VERSION ""

NS_ :

BS_:

BU_:

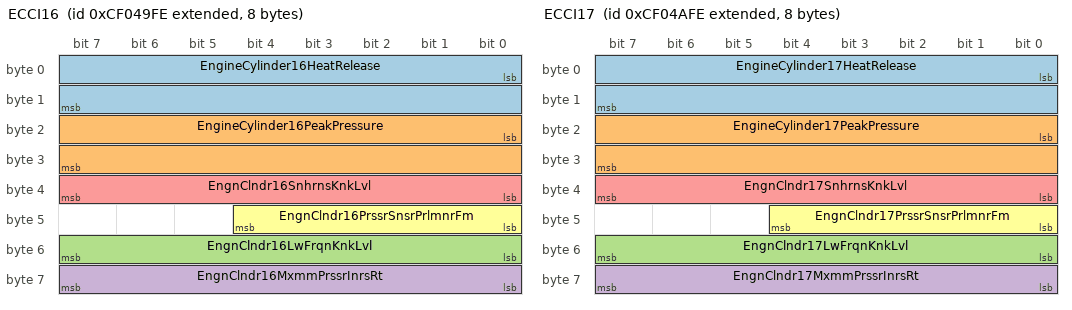
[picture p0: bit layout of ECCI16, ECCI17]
BO_ 2364557822 ECCI16: 8 Vector__XXX
 SG_ EngineCylinder16HeatRelease : 0|16@1+ (0.0001220703125,-1) [-1|6.8436279296875] "kJ/l" Vector__XXX
 SG_ EngineCylinder16PeakPressure : 16|16@1+ (0.0009765625,0) [0|62.7490234375] "MPa" Vector__XXX
 SG_ EngnClndr16LwFrqnKnkLvl : 48|8@1+ (1,0) [0|250] "%" Vector__XXX
 SG_ EngnClndr16MxmmPrssrInrsRt : 56|8@1+ (16,0) [0|4000] "kPa/deg crank angle" Vector__XXX
 SG_ EngnClndr16SnhrnsKnkLvl : 32|8@1+ (1,0) [0|250] "%" Vector__XXX
 SG_ EngnClndr16PrssrSnsrPrlmnrFm : 40|5@1+ (1,0) [0|31] "" Vector__XXX

BO_ 2364558078 ECCI17: 8 Vector__XXX
 SG_ EngineCylinder17HeatRelease : 0|16@1+ (0.0001220703125,-1) [-1|6.8436279296875] "kJ/l" Vector__XXX
 SG_ EngineCylinder17PeakPressure : 16|16@1+ (0.0009765625,0) [0|62.7490234375] "MPa" Vector__XXX
 SG_ EngnClndr17LwFrqnKnkLvl : 48|8@1+ (1,0) [0|250] "%" Vector__XXX
 SG_ EngnClndr17MxmmPrssrInrsRt : 56|8@1+ (16,0) [0|4000] "kPa/deg crank angle" Vector__XXX
 SG_ EngnClndr17SnhrnsKnkLvl : 32|8@1+ (1,0) [0|250] "%" Vector__XXX
 SG_ EngnClndr17PrssrSnsrPrlmnrFm : 40|5@1+ (1,0) [0|31] "" Vector__XXX

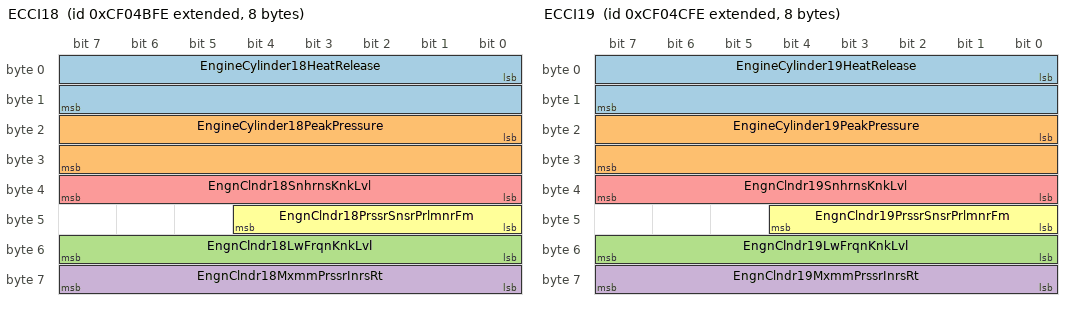
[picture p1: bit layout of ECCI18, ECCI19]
BO_ 2364558334 ECCI18: 8 Vector__XXX
 SG_ EngineCylinder18HeatRelease : 0|16@1+ (0.0001220703125,-1) [-1|6.8436279296875] "kJ/l" Vector__XXX
 SG_ EngineCylinder18PeakPressure : 16|16@1+ (0.0009765625,0) [0|62.7490234375] "MPa" Vector__XXX
 SG_ EngnClndr18LwFrqnKnkLvl : 48|8@1+ (1,0) [0|250] "%" Vector__XXX
 SG_ EngnClndr18MxmmPrssrInrsRt : 56|8@1+ (16,0) [0|4000] "kPa/deg crank angle" Vector__XXX
 SG_ EngnClndr18SnhrnsKnkLvl : 32|8@1+ (1,0) [0|250] "%" Vector__XXX
 SG_ EngnClndr18PrssrSnsrPrlmnrFm : 40|5@1+ (1,0) [0|31] "" Vector__XXX

BO_ 2364558590 ECCI19: 8 Vector__XXX
 SG_ EngineCylinder19HeatRelease : 0|16@1+ (0.0001220703125,-1) [-1|6.8436279296875] "kJ/l" Vector__XXX
 SG_ EngineCylinder19PeakPressure : 16|16@1+ (0.0009765625,0) [0|62.7490234375] "MPa" Vector__XXX
 SG_ EngnClndr19LwFrqnKnkLvl : 48|8@1+ (1,0) [0|250] "%" Vector__XXX
 SG_ EngnClndr19MxmmPrssrInrsRt : 56|8@1+ (16,0) [0|4000] "kPa/deg crank angle" Vector__XXX
 SG_ EngnClndr19SnhrnsKnkLvl : 32|8@1+ (1,0) [0|250] "%" Vector__XXX
 SG_ EngnClndr19PrssrSnsrPrlmnrFm : 40|5@1+ (1,0) [0|31] "" Vector__XXX

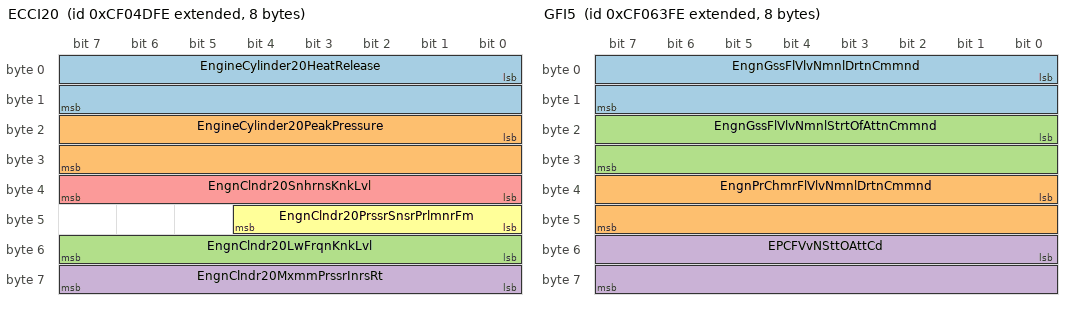
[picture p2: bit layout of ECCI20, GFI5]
BO_ 2364558846 ECCI20: 8 Vector__XXX
 SG_ EngineCylinder20HeatRelease : 0|16@1+ (0.0001220703125,-1) [-1|6.8436279296875] "kJ/l" Vector__XXX
 SG_ EngineCylinder20PeakPressure : 16|16@1+ (0.0009765625,0) [0|62.7490234375] "MPa" Vector__XXX
 SG_ EngnClndr20LwFrqnKnkLvl : 48|8@1+ (1,0) [0|250] "%" Vector__XXX
 SG_ EngnClndr20MxmmPrssrInrsRt : 56|8@1+ (16,0) [0|4000] "kPa/deg crank angle" Vector__XXX
 SG_ EngnClndr20SnhrnsKnkLvl : 32|8@1+ (1,0) [0|250] "%" Vector__XXX
 SG_ EngnClndr20PrssrSnsrPrlmnrFm : 40|5@1+ (1,0) [0|31] "" Vector__XXX

BO_ 2364564478 GFI5: 8 Vector__XXX
 SG_ EngnGssFlVlvNmnlDrtnCmmnd : 0|16@1+ (2,0) [0|128510] "micro s" Vector__XXX
 SG_ EngnPrChmrFlVlvNmnlDrtnCmmnd : 32|16@1+ (2,0) [0|128510] "micro s" Vector__XXX
 SG_ EngnGssFlVlvNmnlStrtOfAttnCmmnd : 16|16@1+ (0.0078125,-400) [-400|101.9921875] "deg" Vector__XXX
 SG_ EPCFVvNSttOAttCd : 48|16@1+ (0.0078125,-400) [-400|101.9921875] "deg" Vector__XXX

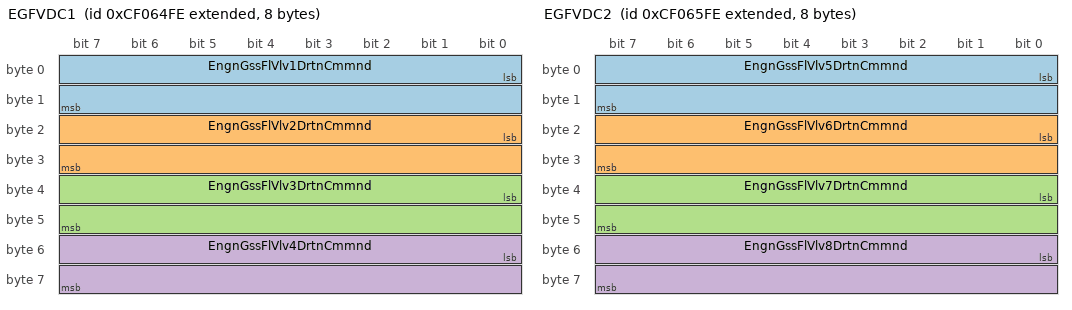
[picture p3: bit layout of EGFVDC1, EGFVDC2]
BO_ 2364564734 EGFVDC1: 8 Vector__XXX
 SG_ EngnGssFlVlv1DrtnCmmnd : 0|16@1+ (2,0) [0|128510] "micro s" Vector__XXX
 SG_ EngnGssFlVlv2DrtnCmmnd : 16|16@1+ (2,0) [0|128510] "micro s" Vector__XXX
 SG_ EngnGssFlVlv3DrtnCmmnd : 32|16@1+ (2,0) [0|128510] "micro s" Vector__XXX
 SG_ EngnGssFlVlv4DrtnCmmnd : 48|16@1+ (2,0) [0|128510] "micro s" Vector__XXX

BO_ 2364564990 EGFVDC2: 8 Vector__XXX
 SG_ EngnGssFlVlv5DrtnCmmnd : 0|16@1+ (2,0) [0|128510] "micro s" Vector__XXX
 SG_ EngnGssFlVlv6DrtnCmmnd : 16|16@1+ (2,0) [0|128510] "micro s" Vector__XXX
 SG_ EngnGssFlVlv7DrtnCmmnd : 32|16@1+ (2,0) [0|128510] "micro s" Vector__XXX
 SG_ EngnGssFlVlv8DrtnCmmnd : 48|16@1+ (2,0) [0|128510] "micro s" Vector__XXX

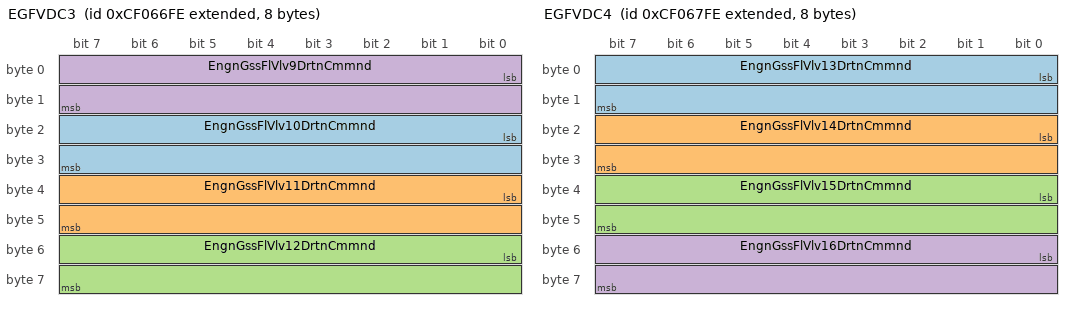
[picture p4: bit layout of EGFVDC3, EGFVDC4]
BO_ 2364565246 EGFVDC3: 8 Vector__XXX
 SG_ EngnGssFlVlv10DrtnCmmnd : 16|16@1+ (2,0) [0|128510] "micro s" Vector__XXX
 SG_ EngnGssFlVlv11DrtnCmmnd : 32|16@1+ (2,0) [0|128510] "micro s" Vector__XXX
 SG_ EngnGssFlVlv12DrtnCmmnd : 48|16@1+ (2,0) [0|128510] "micro s" Vector__XXX
 SG_ EngnGssFlVlv9DrtnCmmnd : 0|16@1+ (2,0) [0|128510] "micro s" Vector__XXX

BO_ 2364565502 EGFVDC4: 8 Vector__XXX
 SG_ EngnGssFlVlv13DrtnCmmnd : 0|16@1+ (2,0) [0|128510] "micro s" Vector__XXX
 SG_ EngnGssFlVlv14DrtnCmmnd : 16|16@1+ (2,0) [0|128510] "micro s" Vector__XXX
 SG_ EngnGssFlVlv15DrtnCmmnd : 32|16@1+ (2,0) [0|128510] "micro s" Vector__XXX
 SG_ EngnGssFlVlv16DrtnCmmnd : 48|16@1+ (2,0) [0|128510] "micro s" Vector__XXX

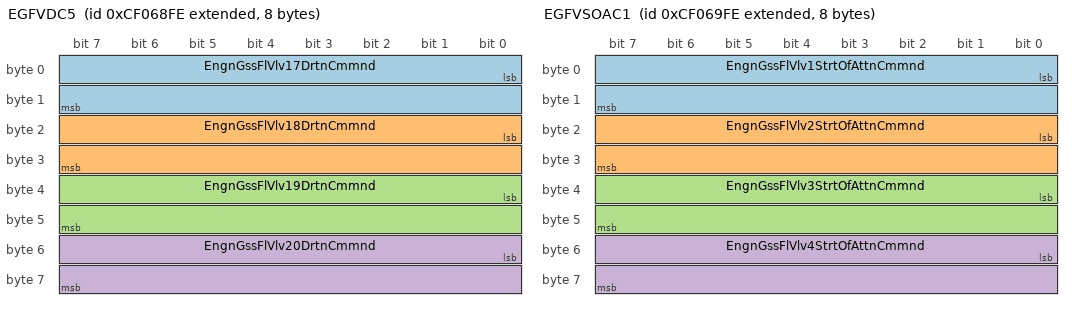
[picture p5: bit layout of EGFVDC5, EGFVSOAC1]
BO_ 2364565758 EGFVDC5: 8 Vector__XXX
 SG_ EngnGssFlVlv17DrtnCmmnd : 0|16@1+ (2,0) [0|128510] "micro s" Vector__XXX
 SG_ EngnGssFlVlv18DrtnCmmnd : 16|16@1+ (2,0) [0|128510] "micro s" Vector__XXX
 SG_ EngnGssFlVlv19DrtnCmmnd : 32|16@1+ (2,0) [0|128510] "micro s" Vector__XXX
 SG_ EngnGssFlVlv20DrtnCmmnd : 48|16@1+ (2,0) [0|128510] "micro s" Vector__XXX

BO_ 2364566014 EGFVSOAC1: 8 Vector__XXX
 SG_ EngnGssFlVlv1StrtOfAttnCmmnd : 0|16@1+ (0.0078125,-400) [-400|101.9921875] "deg" Vector__XXX
 SG_ EngnGssFlVlv2StrtOfAttnCmmnd : 16|16@1+ (0.0078125,-400) [-400|101.9921875] "deg" Vector__XXX
 SG_ EngnGssFlVlv3StrtOfAttnCmmnd : 32|16@1+ (0.0078125,-400) [-400|101.9921875] "deg" Vector__XXX
 SG_ EngnGssFlVlv4StrtOfAttnCmmnd : 48|16@1+ (0.0078125,-400) [-400|101.9921875] "deg" Vector__XXX

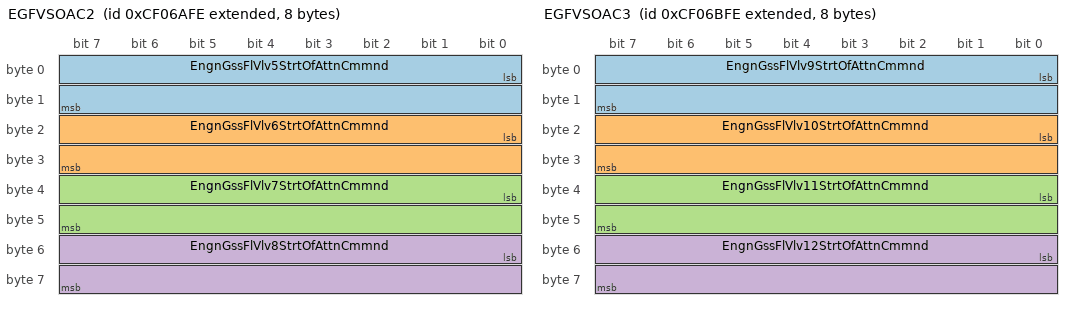
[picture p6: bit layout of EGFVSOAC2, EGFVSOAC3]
BO_ 2364566270 EGFVSOAC2: 8 Vector__XXX
 SG_ EngnGssFlVlv5StrtOfAttnCmmnd : 0|16@1+ (0.0078125,-400) [-400|101.9921875] "deg" Vector__XXX
 SG_ EngnGssFlVlv6StrtOfAttnCmmnd : 16|16@1+ (0.0078125,-400) [-400|101.9921875] "deg" Vector__XXX
 SG_ EngnGssFlVlv7StrtOfAttnCmmnd : 32|16@1+ (0.0078125,-400) [-400|101.9921875] "deg" Vector__XXX
 SG_ EngnGssFlVlv8StrtOfAttnCmmnd : 48|16@1+ (0.0078125,-400) [-400|101.9921875] "deg" Vector__XXX

BO_ 2364566526 EGFVSOAC3: 8 Vector__XXX
 SG_ EngnGssFlVlv9StrtOfAttnCmmnd : 0|16@1+ (0.0078125,-400) [-400|101.9921875] "deg" Vector__XXX
 SG_ EngnGssFlVlv10StrtOfAttnCmmnd : 16|16@1+ (0.0078125,-400) [-400|101.9921875] "deg" Vector__XXX
 SG_ EngnGssFlVlv11StrtOfAttnCmmnd : 32|16@1+ (0.0078125,-400) [-400|101.9921875] "deg" Vector__XXX
 SG_ EngnGssFlVlv12StrtOfAttnCmmnd : 48|16@1+ (0.0078125,-400) [-400|101.9921875] "deg" Vector__XXX

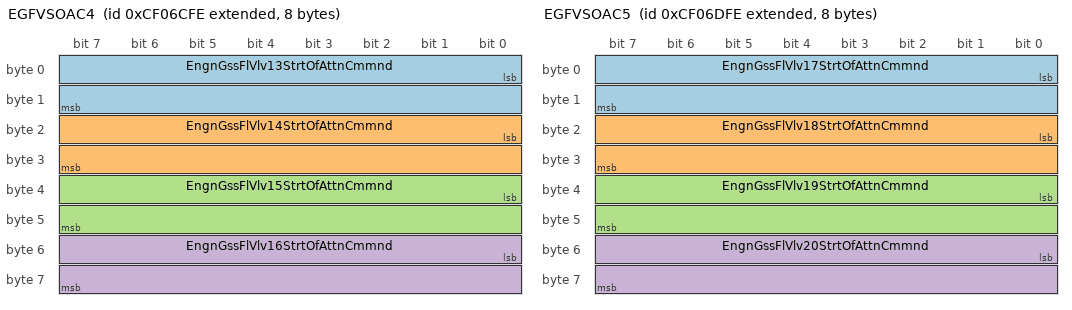
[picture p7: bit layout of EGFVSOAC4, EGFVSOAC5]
BO_ 2364566782 EGFVSOAC4: 8 Vector__XXX
 SG_ EngnGssFlVlv13StrtOfAttnCmmnd : 0|16@1+ (0.0078125,-400) [-400|101.9921875] "deg" Vector__XXX
 SG_ EngnGssFlVlv14StrtOfAttnCmmnd : 16|16@1+ (0.0078125,-400) [-400|101.9921875] "deg" Vector__XXX
 SG_ EngnGssFlVlv15StrtOfAttnCmmnd : 32|16@1+ (0.0078125,-400) [-400|101.9921875] "deg" Vector__XXX
 SG_ EngnGssFlVlv16StrtOfAttnCmmnd : 48|16@1+ (0.0078125,-400) [-400|101.9921875] "deg" Vector__XXX

BO_ 2364567038 EGFVSOAC5: 8 Vector__XXX
 SG_ EngnGssFlVlv17StrtOfAttnCmmnd : 0|16@1+ (0.0078125,-400) [-400|101.9921875] "deg" Vector__XXX
 SG_ EngnGssFlVlv18StrtOfAttnCmmnd : 16|16@1+ (0.0078125,-400) [-400|101.9921875] "deg" Vector__XXX
 SG_ EngnGssFlVlv19StrtOfAttnCmmnd : 32|16@1+ (0.0078125,-400) [-400|101.9921875] "deg" Vector__XXX
 SG_ EngnGssFlVlv20StrtOfAttnCmmnd : 48|16@1+ (0.0078125,-400) [-400|101.9921875] "deg" Vector__XXX

BO_ 2364567294 FPAC: 8 Vector__XXX
 SG_ EngnFlInjtnPmp1FlCntrlVlvCmmnd : 0|16@1+ (0.0025,0) [0|100] "%" Vector__XXX
 SG_ EngnFlInjtnPmp2FlCntrlVlvCmmnd : 16|16@1+ (0.0025,0) [0|100] "%" Vector__XXX

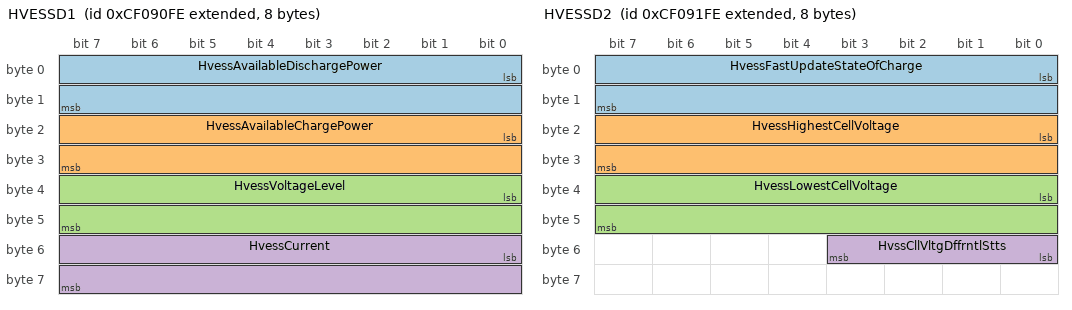
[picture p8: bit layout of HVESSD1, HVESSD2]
BO_ 2364575998 HVESSD1: 8 Vector__XXX
 SG_ HvessAvailableDischargePower : 0|16@1+ (0.05,0) [0|3212.75] "kW" Vector__XXX
 SG_ HvessAvailableChargePower : 16|16@1+ (0.05,0) [0|3212.75] "kW" Vector__XXX
 SG_ HvessVoltageLevel : 32|16@1+ (0.05,0) [0|3212.75] "V" Vector__XXX
 SG_ HvessCurrent : 48|16@1+ (0.05,-1600) [-1600|1612.75] "A" Vector__XXX

BO_ 2364576254 HVESSD2: 8 Vector__XXX
 SG_ HvessFastUpdateStateOfCharge : 0|16@1+ (0.0015625,0) [0|100.3984375] "%" Vector__XXX
 SG_ HvessHighestCellVoltage : 16|16@1+ (0.001,0) [0|64.255] "V" Vector__XXX
 SG_ HvessLowestCellVoltage : 32|16@1+ (0.001,0) [0|64.255] "V" Vector__XXX
 SG_ HvssCllVltgDffrntlStts : 48|4@1+ (1,0) [0|15] "" Vector__XXX

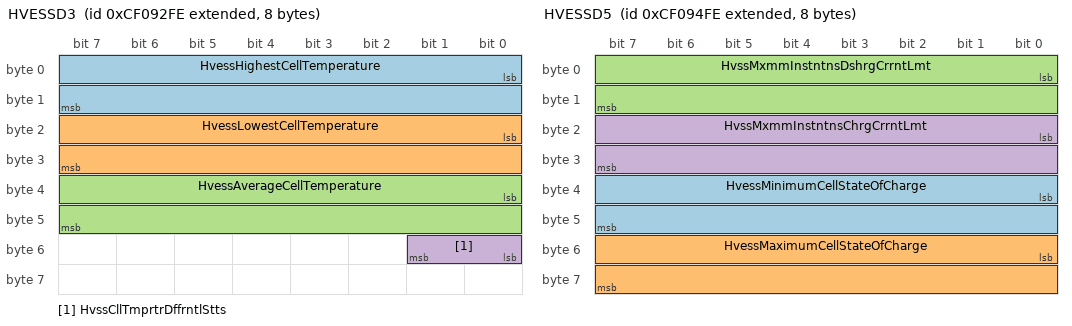
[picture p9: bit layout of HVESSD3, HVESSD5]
BO_ 2364576510 HVESSD3: 8 Vector__XXX
 SG_ HvessHighestCellTemperature : 0|16@1+ (0.03125,-273) [-273|1734.96875] "degC" Vector__XXX
 SG_ HvessLowestCellTemperature : 16|16@1+ (0.03125,-273) [-273|1734.96875] "degC" Vector__XXX
 SG_ HvessAverageCellTemperature : 32|16@1+ (0.03125,-273) [-273|1734.96875] "degC" Vector__XXX
 SG_ HvssCllTmprtrDffrntlStts : 48|2@1+ (1,0) [0|3] "" Vector__XXX

BO_ 2364576766 HVESSD4: 8 Vector__XXX
 SG_ HvessDischargeCapacity : 0|16@1+ (0.01,0) [0|642.55] "Ah" Vector__XXX
 SG_ HvessChargeCapacity : 16|16@1+ (0.01,0) [0|642.55] "Ah" Vector__XXX
 SG_ HvessCellBalancingCount : 32|16@1+ (1,0) [0|64255] "count" Vector__XXX

BO_ 2364577022 HVESSD5: 8 Vector__XXX
 SG_ HvessMinimumCellStateOfCharge : 32|16@1+ (0.0015625,0) [0|100.3984375] "%" Vector__XXX
 SG_ HvessMaximumCellStateOfCharge : 48|16@1+ (0.0015625,0) [0|100.3984375] "%" Vector__XXX
 SG_ HvssMxmmInstntnsDshrgCrrntLmt : 0|16@1+ (0.05,-1600) [-1600|0] "A" Vector__XXX
 SG_ HvssMxmmInstntnsChrgCrrntLmt : 16|16@1+ (0.05,-1600) [0|1612.75] "A" Vector__XXX

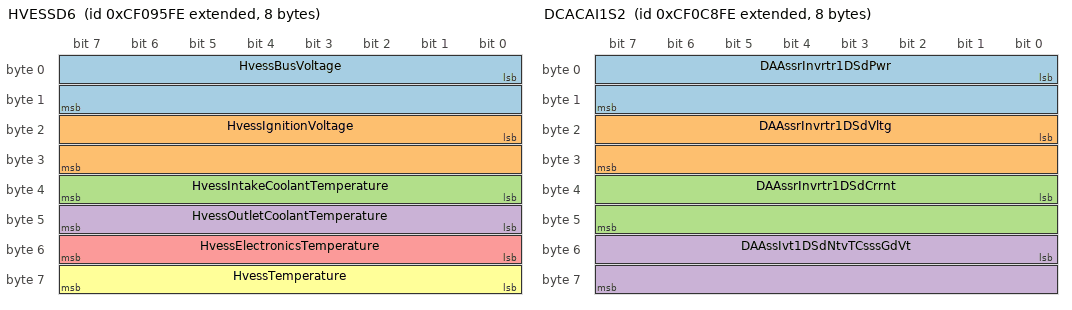
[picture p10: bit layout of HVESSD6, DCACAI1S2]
BO_ 2364577278 HVESSD6: 8 Vector__XXX
 SG_ HvessBusVoltage : 0|16@1+ (0.05,0) [0|3212.75] "V" Vector__XXX
 SG_ HvessIgnitionVoltage : 16|16@1+ (0.01,0) [0|642.55] "V" Vector__XXX
 SG_ HvessIntakeCoolantTemperature : 32|8@1+ (1,-40) [-40|210] "degC" Vector__XXX
 SG_ HvessOutletCoolantTemperature : 40|8@1+ (1,-40) [-40|210] "degC" Vector__XXX
 SG_ HvessElectronicsTemperature : 48|8@1+ (1,-40) [-40|210] "degC" Vector__XXX
 SG_ HvessTemperature : 56|8@1+ (1,-40) [-40|210] "degC" Vector__XXX

BO_ 2364577534 HVESSS1: 8 Vector__XXX
 SG_ HvessCenterOfPackContactorState : 10|2@1+ (1,0) [0|3] "" Vector__XXX
 SG_ HvessHvilStatus : 20|2@1+ (1,0) [0|3] "" Vector__XXX
 SG_ HvessInertiaSwitchStatus : 22|2@1+ (1,0) [0|3] "" Vector__XXX
 SG_ HvessStateOfChargeStatus : 24|4@1+ (1,0) [0|15] "" Vector__XXX
 SG_ HvessCellBalanceStatus : 28|2@1+ (1,0) [0|3] "" Vector__XXX
 SG_ HvessCellBalancingActive : 30|2@1+ (1,0) [0|3] "" Vector__XXX
 SG_ HvessInternalChargerStatus : 32|2@1+ (1,0) [0|3] "" Vector__XXX
 SG_ HvessOperationalStatus : 44|4@1+ (1,0) [0|15] "" Vector__XXX
 SG_ HvessNumberOfHvespsReady : 48|8@1+ (1,0) [0|250] "count" Vector__XXX
 SG_ HvessStatus1Counter : 36|4@1+ (1,0) [0|15] "" Vector__XXX
 SG_ HvessStatus1Crc : 56|8@1+ (1,0) [0|250] "count" Vector__XXX
 SG_ HvssHghVltgBsPstvCnttrStt : 0|2@1+ (1,0) [0|3] "" Vector__XXX
 SG_ HvssHghVltgBsNgtvCnttrStt : 2|2@1+ (1,0) [0|3] "" Vector__XXX
 SG_ HvssHghVltgBsDsnntFrwrnng : 4|4@1+ (1,0) [0|15] "" Vector__XXX
 SG_ HvssHghVltgBsPrChrgRlStt : 8|2@1+ (1,0) [0|3] "" Vector__XXX
 SG_ HvssHghVltgBsAtvIsltnTstStts : 12|4@1+ (1,0) [0|15] "" Vector__XXX
 SG_ HvssHghVltgBsPssvIsltnTstStts : 16|4@1+ (1,0) [0|15] "" Vector__XXX
 SG_ HvssHghVltgBsCnntnStts : 40|4@1+ (1,0) [0|15] "" Vector__XXX

BO_ 2364580094 HVESSD7: 8 Vector__XXX
 SG_ HvessDischargeEnergyCapacity : 0|24@1+ (0.001,0) [0|16449.535] "kWh" Vector__XXX
 SG_ HvessChargeEnergyCapacity : 24|24@1+ (0.001,0) [0|16449.535] "kWh" Vector__XXX
 SG_ HvessMaximumChargeVoltageLimit : 48|16@1+ (0.05,0) [0|3212.75] "V" Vector__XXX

BO_ 2364590334 DCACAI1S2: 8 Vector__XXX
 SG_ DAAssrInvrtr1DSdPwr : 0|16@1+ (0.0625,0) [0|4015.9375] "kW" Vector__XXX
 SG_ DAAssrInvrtr1DSdVltg : 16|16@1+ (0.05,0) [0|3212.75] "V" Vector__XXX
 SG_ DAAssrInvrtr1DSdCrrnt : 32|16@1+ (0.0625,0) [0|4015.9375] "A" Vector__XXX
 SG_ DAAssIvt1DSdNtvTCsssGdVt : 48|16@1+ (0.05,0) [0|3212.75] "V" Vector__XXX

BO_ 2364590590 DCACAI1V: 8 Vector__XXX
 SG_ DAAssrInvrtr1IgntnVltg : 0|16@1+ (0.05,0) [0|3212.75] "V" Vector__XXX
 SG_ DAAssrInvrtr1UnswthdSlVltg : 16|16@1+ (0.05,0) [0|3212.75] "V" Vector__XXX

BO_ 2364591102 DCACAI2S2: 8 Vector__XXX
 SG_ DAAssrInvrtr2DSdPwr : 0|16@1+ (0.0625,0) [0|4015.9375] "kW" Vector__XXX
 SG_ DAAssrInvrtr2DSdVltg : 16|16@1+ (0.05,0) [0|3212.75] "V" Vector__XXX
 SG_ DAAssrInvrtr2DSdCrrnt : 32|16@1+ (0.0625,0) [0|4015.9375] "A" Vector__XXX
 SG_ DAAssIvt2DSdNtvTCsssGdVt : 48|16@1+ (0.05,0) [0|3212.75] "V" Vector__XXX

BO_ 2364591358 DCACAI2V: 8 Vector__XXX
 SG_ DAAssrInvrtr2IgntnVltg : 0|16@1+ (0.05,0) [0|3212.75] "V" Vector__XXX
 SG_ DAAssrInvrtr2UnswthdSlVltg : 16|16@1+ (0.05,0) [0|3212.75] "V" Vector__XXX

BO_ 2364592382 ECCR: 8 Vector__XXX
 SG_ EngnClndr10ExldFrmCmstnRqst : 26|2@1+ (1,0) [0|3] "" Vector__XXX
 SG_ EngnClndr11ExldFrmCmstnRqst : 28|2@1+ (1,0) [0|3] "" Vector__XXX
 SG_ EngnClndr12ExldFrmCmstnRqst : 30|2@1+ (1,0) [0|3] "" Vector__XXX
 SG_ EngnClndr13ExldFrmCmstnRqst : 32|2@1+ (1,0) [0|3] "" Vector__XXX
 SG_ EngnClndr14ExldFrmCmstnRqst : 34|2@1+ (1,0) [0|3] "" Vector__XXX
 SG_ EngnClndr15ExldFrmCmstnRqst : 36|2@1+ (1,0) [0|3] "" Vector__XXX
 SG_ EngnClndr16ExldFrmCmstnRqst : 38|2@1+ (1,0) [0|3] "" Vector__XXX
 SG_ EngnClndr17ExldFrmCmstnRqst : 40|2@1+ (1,0) [0|3] "" Vector__XXX
 SG_ EngnClndr18ExldFrmCmstnRqst : 42|2@1+ (1,0) [0|3] "" Vector__XXX
 SG_ EngnClndr19ExldFrmCmstnRqst : 44|2@1+ (1,0) [0|3] "" Vector__XXX
 SG_ EngnClndr1ExldFrmCmstnRqst : 8|2@1+ (1,0) [0|3] "" Vector__XXX
 SG_ EngnClndr20ExldFrmCmstnRqst : 46|2@1+ (1,0) [0|3] "" Vector__XXX
 SG_ EngnClndr21ExldFrmCmstnRqst : 48|2@1+ (1,0) [0|3] "" Vector__XXX
 SG_ EngnClndr22ExldFrmCmstnRqst : 50|2@1+ (1,0) [0|3] "" Vector__XXX
 SG_ EngnClndr23ExldFrmCmstnRqst : 52|2@1+ (1,0) [0|3] "" Vector__XXX
 SG_ EngnClndr24ExldFrmCmstnRqst : 54|2@1+ (1,0) [0|3] "" Vector__XXX
 SG_ EngnClndr2ExldFrmCmstnRqst : 10|2@1+ (1,0) [0|3] "" Vector__XXX
 SG_ EngnClndr3ExldFrmCmstnRqst : 12|2@1+ (1,0) [0|3] "" Vector__XXX
 SG_ EngnClndr4ExldFrmCmstnRqst : 14|2@1+ (1,0) [0|3] "" Vector__XXX
 SG_ EngnClndr5ExldFrmCmstnRqst : 16|2@1+ (1,0) [0|3] "" Vector__XXX
 SG_ EngnClndr6ExldFrmCmstnRqst : 18|2@1+ (1,0) [0|3] "" Vector__XXX
 SG_ EngnClndr7ExldFrmCmstnRqst : 20|2@1+ (1,0) [0|3] "" Vector__XXX
 SG_ EngnClndr8ExldFrmCmstnRqst : 22|2@1+ (1,0) [0|3] "" Vector__XXX
 SG_ EngnClndr9ExldFrmCmstnRqst : 24|2@1+ (1,0) [0|3] "" Vector__XXX
 SG_ NmrOfEngnClndrsTExldFrmCmstn : 0|8@1+ (1,0) [0|24] "count" Vector__XXX

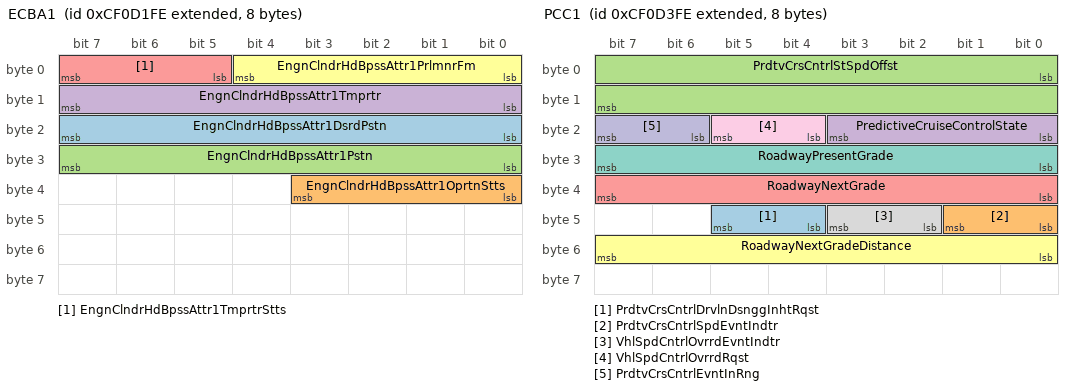
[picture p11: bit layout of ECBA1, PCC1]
BO_ 2364592638 ECBA1: 8 Vector__XXX
 SG_ EngnClndrHdBpssAttr1DsrdPstn : 16|8@1+ (0.4,0) [0|100] "%" Vector__XXX
 SG_ EngnClndrHdBpssAttr1OprtnStts : 32|4@1+ (1,0) [0|15] "" Vector__XXX
 SG_ EngnClndrHdBpssAttr1Pstn : 24|8@1+ (0.4,0) [0|100] "%" Vector__XXX
 SG_ EngnClndrHdBpssAttr1Tmprtr : 8|8@1+ (1,-40) [-40|210] "degC" Vector__XXX
 SG_ EngnClndrHdBpssAttr1TmprtrStts : 5|3@1+ (1,0) [0|7] "" Vector__XXX
 SG_ EngnClndrHdBpssAttr1PrlmnrFm : 0|5@1+ (1,0) [0|31] "" Vector__XXX

BO_ 2364592894 EEC18: 8 Vector__XXX
 SG_ EngineIntakeAirSourceValve : 16|2@1+ (1,0) [0|3] "" Vector__XXX
 SG_ EngnClndrHdBpssAttr1Cmmnd : 0|16@1+ (0.0025,0) [0|160.6375] "%" Vector__XXX
 SG_ EngnExhstGsRstrtnVlvPstn : 32|16@1+ (0.0025,0) [0|160.6375] "%" Vector__XXX

BO_ 2364593150 PCC1: 8 Vector__XXX
 SG_ PrdtvCrsCntrlDrvlnDsnggInhtRqst : 44|2@1+ (1,0) [0|3] "" Vector__XXX
 SG_ PrdtvCrsCntrlSpdEvntIndtr : 40|2@1+ (1,0) [0|3] "" Vector__XXX
 SG_ PrdtvCrsCntrlStSpdOffst : 0|16@1+ (0.00390625,-125) [-125|125.99609375] "km/h" Vector__XXX
 SG_ PredictiveCruiseControlState : 16|4@1+ (1,0) [0|15] "" Vector__XXX
 SG_ RoadwayNextGrade : 32|8@1+ (0.125,-16) [-16|15.25] "%" Vector__XXX
 SG_ RoadwayNextGradeDistance : 48|8@1+ (25,0) [0|6250] "m" Vector__XXX
 SG_ RoadwayPresentGrade : 24|8@1+ (0.125,-16) [-16|15.25] "%" Vector__XXX
 SG_ VhlSpdCntrlOvrrdEvntIndtr : 42|2@1+ (1,0) [0|3] "" Vector__XXX
 SG_ VhlSpdCntrlOvrrdRqst : 20|2@1+ (1,0) [0|3] "" Vector__XXX
 SG_ PrdtvCrsCntrlEvntInRng : 22|2@1+ (1,0) [0|3] "" Vector__XXX

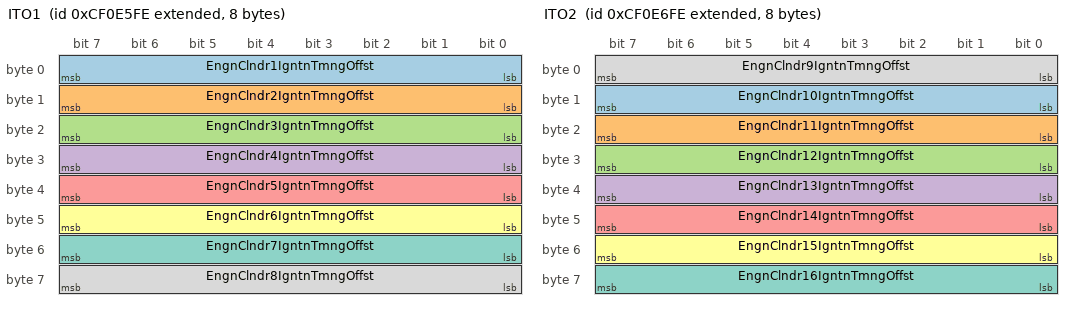
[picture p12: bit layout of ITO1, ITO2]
BO_ 2364597758 ITO1: 8 Vector__XXX
 SG_ EngnClndr1IgntnTmngOffst : 0|8@1+ (0.1,-12.5) [-12.5|12.5] "deg" Vector__XXX
 SG_ EngnClndr2IgntnTmngOffst : 8|8@1+ (0.1,-12.5) [-12.5|12.5] "deg" Vector__XXX
 SG_ EngnClndr3IgntnTmngOffst : 16|8@1+ (0.1,-12.5) [-12.5|12.5] "deg" Vector__XXX
 SG_ EngnClndr4IgntnTmngOffst : 24|8@1+ (0.1,-12.5) [-12.5|12.5] "deg" Vector__XXX
 SG_ EngnClndr5IgntnTmngOffst : 32|8@1+ (0.1,-12.5) [-12.5|12.5] "deg" Vector__XXX
 SG_ EngnClndr6IgntnTmngOffst : 40|8@1+ (0.1,-12.5) [-12.5|12.5] "deg" Vector__XXX
 SG_ EngnClndr7IgntnTmngOffst : 48|8@1+ (0.1,-12.5) [-12.5|12.5] "deg" Vector__XXX
 SG_ EngnClndr8IgntnTmngOffst : 56|8@1+ (0.1,-12.5) [-12.5|12.5] "deg" Vector__XXX

BO_ 2364598014 ITO2: 8 Vector__XXX
 SG_ EngnClndr10IgntnTmngOffst : 8|8@1+ (0.1,-12.5) [-12.5|12.5] "deg" Vector__XXX
 SG_ EngnClndr11IgntnTmngOffst : 16|8@1+ (0.1,-12.5) [-12.5|12.5] "deg" Vector__XXX
 SG_ EngnClndr12IgntnTmngOffst : 24|8@1+ (0.1,-12.5) [-12.5|12.5] "deg" Vector__XXX
 SG_ EngnClndr13IgntnTmngOffst : 32|8@1+ (0.1,-12.5) [-12.5|12.5] "deg" Vector__XXX
 SG_ EngnClndr14IgntnTmngOffst : 40|8@1+ (0.1,-12.5) [-12.5|12.5] "deg" Vector__XXX
 SG_ EngnClndr15IgntnTmngOffst : 48|8@1+ (0.1,-12.5) [-12.5|12.5] "deg" Vector__XXX
 SG_ EngnClndr16IgntnTmngOffst : 56|8@1+ (0.1,-12.5) [-12.5|12.5] "deg" Vector__XXX
 SG_ EngnClndr9IgntnTmngOffst : 0|8@1+ (0.1,-12.5) [-12.5|12.5] "deg" Vector__XXX

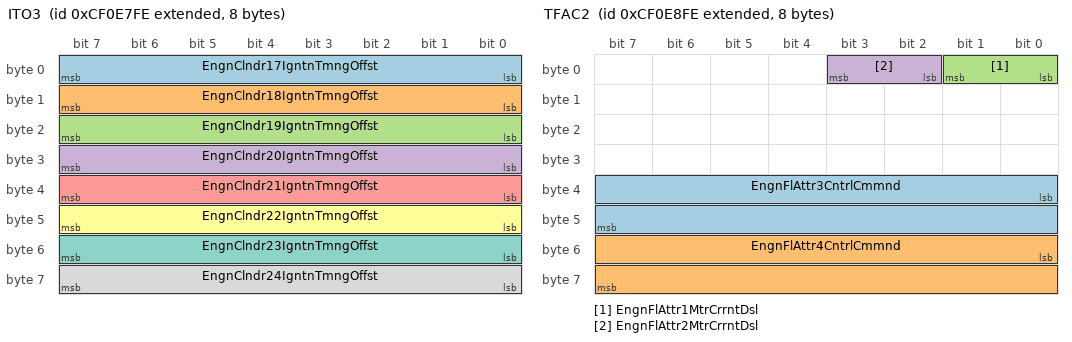
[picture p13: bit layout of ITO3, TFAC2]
BO_ 2364598270 ITO3: 8 Vector__XXX
 SG_ EngnClndr17IgntnTmngOffst : 0|8@1+ (0.1,-12.5) [-12.5|12.5] "deg" Vector__XXX
 SG_ EngnClndr18IgntnTmngOffst : 8|8@1+ (0.1,-12.5) [-12.5|12.5] "deg" Vector__XXX
 SG_ EngnClndr19IgntnTmngOffst : 16|8@1+ (0.1,-12.5) [-12.5|12.5] "deg" Vector__XXX
 SG_ EngnClndr20IgntnTmngOffst : 24|8@1+ (0.1,-12.5) [-12.5|12.5] "deg" Vector__XXX
 SG_ EngnClndr21IgntnTmngOffst : 32|8@1+ (0.1,-12.5) [-12.5|12.5] "deg" Vector__XXX
 SG_ EngnClndr22IgntnTmngOffst : 40|8@1+ (0.1,-12.5) [-12.5|12.5] "deg" Vector__XXX
 SG_ EngnClndr23IgntnTmngOffst : 48|8@1+ (0.1,-12.5) [-12.5|12.5] "deg" Vector__XXX
 SG_ EngnClndr24IgntnTmngOffst : 56|8@1+ (0.1,-12.5) [-12.5|12.5] "deg" Vector__XXX

BO_ 2364598526 TFAC2: 8 Vector__XXX
 SG_ EngnFlAttr3CntrlCmmnd : 32|16@1+ (0.0025,0) [0|100] "%" Vector__XXX
 SG_ EngnFlAttr4CntrlCmmnd : 48|16@1+ (0.0025,0) [0|160.6375] "%" Vector__XXX
 SG_ EngnFlAttr1MtrCrrntDsl : 0|2@1+ (1,0) [0|3] "" Vector__XXX
 SG_ EngnFlAttr2MtrCrrntDsl : 2|2@1+ (1,0) [0|3] "" Vector__XXX

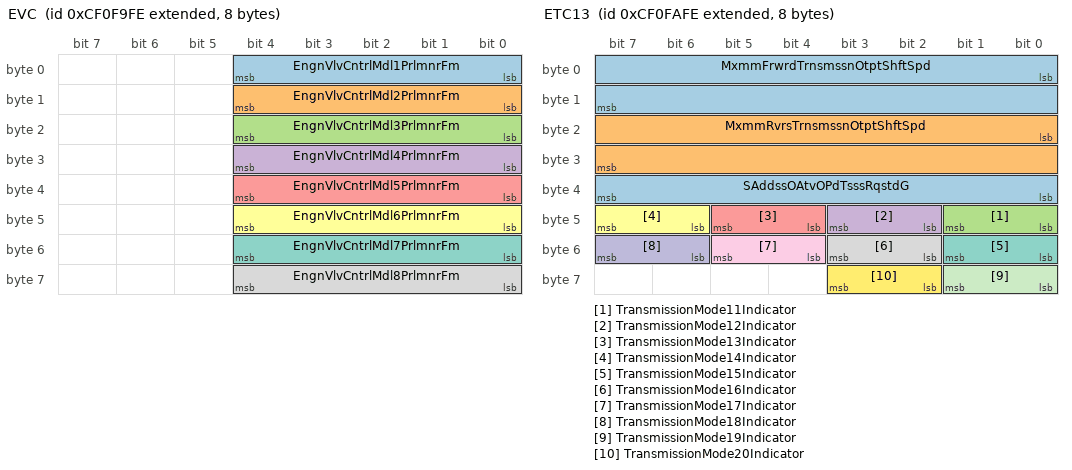
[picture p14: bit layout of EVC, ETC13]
BO_ 2364602878 EVC: 8 Vector__XXX
 SG_ EngnVlvCntrlMdl1PrlmnrFm : 0|5@1+ (1,0) [0|31] "" Vector__XXX
 SG_ EngnVlvCntrlMdl2PrlmnrFm : 8|5@1+ (1,0) [0|31] "" Vector__XXX
 SG_ EngnVlvCntrlMdl3PrlmnrFm : 16|5@1+ (1,0) [0|31] "" Vector__XXX
 SG_ EngnVlvCntrlMdl4PrlmnrFm : 24|5@1+ (1,0) [0|31] "" Vector__XXX
 SG_ EngnVlvCntrlMdl5PrlmnrFm : 32|5@1+ (1,0) [0|31] "" Vector__XXX
 SG_ EngnVlvCntrlMdl6PrlmnrFm : 40|5@1+ (1,0) [0|31] "" Vector__XXX
 SG_ EngnVlvCntrlMdl7PrlmnrFm : 48|5@1+ (1,0) [0|31] "" Vector__XXX
 SG_ EngnVlvCntrlMdl8PrlmnrFm : 56|5@1+ (1,0) [0|31] "" Vector__XXX

BO_ 2364603134 ETC13: 8 Vector__XXX
 SG_ MxmmFrwrdTrnsmssnOtptShftSpd : 0|16@1+ (0.125,0) [0|8031.875] "rpm" Vector__XXX
 SG_ MxmmRvrsTrnsmssnOtptShftSpd : 16|16@1+ (0.125,0) [0|8031.875] "rpm" Vector__XXX
 SG_ TransmissionMode11Indicator : 40|2@1+ (1,0) [0|3] "" Vector__XXX
 SG_ TransmissionMode12Indicator : 42|2@1+ (1,0) [0|3] "" Vector__XXX
 SG_ TransmissionMode13Indicator : 44|2@1+ (1,0) [0|3] "" Vector__XXX
 SG_ TransmissionMode14Indicator : 46|2@1+ (1,0) [0|3] "" Vector__XXX
 SG_ TransmissionMode15Indicator : 48|2@1+ (1,0) [0|3] "" Vector__XXX
 SG_ TransmissionMode16Indicator : 50|2@1+ (1,0) [0|3] "" Vector__XXX
 SG_ TransmissionMode17Indicator : 52|2@1+ (1,0) [0|3] "" Vector__XXX
 SG_ TransmissionMode18Indicator : 54|2@1+ (1,0) [0|3] "" Vector__XXX
 SG_ TransmissionMode19Indicator : 56|2@1+ (1,0) [0|3] "" Vector__XXX
 SG_ TransmissionMode20Indicator : 58|2@1+ (1,0) [0|3] "" Vector__XXX
 SG_ SAddssOAtvOPdTsssRqstdG : 32|8@1+ (1,0) [0|253] "sourceadr" Vector__XXX

BO_ 2364603390 A1SCRDSR3: 8 Vector__XXX
 SG_ Atttt1DsExstFdDsVv1Cd : 16|16@1+ (0.0025,0) [0|100] "%" Vector__XXX
 SG_ Atttt1DsExstFdRqstdQttOIttHRst : 0|16@1+ (0.001,0) [0|64.255] "g" Vector__XXX
 SG_ Atttt1DsExstFdDsVv2Cd : 32|16@1+ (0.0025,0) [0|100] "%" Vector__XXX

BO_ 2364603646 A2SCRDSR3: 8 Vector__XXX
 SG_ Atttt2DsExstFdRqstdQttOIttHRst : 0|16@1+ (0.001,0) [0|64.255] "g" Vector__XXX
 SG_ Atttt2DsExstFdDsVv1Cd : 16|16@1+ (0.0025,0) [0|160.6375] "%" Vector__XXX
 SG_ Atttt2DsExstFdDsVv2Cd : 32|16@1+ (0.0025,0) [0|160.6375] "%" Vector__XXX

BO_ 2364603902 A1SCRDSI4: 8 Vector__XXX
 SG_ Atttt1DsExstFdAtQttOIttHRst : 0|16@1+ (0.001,0) [0|64.255] "g" Vector__XXX

BO_ 2364604158 A2SCRDSI4: 8 Vector__XXX
 SG_ Atttt2DsExstFdAtQttOIttHRst : 0|16@1+ (0.001,0) [0|64.255] "g" Vector__XXX

BO_ 2364605438 GTRACE: 8 Vector__XXX
 SG_ GeneratorTripKvarHoursExport : 32|32@1+ (1,0) [0|4211081215] "kVArh" Vector__XXX
 SG_ GeneratorTripKwHoursExport : 0|32@1+ (1,0) [0|4211081215] "kWh" Vector__XXX

BO_ 2364605950 HPD: 8 Vector__XXX
 SG_ HydraulicLinePressure : 0|16@1+ (1,0) [0|64255] "kPa" Vector__XXX
 SG_ MechanicalMovementAngle : 16|16@1+ (0.0078125,0) [0|359.99] "deg" Vector__XXX

BO_ 2364606718 HVESSMS1: 8 Vector__XXX
 SG_ HvessModule1OperationalStatus : 0|2@1+ (1,0) [0|3] "" Vector__XXX
 SG_ HvessModule2OperationalStatus : 2|2@1+ (1,0) [0|3] "" Vector__XXX
 SG_ HvessModule3OperationalStatus : 4|2@1+ (1,0) [0|3] "" Vector__XXX
 SG_ HvessModule4OperationalStatus : 6|2@1+ (1,0) [0|3] "" Vector__XXX
 SG_ HvessModule5OperationalStatus : 8|2@1+ (1,0) [0|3] "" Vector__XXX
 SG_ HvessModule6OperationalStatus : 10|2@1+ (1,0) [0|3] "" Vector__XXX
 SG_ HvessModule7OperationalStatus : 12|2@1+ (1,0) [0|3] "" Vector__XXX
 SG_ HvessModule8OperationalStatus : 14|2@1+ (1,0) [0|3] "" Vector__XXX
 SG_ HvessModule9OperationalStatus : 16|2@1+ (1,0) [0|3] "" Vector__XXX
 SG_ HvessModule10OperationalStatus : 18|2@1+ (1,0) [0|3] "" Vector__XXX
 SG_ HvessModule11OperationalStatus : 20|2@1+ (1,0) [0|3] "" Vector__XXX
 SG_ HvessModule12OperationalStatus : 22|2@1+ (1,0) [0|3] "" Vector__XXX
 SG_ HvessModule13OperationalStatus : 24|2@1+ (1,0) [0|3] "" Vector__XXX
 SG_ HvessModule14OperationalStatus : 26|2@1+ (1,0) [0|3] "" Vector__XXX
 SG_ HvessModule15OperationalStatus : 28|2@1+ (1,0) [0|3] "" Vector__XXX
 SG_ HvessModule16OperationalStatus : 30|2@1+ (1,0) [0|3] "" Vector__XXX
 SG_ HvessModule17OperationalStatus : 32|2@1+ (1,0) [0|3] "" Vector__XXX
 SG_ HvessModule18OperationalStatus : 34|2@1+ (1,0) [0|3] "" Vector__XXX
 SG_ HvessModule19OperationalStatus : 36|2@1+ (1,0) [0|3] "" Vector__XXX
 SG_ HvessModule20OperationalStatus : 38|2@1+ (1,0) [0|3] "" Vector__XXX
 SG_ HvessModule21OperationalStatus : 40|2@1+ (1,0) [0|3] "" Vector__XXX
 SG_ HvessModule22OperationalStatus : 42|2@1+ (1,0) [0|3] "" Vector__XXX
 SG_ HvessModule23OperationalStatus : 44|2@1+ (1,0) [0|3] "" Vector__XXX
 SG_ HvessModule24OperationalStatus : 46|2@1+ (1,0) [0|3] "" Vector__XXX
 SG_ HvessModule25OperationalStatus : 48|2@1+ (1,0) [0|3] "" Vector__XXX
 SG_ HvessModule26OperationalStatus : 50|2@1+ (1,0) [0|3] "" Vector__XXX
 SG_ HvessModule27OperationalStatus : 52|2@1+ (1,0) [0|3] "" Vector__XXX
 SG_ HvessModule28OperationalStatus : 54|2@1+ (1,0) [0|3] "" Vector__XXX
 SG_ HvessModule29OperationalStatus : 56|2@1+ (1,0) [0|3] "" Vector__XXX
 SG_ HvessModule30OperationalStatus : 58|2@1+ (1,0) [0|3] "" Vector__XXX
 SG_ HvessModule31OperationalStatus : 60|2@1+ (1,0) [0|3] "" Vector__XXX
 SG_ HvessModule32OperationalStatus : 62|2@1+ (1,0) [0|3] "" Vector__XXX

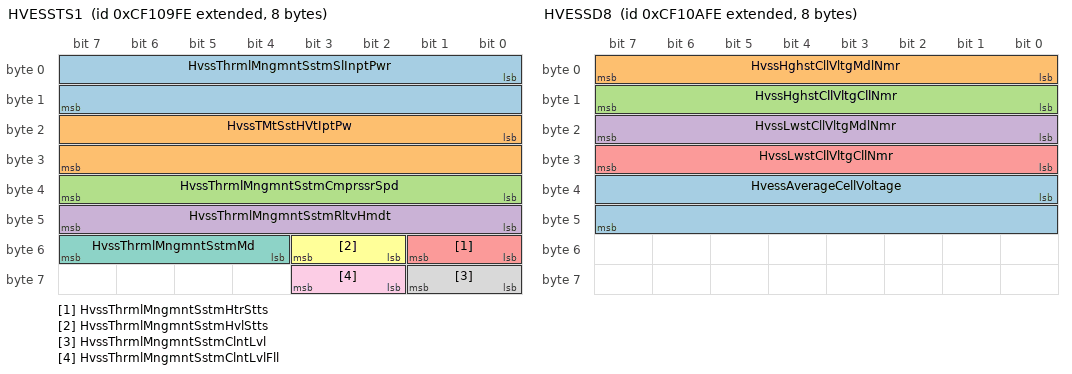
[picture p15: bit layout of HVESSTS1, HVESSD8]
BO_ 2364606974 HVESSTS1: 8 Vector__XXX
 SG_ HvssThrmlMngmntSstmSlInptPwr : 0|16@1+ (0.5,0) [0|32127.5] "W" Vector__XXX
 SG_ HvssTMtSstHVtIptPw : 16|16@1+ (0.5,0) [0|32127.5] "W" Vector__XXX
 SG_ HvssThrmlMngmntSstmCmprssrSpd : 32|8@1+ (32,0) [0|8000] "rpm" Vector__XXX
 SG_ HvssThrmlMngmntSstmRltvHmdt : 40|8@1+ (0.4,0) [0|100] "%" Vector__XXX
 SG_ HvssThrmlMngmntSstmHtrStts : 48|2@1+ (1,0) [0|3] "" Vector__XXX
 SG_ HvssThrmlMngmntSstmHvlStts : 50|2@1+ (1,0) [0|3] "" Vector__XXX
 SG_ HvssThrmlMngmntSstmMd : 52|4@1+ (1,0) [0|15] "" Vector__XXX
 SG_ HvssThrmlMngmntSstmClntLvl : 56|2@1+ (1,0) [0|3] "" Vector__XXX
 SG_ HvssThrmlMngmntSstmClntLvlFll : 58|2@1+ (1,0) [0|3] "" Vector__XXX

BO_ 2364607230 HVESSD8: 8 Vector__XXX
 SG_ HvessAverageCellVoltage : 32|16@1+ (0.001,0) [0|64.255] "V" Vector__XXX
 SG_ HvssHghstCllVltgMdlNmr : 0|8@1+ (1,0) [0|250] "count" Vector__XXX
 SG_ HvssHghstCllVltgCllNmr : 8|8@1+ (1,0) [0|250] "count" Vector__XXX
 SG_ HvssLwstCllVltgMdlNmr : 16|8@1+ (1,0) [0|250] "count" Vector__XXX
 SG_ HvssLwstCllVltgCllNmr : 24|8@1+ (1,0) [0|250] "count" Vector__XXX

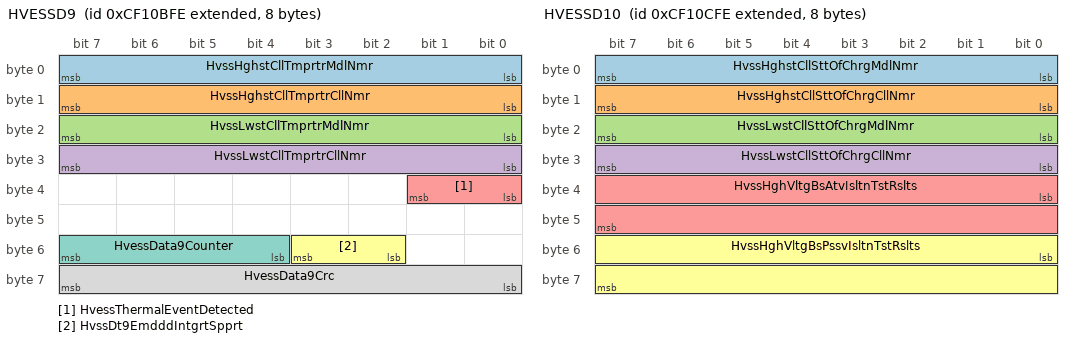
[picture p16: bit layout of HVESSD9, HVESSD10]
BO_ 2364607486 HVESSD9: 8 Vector__XXX
 SG_ HvssHghstCllTmprtrMdlNmr : 0|8@1+ (1,0) [0|250] "count" Vector__XXX
 SG_ HvssHghstCllTmprtrCllNmr : 8|8@1+ (1,0) [0|250] "count" Vector__XXX
 SG_ HvssLwstCllTmprtrMdlNmr : 16|8@1+ (1,0) [0|250] "count" Vector__XXX
 SG_ HvssLwstCllTmprtrCllNmr : 24|8@1+ (1,0) [0|250] "count" Vector__XXX
 SG_ HvessThermalEventDetected : 32|2@1+ (1,0) [0|3] "" Vector__XXX
 SG_ HvssDt9EmdddIntgrtSpprt : 50|2@1+ (1,0) [0|3] "" Vector__XXX
 SG_ HvessData9Counter : 52|4@1+ (1,0) [0|15] "" Vector__XXX
 SG_ HvessData9Crc : 56|8@1+ (1,0) [0|250] "count" Vector__XXX

BO_ 2364607742 HVESSD10: 8 Vector__XXX
 SG_ HvssHghstCllSttOfChrgMdlNmr : 0|8@1+ (1,0) [0|250] "count" Vector__XXX
 SG_ HvssHghstCllSttOfChrgCllNmr : 8|8@1+ (1,0) [0|250] "count" Vector__XXX
 SG_ HvssLwstCllSttOfChrgMdlNmr : 16|8@1+ (1,0) [0|250] "count" Vector__XXX
 SG_ HvssLwstCllSttOfChrgCllNmr : 24|8@1+ (1,0) [0|250] "count" Vector__XXX
 SG_ HvssHghVltgBsAtvIsltnTstRslts : 32|16@1+ (0.1,0) [0|6425.5] "OhmPerV" Vector__XXX
 SG_ HvssHghVltgBsPssvIsltnTstRslts : 48|16@1+ (0.1,0) [0|6425.5] "OhmPerV" Vector__XXX

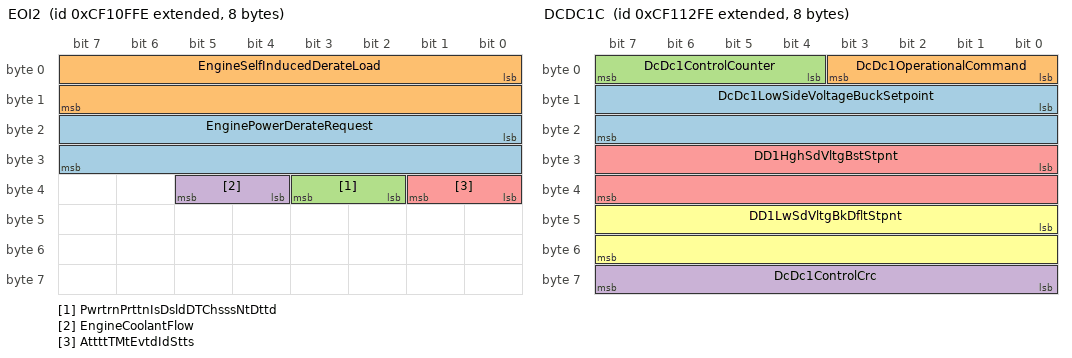
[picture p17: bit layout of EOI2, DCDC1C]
BO_ 2364608510 EOI2: 8 Vector__XXX
 SG_ EnginePowerDerateRequest : 16|16@1+ (0.5,0) [0|32127.5] "kW" Vector__XXX
 SG_ EngineSelfInducedDerateLoad : 0|16@1+ (0.5,0) [0|32127.5] "kW" Vector__XXX
 SG_ PwrtrnPrttnIsDsldDTChsssNtDttd : 34|2@1+ (1,0) [0|3] "" Vector__XXX
 SG_ EngineCoolantFlow : 36|2@1+ (1,0) [0|3] "" Vector__XXX
 SG_ AttttTMtEvtdIdStts : 32|2@1+ (1,0) [0|3] "" Vector__XXX

BO_ 2364609278 DCDC1C: 8 Vector__XXX
 SG_ DcDc1LowSideVoltageBuckSetpoint : 8|16@1+ (0.01,0) [0|642.55] "V" Vector__XXX
 SG_ DcDc1OperationalCommand : 0|4@1+ (1,0) [0|15] "" Vector__XXX
 SG_ DcDc1ControlCounter : 4|4@1+ (1,0) [0|15] "" Vector__XXX
 SG_ DcDc1ControlCrc : 56|8@1+ (1,0) [0|250] "count" Vector__XXX
 SG_ DD1HghSdVltgBstStpnt : 24|16@1+ (0.05,0) [0|3212.75] "V" Vector__XXX
 SG_ DD1LwSdVltgBkDfltStpnt : 40|16@1+ (0.01,0) [0|642.55] "V" Vector__XXX

BO_ 2364609534 DCDC1OS: 8 Vector__XXX
 SG_ DcDc1HvilStatus : 4|2@1+ (1,0) [0|3] "" Vector__XXX
 SG_ DcDc1LoadshedRequest : 6|2@1+ (1,0) [0|3] "" Vector__XXX
 SG_ DcDc1OperationalStatus : 0|4@1+ (1,0) [0|15] "" Vector__XXX
 SG_ DcDc1OperatingStatusCounter : 52|4@1+ (1,0) [0|15] "" Vector__XXX
 SG_ DcDc1OperatingStatusCrc : 56|8@1+ (1,0) [0|250] "count" Vector__XXX
 SG_ DD1PwrLmtDTHghSdCrrnt : 8|2@1+ (1,0) [0|3] "" Vector__XXX
 SG_ DD1PwrLmtDTLwSdCrrnt : 10|2@1+ (1,0) [0|3] "" Vector__XXX
 SG_ DD1PwrLmtDTHghSdVltgMnmm : 12|2@1+ (1,0) [0|3] "" Vector__XXX
 SG_ DD1PwrLmtDTHghSdVltgMxmm : 14|2@1+ (1,0) [0|3] "" Vector__XXX
 SG_ DD1PwrLmtDTLwSdVltgMnmm : 16|2@1+ (1,0) [0|3] "" Vector__XXX
 SG_ DD1PwrLmtDTLwSdVltgMxmm : 18|2@1+ (1,0) [0|3] "" Vector__XXX
 SG_ DD1PwrLmtDTCnvrtrTmprtr : 20|2@1+ (1,0) [0|3] "" Vector__XXX
 SG_ DD1PwrLmtDTEltrnFltrTmprtr : 22|2@1+ (1,0) [0|3] "" Vector__XXX
 SG_ DD1PwrLmtDTPwrEltrnsTmprtr : 24|2@1+ (1,0) [0|3] "" Vector__XXX
 SG_ DD1PwrLmtDTSlBttrTrmnlVltg : 26|2@1+ (1,0) [0|3] "" Vector__XXX
 SG_ DD1PwrLmtDTSlBttrTrmnlCrrnt : 28|2@1+ (1,0) [0|3] "" Vector__XXX
 SG_ DD1PwrLmtDTSlBttrTrmnlTmprtr : 30|2@1+ (1,0) [0|3] "" Vector__XXX
 SG_ DD1PwrLmtDTUndfndRsn : 32|2@1+ (1,0) [0|3] "" Vector__XXX

BO_ 2364609790 DCDC1VC: 8 Vector__XXX
 SG_ DcDc1HighSideCurrent : 48|16@1+ (0.1,-3212.7) [-3212.7|3212.8] "A" Vector__XXX
 SG_ DcDc1HighSideVoltage : 32|16@1+ (0.05,0) [0|3212.75] "V" Vector__XXX
 SG_ DcDc1LowSideCurrent : 16|16@1+ (0.1,-3212.7) [-3212.7|3212.8] "A" Vector__XXX
 SG_ DcDc1LowSideVoltage : 0|16@1+ (0.01,0) [0|642.55] "V" Vector__XXX

BO_ 2364610046 DCDC1SBS: 8 Vector__XXX
 SG_ DcDc1SliBatteryTerminalCurrent : 16|16@1+ (0.1,-3212.7) [-3212.7|3212.8] "A" Vector__XXX
 SG_ DcDc1SliBatteryTerminalVoltage : 0|16@1+ (0.01,0) [0|642.55] "V" Vector__XXX
 SG_ DD1SlBttrTrmnlTmprtr : 32|8@1+ (1,-40) [-40|210] "degC" Vector__XXX

BO_ 2364610558 DCDC1S2: 8 Vector__XXX
 SG_ DcDc1HighSidePower : 16|16@1+ (0.05,-1600) [-1600|1612.75] "kW" Vector__XXX
 SG_ DcDc1LowSidePower : 0|16@1+ (0.05,-1600) [-1600|1612.75] "kW" Vector__XXX
 SG_ DD1HghSdNgtvTChsssGrndVltg : 32|16@1+ (0.05,0) [0|3212.75] "V" Vector__XXX

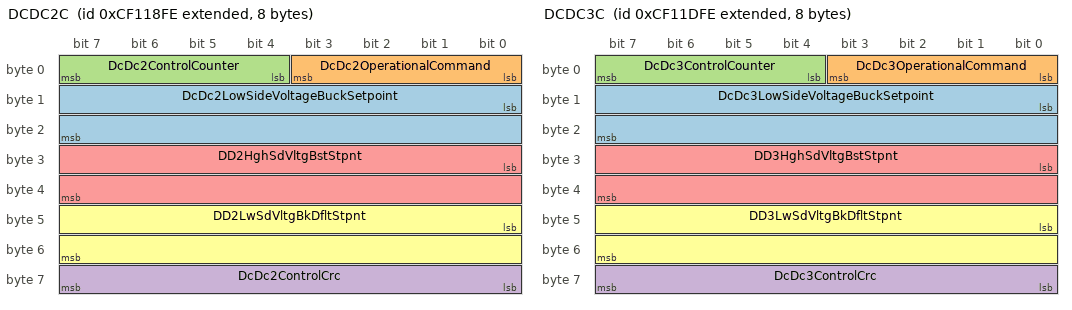
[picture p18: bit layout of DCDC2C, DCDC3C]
BO_ 2364610814 DCDC2C: 8 Vector__XXX
 SG_ DcDc2LowSideVoltageBuckSetpoint : 8|16@1+ (0.01,0) [0|642.55] "V" Vector__XXX
 SG_ DcDc2OperationalCommand : 0|4@1+ (1,0) [0|15] "" Vector__XXX
 SG_ DcDc2ControlCounter : 4|4@1+ (1,0) [0|15] "" Vector__XXX
 SG_ DcDc2ControlCrc : 56|8@1+ (1,0) [0|250] "count" Vector__XXX
 SG_ DD2HghSdVltgBstStpnt : 24|16@1+ (0.05,0) [0|3212.75] "V" Vector__XXX
 SG_ DD2LwSdVltgBkDfltStpnt : 40|16@1+ (0.01,0) [0|642.55] "V" Vector__XXX

BO_ 2364611070 DCDC2OS: 8 Vector__XXX
 SG_ DcDc2HvilStatus : 4|2@1+ (1,0) [0|3] "" Vector__XXX
 SG_ DcDc2LoadshedRequest : 6|2@1+ (1,0) [0|3] "" Vector__XXX
 SG_ DcDc2OperationalStatus : 0|4@1+ (1,0) [0|15] "" Vector__XXX
 SG_ DcDc2OperatingStatusCounter : 52|4@1+ (1,0) [0|15] "" Vector__XXX
 SG_ DcDc2OperatingStatusCrc : 56|8@1+ (1,0) [0|250] "count" Vector__XXX
 SG_ DD2PwrLmtDTHghSdCrrnt : 8|2@1+ (1,0) [0|3] "" Vector__XXX
 SG_ DD2PwrLmtDTLwSdCrrnt : 10|2@1+ (1,0) [0|3] "" Vector__XXX
 SG_ DD2PwrLmtDTHghSdVltgMnmm : 12|2@1+ (1,0) [0|3] "" Vector__XXX
 SG_ DD2PwrLmtDTHghSdVltgMxmm : 14|2@1+ (1,0) [0|3] "" Vector__XXX
 SG_ DD2PwrLmtDTLwSdVltgMnmm : 16|2@1+ (1,0) [0|3] "" Vector__XXX
 SG_ DD2PwrLmtDTLwSdVltgMxmm : 18|2@1+ (1,0) [0|3] "" Vector__XXX
 SG_ DD2PwrLmtDTCnvrtrTmprtr : 20|2@1+ (1,0) [0|3] "" Vector__XXX
 SG_ DD2PwrLmtDTEltrnFltrTmprtr : 22|2@1+ (1,0) [0|3] "" Vector__XXX
 SG_ DD2PwrLmtDTPwrEltrnsTmprtr : 24|2@1+ (1,0) [0|3] "" Vector__XXX
 SG_ DD2PwrLmtDTSlBttrTrmnlVltg : 26|2@1+ (1,0) [0|3] "" Vector__XXX
 SG_ DD2PwrLmtDTSlBttrTrmnlCrrnt : 28|2@1+ (1,0) [0|3] "" Vector__XXX
 SG_ DD2PwrLmtDTSlBttrTrmnlTmprtr : 30|2@1+ (1,0) [0|3] "" Vector__XXX
 SG_ DD2PwrLmtDTUndfndRsn : 32|2@1+ (1,0) [0|3] "" Vector__XXX

BO_ 2364611326 DCDC2VC: 8 Vector__XXX
 SG_ DcDc2HighSideCurrent : 48|16@1+ (0.1,-3212.7) [-3212.7|3212.8] "A" Vector__XXX
 SG_ DcDc2HighSideVoltage : 32|16@1+ (0.05,0) [0|3212.75] "V" Vector__XXX
 SG_ DcDc2LowSideCurrent : 16|16@1+ (0.1,-3212.7) [-3212.7|3212.8] "A" Vector__XXX
 SG_ DcDc2LowSideVoltage : 0|16@1+ (0.01,0) [0|642.55] "V" Vector__XXX

BO_ 2364611582 DCDC2SBS: 8 Vector__XXX
 SG_ DcDc2SliBatteryTerminalCurrent : 16|16@1+ (0.1,-3212.7) [-3212.7|3212.8] "A" Vector__XXX
 SG_ DcDc2SliBatteryTerminalVoltage : 0|16@1+ (0.01,0) [0|642.55] "V" Vector__XXX
 SG_ DD2SlBttrTrmnlTmprtr : 32|8@1+ (1,-40) [-40|210] "degC" Vector__XXX

BO_ 2364611838 DCDC2S2: 8 Vector__XXX
 SG_ DcDc2HighSidePower : 16|16@1+ (0.05,-1600) [-1600|1612.75] "kW" Vector__XXX
 SG_ DcDc2LowSidePower : 0|16@1+ (0.05,-1600) [-1600|1612.75] "kW" Vector__XXX
 SG_ DD2HghSdNgtvTChsssGrndVltg : 32|16@1+ (0.05,0) [0|3212.75] "V" Vector__XXX

BO_ 2364612094 DCDC3C: 8 Vector__XXX
 SG_ DcDc3LowSideVoltageBuckSetpoint : 8|16@1+ (0.01,0) [0|642.55] "V" Vector__XXX
 SG_ DcDc3OperationalCommand : 0|4@1+ (1,0) [0|15] "" Vector__XXX
 SG_ DcDc3ControlCounter : 4|4@1+ (1,0) [0|15] "" Vector__XXX
 SG_ DcDc3ControlCrc : 56|8@1+ (1,0) [0|250] "count" Vector__XXX
 SG_ DD3HghSdVltgBstStpnt : 24|16@1+ (0.05,0) [0|3212.75] "V" Vector__XXX
 SG_ DD3LwSdVltgBkDfltStpnt : 40|16@1+ (0.01,0) [0|642.55] "V" Vector__XXX

BO_ 2364612350 DCDC3OS: 8 Vector__XXX
 SG_ DcDc3HvilStatus : 4|2@1+ (1,0) [0|3] "" Vector__XXX
 SG_ DcDc3LoadshedRequest : 6|2@1+ (1,0) [0|3] "" Vector__XXX
 SG_ DcDc3OperationalStatus : 0|4@1+ (1,0) [0|15] "" Vector__XXX
 SG_ DcDc3OperatingStatusCounter : 52|4@1+ (1,0) [0|15] "" Vector__XXX
 SG_ DcDc3OperatingStatusCrc : 56|8@1+ (1,0) [0|250] "count" Vector__XXX
 SG_ DD3PwrLmtDTHghSdCrrnt : 8|2@1+ (1,0) [0|3] "" Vector__XXX
 SG_ DD3PwrLmtDTLwSdCrrnt : 10|2@1+ (1,0) [0|3] "" Vector__XXX
 SG_ DD3PwrLmtDTHghSdVltgMnmm : 12|2@1+ (1,0) [0|3] "" Vector__XXX
 SG_ DD3PwrLmtDTHghSdVltgMxmm : 14|2@1+ (1,0) [0|3] "" Vector__XXX
 SG_ DD3PwrLmtDTLwSdVltgMnmm : 16|2@1+ (1,0) [0|3] "" Vector__XXX
 SG_ DD3PwrLmtDTLwSdVltgMxmm : 18|2@1+ (1,0) [0|3] "" Vector__XXX
 SG_ DD3PwrLmtDTCnvrtrTmprtr : 20|2@1+ (1,0) [0|3] "" Vector__XXX
 SG_ DD3PwrLmtDTEltrnFltrTmprtr : 22|2@1+ (1,0) [0|3] "" Vector__XXX
 SG_ DD3PwrLmtDTPwrEltrnsTmprtr : 24|2@1+ (1,0) [0|3] "" Vector__XXX
 SG_ DD3PwrLmtDTSlBttrTrmnlVltg : 26|2@1+ (1,0) [0|3] "" Vector__XXX
 SG_ DD3PwrLmtDTSlBttrTrmnlCrrnt : 28|2@1+ (1,0) [0|3] "" Vector__XXX
 SG_ DD3PwrLmtDTSlBttrTrmnlTmprtr : 30|2@1+ (1,0) [0|3] "" Vector__XXX
 SG_ DD3PwrLmtDTUndfndRsn : 32|2@1+ (1,0) [0|3] "" Vector__XXX

BO_ 2364612606 DCDC3VC: 8 Vector__XXX
 SG_ DcDc3HighSideCurrent : 48|16@1+ (0.1,-3212.7) [-3212.7|3212.8] "A" Vector__XXX
 SG_ DcDc3HighSideVoltage : 32|16@1+ (0.05,0) [0|3212.75] "V" Vector__XXX
 SG_ DcDc3LowSideCurrent : 16|16@1+ (0.1,-3212.7) [-3212.7|3212.8] "A" Vector__XXX
 SG_ DcDc3LowSideVoltage : 0|16@1+ (0.01,0) [0|642.55] "V" Vector__XXX

BO_ 2364612862 DCDC3SBS: 8 Vector__XXX
 SG_ DcDc3SliBatteryTerminalCurrent : 16|16@1+ (0.1,-3212.7) [-3212.7|3212.8] "A" Vector__XXX
 SG_ DcDc3SliBatteryTerminalVoltage : 0|16@1+ (0.01,0) [0|642.55] "V" Vector__XXX
 SG_ DD3SlBttrTrmnlTmprtr : 32|8@1+ (1,-40) [-40|210] "degC" Vector__XXX

BO_ 2364613118 DCDC3S2: 8 Vector__XXX
 SG_ DcDc3HighSidePower : 16|16@1+ (0.05,-1600) [-1600|1612.75] "kW" Vector__XXX
 SG_ DcDc3LowSidePower : 0|16@1+ (0.05,-1600) [-1600|1612.75] "kW" Vector__XXX
 SG_ DD3HghSdNgtvTChsssGrndVltg : 32|16@1+ (0.05,0) [0|3212.75] "V" Vector__XXX

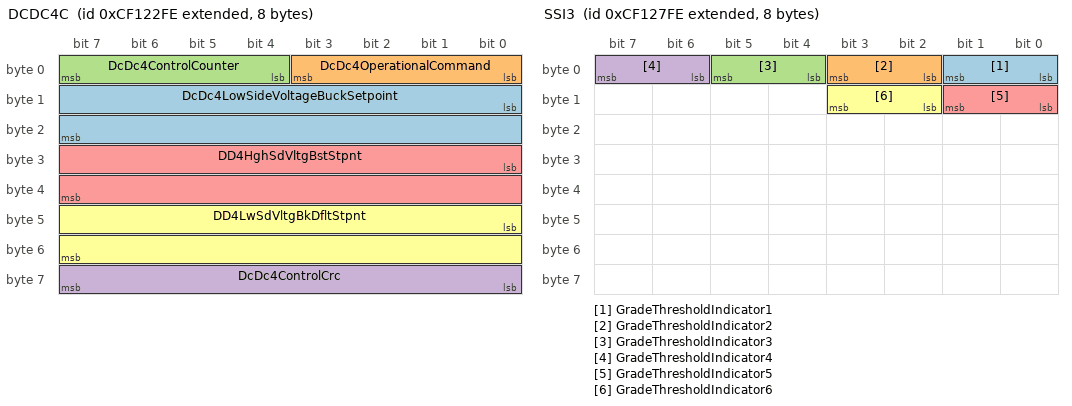
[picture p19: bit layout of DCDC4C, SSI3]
BO_ 2364613374 DCDC4C: 8 Vector__XXX
 SG_ DcDc4LowSideVoltageBuckSetpoint : 8|16@1+ (0.01,0) [0|642.55] "V" Vector__XXX
 SG_ DcDc4OperationalCommand : 0|4@1+ (1,0) [0|15] "" Vector__XXX
 SG_ DcDc4ControlCounter : 4|4@1+ (1,0) [0|15] "" Vector__XXX
 SG_ DcDc4ControlCrc : 56|8@1+ (1,0) [0|250] "count" Vector__XXX
 SG_ DD4HghSdVltgBstStpnt : 24|16@1+ (0.05,0) [0|3212.75] "V" Vector__XXX
 SG_ DD4LwSdVltgBkDfltStpnt : 40|16@1+ (0.01,0) [0|642.55] "V" Vector__XXX

BO_ 2364613630 DCDC4OS: 8 Vector__XXX
 SG_ DcDc4HvilStatus : 4|2@1+ (1,0) [0|3] "" Vector__XXX
 SG_ DcDc4LoadshedRequest : 6|2@1+ (1,0) [0|3] "" Vector__XXX
 SG_ DcDc4OperationalStatus : 0|4@1+ (1,0) [0|15] "" Vector__XXX
 SG_ DcDc4OperatingStatusCounter : 52|4@1+ (1,0) [0|15] "" Vector__XXX
 SG_ DcDc4OperatingStatusCrc : 56|8@1+ (1,0) [0|250] "count" Vector__XXX
 SG_ DD4PwrLmtDTHghSdCrrnt : 8|2@1+ (1,0) [0|3] "" Vector__XXX
 SG_ DD4PwrLmtDTLwSdCrrnt : 10|2@1+ (1,0) [0|3] "" Vector__XXX
 SG_ DD4PwrLmtDTHghSdVltgMnmm : 12|2@1+ (1,0) [0|3] "" Vector__XXX
 SG_ DD4PwrLmtDTHghSdVltgMxmm : 14|2@1+ (1,0) [0|3] "" Vector__XXX
 SG_ DD4PwrLmtDTLwSdVltgMnmm : 16|2@1+ (1,0) [0|3] "" Vector__XXX
 SG_ DD4PwrLmtDTLwSdVltgMxmm : 18|2@1+ (1,0) [0|3] "" Vector__XXX
 SG_ DD4PwrLmtDTCnvrtrTmprtr : 20|2@1+ (1,0) [0|3] "" Vector__XXX
 SG_ DD4PwrLmtDTEltrnFltrTmprtr : 22|2@1+ (1,0) [0|3] "" Vector__XXX
 SG_ DD4PwrLmtDTPwrEltrnsTmprtr : 24|2@1+ (1,0) [0|3] "" Vector__XXX
 SG_ DD4PwrLmtDTSlBttrTrmnlVltg : 26|2@1+ (1,0) [0|3] "" Vector__XXX
 SG_ DD4PwrLmtDTSlBttrTrmnlCrrnt : 28|2@1+ (1,0) [0|3] "" Vector__XXX
 SG_ DD4PwrLmtDTSlBttrTrmnlTmprtr : 30|2@1+ (1,0) [0|3] "" Vector__XXX
 SG_ DD4PwrLmtDTUndfndRsn : 32|2@1+ (1,0) [0|3] "" Vector__XXX

BO_ 2364613886 DCDC4VC: 8 Vector__XXX
 SG_ DcDc4HighSideCurrent : 48|16@1+ (0.1,-3212.7) [-3212.7|3212.8] "A" Vector__XXX
 SG_ DcDc4HighSideVoltage : 32|16@1+ (0.05,0) [0|3212.75] "V" Vector__XXX
 SG_ DcDc4LowSideCurrent : 16|16@1+ (0.1,-3212.7) [-3212.7|3212.8] "A" Vector__XXX
 SG_ DcDc4LowSideVoltage : 0|16@1+ (0.01,0) [0|642.55] "V" Vector__XXX

BO_ 2364614142 DCDC4SBS: 8 Vector__XXX
 SG_ DcDc4SliBatteryTerminalCurrent : 16|16@1+ (0.1,-3212.7) [-3212.7|3212.8] "A" Vector__XXX
 SG_ DcDc4SliBatteryTerminalVoltage : 0|16@1+ (0.01,0) [0|642.55] "V" Vector__XXX
 SG_ DD4SlBttrTrmnlTmprtr : 32|8@1+ (1,-40) [-40|210] "degC" Vector__XXX

BO_ 2364614398 DCDC4S2: 8 Vector__XXX
 SG_ DcDc4HighSidePower : 16|16@1+ (0.05,-1600) [-1600|1612.75] "kW" Vector__XXX
 SG_ DcDc4LowSidePower : 0|16@1+ (0.05,-1600) [-1600|1612.75] "kW" Vector__XXX
 SG_ DD4HghSdNgtvTChsssGrndVltg : 32|16@1+ (0.05,0) [0|3212.75] "V" Vector__XXX

BO_ 2364614654 SSI3: 8 Vector__XXX
 SG_ GradeThresholdIndicator1 : 0|2@1+ (1,0) [0|3] "" Vector__XXX
 SG_ GradeThresholdIndicator2 : 2|2@1+ (1,0) [0|3] "" Vector__XXX
 SG_ GradeThresholdIndicator3 : 4|2@1+ (1,0) [0|3] "" Vector__XXX
 SG_ GradeThresholdIndicator4 : 6|2@1+ (1,0) [0|3] "" Vector__XXX
 SG_ GradeThresholdIndicator5 : 8|2@1+ (1,0) [0|3] "" Vector__XXX
 SG_ GradeThresholdIndicator6 : 10|2@1+ (1,0) [0|3] "" Vector__XXX

BO_ 2364614910 DCACAI3S2: 8 Vector__XXX
 SG_ DAAssrInvrtr3DSdPwr : 0|16@1+ (0.0625,0) [0|4015.9375] "kW" Vector__XXX
 SG_ DAAssrInvrtr3DSdVltg : 16|16@1+ (0.05,0) [0|3212.75] "V" Vector__XXX
 SG_ DAAssrInvrtr3DSdCrrnt : 32|16@1+ (0.0625,0) [0|4015.9375] "A" Vector__XXX
 SG_ DAAssIvt3DSdNtvTCsssGdVt : 48|16@1+ (0.05,0) [0|3212.75] "V" Vector__XXX

BO_ 2364615166 DCACAI3V: 8 Vector__XXX
 SG_ DAAssrInvrtr3IgntnVltg : 0|16@1+ (0.05,0) [0|3212.75] "V" Vector__XXX
 SG_ DAAssrInvrtr3UnswthdSlVltg : 16|16@1+ (0.05,0) [0|3212.75] "V" Vector__XXX

BO_ 2364615678 DCACAI4S2: 8 Vector__XXX
 SG_ DAAssrInvrtr4DSdPwr : 0|16@1+ (0.0625,0) [0|4015.9375] "kW" Vector__XXX
 SG_ DAAssrInvrtr4DSdVltg : 16|16@1+ (0.05,0) [0|3212.75] "V" Vector__XXX
 SG_ DAAssrInvrtr4DSdCrrnt : 32|16@1+ (0.0625,0) [0|4015.9375] "A" Vector__XXX
 SG_ DAAssIvt4DSdNtvTCsssGdVt : 48|16@1+ (0.05,0) [0|3212.75] "V" Vector__XXX

BO_ 2364615934 DCACAI4V: 8 Vector__XXX
 SG_ DAAssrInvrtr4IgntnVltg : 0|16@1+ (0.05,0) [0|3212.75] "V" Vector__XXX
 SG_ DAAssrInvrtr4UnswthdSlVltg : 16|16@1+ (0.05,0) [0|3212.75] "V" Vector__XXX

BO_ 2364616958 DCACAI5S2: 8 Vector__XXX
 SG_ DAAssrInvrtr5DSdPwr : 0|16@1+ (0.0625,0) [0|4015.9375] "kW" Vector__XXX
 SG_ DAAssrInvrtr5DSdVltg : 16|16@1+ (0.05,0) [0|3212.75] "V" Vector__XXX
 SG_ DAAssrInvrtr5DSdCrrnt : 32|16@1+ (0.0625,0) [0|4015.9375] "A" Vector__XXX
 SG_ DAAssIvt5DSdNtvTCsssGdVt : 48|16@1+ (0.05,0) [0|3212.75] "V" Vector__XXX

BO_ 2364617214 DCACAI5V: 8 Vector__XXX
 SG_ DAAssrInvrtr5IgntnVltg : 0|16@1+ (0.05,0) [0|3212.75] "V" Vector__XXX
 SG_ DAAssrInvrtr5UnswthdSlVltg : 16|16@1+ (0.05,0) [0|3212.75] "V" Vector__XXX

BO_ 2365296894 DCDC4V: 8 Vector__XXX
 SG_ DD4CntrllrInptIgntnVltg : 0|16@1+ (0.05,0) [0|3212.75] "V" Vector__XXX
 SG_ DD4CntrllrInptUnswthdSlVltg : 16|16@1+ (0.05,0) [0|3212.75] "V" Vector__XXX

BO_ 2365297150 DCDC3V: 8 Vector__XXX
 SG_ DD3CntrllrInptIgntnVltg : 0|16@1+ (0.05,0) [0|3212.75] "V" Vector__XXX
 SG_ DD3CntrllrInptUnswthdSlVltg : 16|16@1+ (0.05,0) [0|3212.75] "V" Vector__XXX

BO_ 2365297406 DCDC2V: 8 Vector__XXX
 SG_ DD2CntrllrInptIgntnVltg : 0|16@1+ (0.05,0) [0|3212.75] "V" Vector__XXX
 SG_ DD2CntrllrInptUnswthdSlVltg : 16|16@1+ (0.05,0) [0|3212.75] "V" Vector__XXX

CM_ BO_ 2364557822 "Engine Cylinder 16 Combustion Information";
CM_ SG_ 2364557822 EngineCylinder16HeatRelease "Engine Cylinder 16 Heat Release: The amount of heat produced during combustion in engine cylinder 16.  The negative range is to cover thermodynamic behavior during misfire.";
CM_ SG_ 2364557822 EngineCylinder16PeakPressure "Engine Cylinder 16 Peak Pressure: Peak pressure in engine cylinder 16 in combustion cycle.";
CM_ SG_ 2364557822 EngnClndr16LwFrqnKnkLvl "Engine Cylinder 16 Low Frequency Knock Level: Indicates the level of low frequency knock for engine cylinder 16. This knock occurs at frequencies below the typical knock level reported on SPNs 1367 & 6458.  The level of low frequency knock is reporte...";
CM_ SG_ 2364557822 EngnClndr16MxmmPrssrInrsRt "Engine Cylinder 16 Maximum Pressure Increase Rate: The maximum slope, in degrees of crank angle, of the pressure increase in engine cylinder 16 during the combustion cycle.";
CM_ SG_ 2364557822 EngnClndr16SnhrnsKnkLvl "Engine Cylinder 16 Synchronous Knock Level: Used to indicate the level of knock for engine cylinder 16. The level of knock is reported using a relative scale where 0% is least level of knock, and increasing levels indicate more knock until 100% indic...";
CM_ SG_ 2364557822 EngnClndr16PrssrSnsrPrlmnrFm "Engine Cylinder 16 Pressure Sensor Preliminary FMI: Used to identify the applicable J1939-73 FMI detected in the engine cylinder 16 pressure sensor.  In the case of multiple failures the most severe is communicated.A value of 31 is sent to indicate t...";
CM_ BO_ 2364558078 "Engine Cylinder 17 Combustion Information";
CM_ SG_ 2364558078 EngineCylinder17HeatRelease "Engine Cylinder 17 Heat Release: The amount of heat produced during combustion in engine cylinder 17.  The negative range is to cover thermodynamic behavior during misfire.";
CM_ SG_ 2364558078 EngineCylinder17PeakPressure "Engine Cylinder 17 Peak Pressure: Peak pressure in engine cylinder 17 in combustion cycle.";
CM_ SG_ 2364558078 EngnClndr17LwFrqnKnkLvl "Engine Cylinder 17 Low Frequency Knock Level: Indicates the level of low frequency knock for engine cylinder 17. This knock occurs at frequencies below the typical knock level reported on SPNs 1368 & 6462.  The level of low frequency knock is reporte...";
CM_ SG_ 2364558078 EngnClndr17MxmmPrssrInrsRt "Engine Cylinder 17 Maximum Pressure Increase Rate: The maximum slope, in degrees of crank angle, of the pressure increase in engine cylinder 17 during the combustion cycle.";
CM_ SG_ 2364558078 EngnClndr17SnhrnsKnkLvl "Engine Cylinder 17 Synchronous Knock Level: Used to indicate the level of knock for engine cylinder 17. The level of knock is reported using a relative scale where 0% is least level of knock, and increasing levels indicate more knock until 100% indic...";
CM_ SG_ 2364558078 EngnClndr17PrssrSnsrPrlmnrFm "Engine Cylinder 17 Pressure Sensor Preliminary FMI: Used to identify the applicable J1939-73 FMI detected in the engine cylinder 17 pressure sensor.  In the case of multiple failures the most severe is communicated.A value of 31 is sent to indicate t...";
CM_ BO_ 2364558334 "Engine Cylinder 18 Combustion Information";
CM_ SG_ 2364558334 EngineCylinder18HeatRelease "Engine Cylinder 18 Heat Release: The amount of heat produced during combustion in engine cylinder 18.  The negative range is to cover thermodynamic behavior during misfire.";
CM_ SG_ 2364558334 EngineCylinder18PeakPressure "Engine Cylinder 18 Peak Pressure: Peak pressure in engine cylinder 18 in combustion cycle.";
CM_ SG_ 2364558334 EngnClndr18LwFrqnKnkLvl "Engine Cylinder 18 Low Frequency Knock Level: Indicates the level of low frequency knock for engine cylinder 18. This knock occurs at frequencies below the typical knock level reported on SPNs 1369 & 6466.  The level of low frequency knock is reporte...";
CM_ SG_ 2364558334 EngnClndr18MxmmPrssrInrsRt "Engine Cylinder 18 Maximum Pressure Increase Rate: The maximum slope, in degrees of crank angle, of the pressure increase in engine cylinder 18 during the combustion cycle.";
CM_ SG_ 2364558334 EngnClndr18SnhrnsKnkLvl "Engine Cylinder 18 Synchronous Knock Level: Used to indicate the level of knock for engine cylinder 18. The level of knock is reported using a relative scale where 0% is least level of knock, and increasing levels indicate more knock until 100% indic...";
CM_ SG_ 2364558334 EngnClndr18PrssrSnsrPrlmnrFm "Engine Cylinder 18 Pressure Sensor Preliminary FMI: Used to identify the applicable J1939-73 FMI detected in the engine cylinder 18 pressure sensor. In the case of multiple failures the most severe is communicated.A value of 31 is sent to indicate th...";
CM_ BO_ 2364558590 "Engine Cylinder 19 Combustion Information";
CM_ SG_ 2364558590 EngineCylinder19HeatRelease "Engine Cylinder 19 Heat Release: The amount of heat produced during combustion in engine cylinder 19.  The negative range is to cover thermodynamic behavior during misfire.";
CM_ SG_ 2364558590 EngineCylinder19PeakPressure "Engine Cylinder 19 Peak Pressure: Peak pressure in engine cylinder 19 in combustion cycle.";
CM_ SG_ 2364558590 EngnClndr19LwFrqnKnkLvl "Engine Cylinder 19 Low Frequency Knock Level: Indicates the level of low frequency knock for engine cylinder 19. This knock occurs at frequencies below the typical knock level reported on SPNs 1370 & 6470.  The level of low frequency knock is reporte...";
CM_ SG_ 2364558590 EngnClndr19MxmmPrssrInrsRt "Engine Cylinder 19 Maximum Pressure Increase Rate: The maximum slope, in degrees of crank angle, of the pressure increase in engine cylinder 19 during the combustion cycle.";
CM_ SG_ 2364558590 EngnClndr19SnhrnsKnkLvl "Engine Cylinder 19 Synchronous Knock Level: Used to indicate the level of knock for engine cylinder 19. The level of knock is reported using a relative scale where 0% is least level of knock, and increasing levels indicate more knock until 100% indic...";
CM_ SG_ 2364558590 EngnClndr19PrssrSnsrPrlmnrFm "Engine Cylinder 19 Pressure Sensor Preliminary FMI: Used to identify the applicable J1939-73 FMI detected in the engine cylinder 19 pressure sensor.  In the case of multiple failures the most severe is communicated.A value of 31 is sent to indicate t...";
CM_ BO_ 2364558846 "Engine Cylinder 20 Combustion Information";
CM_ SG_ 2364558846 EngineCylinder20HeatRelease "Engine Cylinder 20 Heat Release: The amount of heat produced during combustion in engine cylinder 20.  The negative range is to cover thermodynamic behavior during misfire.";
CM_ SG_ 2364558846 EngineCylinder20PeakPressure "Engine Cylinder 20 Peak Pressure: Peak pressure in engine cylinder 20 in combustion cycle.";
CM_ SG_ 2364558846 EngnClndr20LwFrqnKnkLvl "Engine Cylinder 20 Low Frequency Knock Level: Indicates the level of low frequency knock for engine cylinder 20. This knock occurs at frequencies below the typical knock level reported on SPNs 1371 & 6474.  The level of low frequency knock is reporte...";
CM_ SG_ 2364558846 EngnClndr20MxmmPrssrInrsRt "Engine Cylinder 20 Maximum Pressure Increase Rate: The maximum slope, in degrees of crank angle, of the pressure increase in engine cylinder 20 during the combustion cycle.";
CM_ SG_ 2364558846 EngnClndr20SnhrnsKnkLvl "Engine Cylinder 20 Synchronous Knock Level: Used to indicate the level of knock for engine cylinder 20. The level of knock is reported using a relative scale where 0% is least level of knock, and increasing levels indicate more knock until 100% indic...";
CM_ SG_ 2364558846 EngnClndr20PrssrSnsrPrlmnrFm "Engine Cylinder 20 Pressure Sensor Preliminary FMI: Used to identify the applicable J1939-73 FMI detected in the engine cylinder 20 pressure sensor.  In the case of multiple failures the most severe is communicated.A value of 31 is sent to indicate t...";
CM_ BO_ 2364564478 "Fuel Information 5 (Gaseous)";
CM_ SG_ 2364564478 EngnGssFlVlvNmnlDrtnCmmnd "Engine Gaseous Fuel Valve Nominal Duration Command: Amount of time the gaseous fuel valves are activated.  It's a nominal value used for all the gaseous fuel valves in the engine.Note: Please see SPNs 6658 - 6677 for duration command for each gaseous...";
CM_ SG_ 2364564478 EngnPrChmrFlVlvNmnlDrtnCmmnd "Engine Pre-Chamber Fuel Valve Nominal Duration Command: Amount of time the pre-chamber fuel valves are activated. It's a nominal value used for all the prechamber fuel valves in the engine.Note: Please see SPNs 9591-9610 for duration command for each...";
CM_ SG_ 2364564478 EngnGssFlVlvNmnlStrtOfAttnCmmnd "Engine Gaseous Fuel Valve Nominal Start of Actuation Command: The angle, relative to the TDC of each cylinder, with 0 being the TDC before the power stroke commences, at the which gaseous fuel valves are activated to open.  It's a nominal value used ...";
CM_ SG_ 2364564478 EPCFVvNSttOAttCd "Engine Pre-Chamber Fuel Valve Nominal Start of Actuation Command: The angle, relative to the TDC of each cylinder, with 0 being the TDC before the power stroke commences, at the which pre-chamber fuel valves are activated to open. It's a nominal valu...";
CM_ BO_ 2364564734 "Engine Gaseous Fuel Valve Duration Command 1";
CM_ SG_ 2364564734 EngnGssFlVlv1DrtnCmmnd "Engine Gaseous Fuel Valve 1 Duration Command: Amount of time the gaseous fuel valve 1 is activated.";
CM_ SG_ 2364564734 EngnGssFlVlv2DrtnCmmnd "Engine Gaseous Fuel Valve 2 Duration Command: Amount of time the gaseous fuel valve 2 is activated.";
CM_ SG_ 2364564734 EngnGssFlVlv3DrtnCmmnd "Engine Gaseous Fuel Valve 3 Duration Command: Amount of time the gaseous fuel valve 3 is activated.";
CM_ SG_ 2364564734 EngnGssFlVlv4DrtnCmmnd "Engine Gaseous Fuel Valve 4 Duration Command: Amount of time the gaseous fuel valve 4 is activated.";
CM_ BO_ 2364564990 "Engine Gaseous Fuel Valve Duration Command 2";
CM_ SG_ 2364564990 EngnGssFlVlv5DrtnCmmnd "Engine Gaseous Fuel Valve 5 Duration Command: Amount of time the gaseous fuel valve 5 is activated.";
CM_ SG_ 2364564990 EngnGssFlVlv6DrtnCmmnd "Engine Gaseous Fuel Valve 6 Duration Command: Amount of time the gaseous fuel valve 6 is activated.";
CM_ SG_ 2364564990 EngnGssFlVlv7DrtnCmmnd "Engine Gaseous Fuel Valve 7 Duration Command: Amount of time the gaseous fuel valve 7 is activated.";
CM_ SG_ 2364564990 EngnGssFlVlv8DrtnCmmnd "Engine Gaseous Fuel Valve 8 Duration Command: Amount of time the gaseous fuel valve 8 is activated.";
CM_ BO_ 2364565246 "Engine Gaseous Fuel Valve Duration Command 3";
CM_ SG_ 2364565246 EngnGssFlVlv10DrtnCmmnd "Engine Gaseous Fuel Valve 10 Duration Command: Amount of time the gaseous fuel valve 10 is activated.";
CM_ SG_ 2364565246 EngnGssFlVlv11DrtnCmmnd "Engine Gaseous Fuel Valve 11 Duration Command: Amount of time the gaseous fuel valve 11 is activated.";
CM_ SG_ 2364565246 EngnGssFlVlv12DrtnCmmnd "Engine Gaseous Fuel Valve 12 Duration Command: Amount of time the gaseous fuel valve 12 is activated.";
CM_ SG_ 2364565246 EngnGssFlVlv9DrtnCmmnd "Engine Gaseous Fuel Valve 9 Duration Command: Amount of time the gaseous fuel valve 9 is activated.";
CM_ BO_ 2364565502 "Engine Gaseous Fuel Valve Duration Command 4";
CM_ SG_ 2364565502 EngnGssFlVlv13DrtnCmmnd "Engine Gaseous Fuel Valve 13 Duration Command: Amount of time the gaseous fuel valve 13 is activated.";
CM_ SG_ 2364565502 EngnGssFlVlv14DrtnCmmnd "Engine Gaseous Fuel Valve 14 Duration Command: Amount of time the gaseous fuel valve 14 is activated.";
CM_ SG_ 2364565502 EngnGssFlVlv15DrtnCmmnd "Engine Gaseous Fuel Valve 15 Duration Command: Amount of time the gaseous fuel valve 15 is activated.";
CM_ SG_ 2364565502 EngnGssFlVlv16DrtnCmmnd "Engine Gaseous Fuel Valve 16 Duration Command: Amount of time the gaseous fuel valve 16 is activated.";
CM_ BO_ 2364565758 "Engine Gaseous Fuel Valve Duration Command 5";
CM_ SG_ 2364565758 EngnGssFlVlv17DrtnCmmnd "Engine Gaseous Fuel Valve 17 Duration Command: Amount of time the gaseous fuel valve 17 is activated.";
CM_ SG_ 2364565758 EngnGssFlVlv18DrtnCmmnd "Engine Gaseous Fuel Valve 18 Duration Command: Amount of time the gaseous fuel valve 18 is activated.";
CM_ SG_ 2364565758 EngnGssFlVlv19DrtnCmmnd "Engine Gaseous Fuel Valve 19 Duration Command: Amount of time the gaseous fuel valve 19 is activated.";
CM_ SG_ 2364565758 EngnGssFlVlv20DrtnCmmnd "Engine Gaseous Fuel Valve 20 Duration Command: Amount of time the gaseous fuel valve 20 is activated.";
CM_ BO_ 2364566014 "Engine Gaseous Fuel Valve Start of Actuation Command 1";
CM_ SG_ 2364566014 EngnGssFlVlv1StrtOfAttnCmmnd "Engine Gaseous Fuel Valve 1 Start of Actuation Command: The angle, relative to the TDC of cylinder 1, with 0 being the TDC before the power stroke commences, at the which gaseous fuel valve 1 is activated to open.Timings after TDC are referred with p...";
CM_ SG_ 2364566014 EngnGssFlVlv2StrtOfAttnCmmnd "Engine Gaseous Fuel Valve 2 Start of Actuation Command: The angle, relative to the TDC of cylinder 2, with 0 being the TDC before the power stroke commences, at the which gaseous fuel valve 2 is activated to open.Timings after TDC are referred with p...";
CM_ SG_ 2364566014 EngnGssFlVlv3StrtOfAttnCmmnd "Engine Gaseous Fuel Valve 3 Start of Actuation Command: The angle, relative to the TDC of cylinder 3, with 0 being the TDC before the power stroke commences, at the which gaseous fuel valve 3 is activated to open.Timings after TDC are referred with p...";
CM_ SG_ 2364566014 EngnGssFlVlv4StrtOfAttnCmmnd "Engine Gaseous Fuel Valve 4 Start of Actuation Command: The angle, relative to the TDC of cylinder 4, with 0 being the TDC before the power stroke commences, at the which gaseous fuel valve 4 is activated to open.Timings after TDC are referred with p...";
CM_ BO_ 2364566270 "Engine Gaseous Fuel Valve Start of Actuation Command 2";
CM_ SG_ 2364566270 EngnGssFlVlv5StrtOfAttnCmmnd "Engine Gaseous Fuel Valve 5 Start of Actuation Command: The angle, relative to the TDC of cylinder 5, with 0 being the TDC before the power stroke commences, at the which gaseous fuel valve 5 is activated to open.Timings after TDC are referred with p...";
CM_ SG_ 2364566270 EngnGssFlVlv6StrtOfAttnCmmnd "Engine Gaseous Fuel Valve 6 Start of Actuation Command: The angle, relative to the TDC of cylinder 6, with 0 being the TDC before the power stroke commences, at the which gaseous fuel valve 6 is activated to open.Timings after TDC are referred with p...";
CM_ SG_ 2364566270 EngnGssFlVlv7StrtOfAttnCmmnd "Engine Gaseous Fuel Valve 7 Start of Actuation Command: The angle, relative to the TDC of cylinder 7, with 0 being the TDC before the power stroke commences, at the which gaseous fuel valve 7 is activated to open.Timings after TDC are referred with p...";
CM_ SG_ 2364566270 EngnGssFlVlv8StrtOfAttnCmmnd "Engine Gaseous Fuel Valve 8 Start of Actuation Command: The angle, relative to the TDC of cylinder 8, with 0 being the TDC before the power stroke commences, at the which gaseous fuel valve 8 is activated to open.Timings after TDC are referred with p...";
CM_ BO_ 2364566526 "Engine Gaseous Fuel Valve Start of Actuation Command 3";
CM_ SG_ 2364566526 EngnGssFlVlv9StrtOfAttnCmmnd "Engine Gaseous Fuel Valve 9 Start of Actuation Command: The angle, relative to the TDC of cylinder 9, with 0 being the TDC before the power stroke commences, at the which gaseous fuel valve 9 is activated to open.Timings after TDC are referred with p...";
CM_ SG_ 2364566526 EngnGssFlVlv10StrtOfAttnCmmnd "Engine Gaseous Fuel Valve 10 Start of Actuation Command: The angle, relative to the TDC of cylinder 10, with 0 being the TDC before the power stroke commences, at the which gaseous fuel valve 10 is activated to open.Timings after TDC are referred wit...";
CM_ SG_ 2364566526 EngnGssFlVlv11StrtOfAttnCmmnd "Engine Gaseous Fuel Valve 11 Start of Actuation Command: The angle, relative to the TDC of cylinder 11, with 0 being the TDC before the power stroke commences, at the which gaseous fuel valve 11 is activated to open.Timings after TDC are referred wit...";
CM_ SG_ 2364566526 EngnGssFlVlv12StrtOfAttnCmmnd "Engine Gaseous Fuel Valve 12 Start of Actuation Command: The angle, relative to the TDC of cylinder 12, with 0 being the TDC before the power stroke commences, at the which gaseous fuel valve 12 is activated to open.Timings after TDC are referred wit...";
CM_ BO_ 2364566782 "Engine Gaseous Fuel Valve Start of Actuation Command 4";
CM_ SG_ 2364566782 EngnGssFlVlv13StrtOfAttnCmmnd "Engine Gaseous Fuel Valve 13 Start of Actuation Command: The angle, relative to the TDC of cylinder 13, with 0 being the TDC before the power stroke commences, at the which gaseous fuel valve 13 is activated to open.Timings after TDC are referred wit...";
CM_ SG_ 2364566782 EngnGssFlVlv14StrtOfAttnCmmnd "Engine Gaseous Fuel Valve 14 Start of Actuation Command: The angle, relative to the TDC of cylinder 14, with 0 being the TDC before the power stroke commences, at the which gaseous fuel valve 14 is activated to open.Timings after TDC are referred wit...";
CM_ SG_ 2364566782 EngnGssFlVlv15StrtOfAttnCmmnd "Engine Gaseous Fuel Valve 15 Start of Actuation Command: The angle, relative to the TDC of cylinder 15, with 0 being the TDC before the power stroke commences, at the which gaseous fuel valve 15 is activated to open.Timings after TDC are referred wit...";
CM_ SG_ 2364566782 EngnGssFlVlv16StrtOfAttnCmmnd "Engine Gaseous Fuel Valve 16 Start of Actuation Command: The angle, relative to the TDC of cylinder 16, with 0 being the TDC before the power stroke commences, at the which gaseous fuel valve 16 is activated to open.Timings after TDC are referred wit...";
CM_ BO_ 2364567038 "Engine Gaseous Fuel Valve Start of Actuation Command 5";
CM_ SG_ 2364567038 EngnGssFlVlv17StrtOfAttnCmmnd "Engine Gaseous Fuel Valve 17 Start of Actuation Command: The angle, relative to the TDC of cylinder 17, with 0 being the TDC before the power stroke commences, at the which gaseous fuel valve 17 is activated to open.Timings after TDC are referred wit...";
CM_ SG_ 2364567038 EngnGssFlVlv18StrtOfAttnCmmnd "Engine Gaseous Fuel Valve 18 Start of Actuation Command: The angle, relative to the TDC of cylinder 18, with 0 being the TDC before the power stroke commences, at the which gaseous fuel valve 18 is activated to open.Timings after TDC are referred wit...";
CM_ SG_ 2364567038 EngnGssFlVlv19StrtOfAttnCmmnd "Engine Gaseous Fuel Valve 19 Start of Actuation Command: The angle, relative to the TDC of cylinder 19, with 0 being the TDC before the power stroke commences, at the which gaseous fuel valve 19 is activated to open.Timings after TDC are referred wit...";
CM_ SG_ 2364567038 EngnGssFlVlv20StrtOfAttnCmmnd "Engine Gaseous Fuel Valve 20 Start of Actuation Command: The angle, relative to the TDC of cylinder 20, with 0 being the TDC before the power stroke commences, at the which gaseous fuel valve 20 is activated to open.Timings after TDC are referred wit...";
CM_ BO_ 2364567294 "Fuel Pump Actuator Control Command";
CM_ SG_ 2364567294 EngnFlInjtnPmp1FlCntrlVlvCmmnd "Engine Fuel Injection Pump 1 Fuel Control Valve Command: The control command to fuel control valve in fuel pump 1, normalized to percent, where 0% represents fully closed and 100% represents fully open.";
CM_ SG_ 2364567294 EngnFlInjtnPmp2FlCntrlVlvCmmnd "Engine Fuel Injection Pump 2 Fuel Control Valve Command: The control command to fuel control valve in fuel pump 2, normalized to percent, where 0% represents fully closed and 100% represents fully open.";
CM_ BO_ 2364575998 "High Voltage Energy Storage System Data 1";
CM_ SG_ 2364575998 HvessAvailableDischargePower "HVESS Available Discharge Power: The rate at which the High Voltage Energy Storage System (or Pack 1 in systems with only one pack) can currently provide energy for propulsion or other uses.This parameter provides HVES system level information. If th...";
CM_ SG_ 2364575998 HvessAvailableChargePower "HVESS Available Charge Power: The rate at which the High Voltage Energy Storage System (or Pack 1 in systems with only one pack) can currently receive energy from a regenerative or recharging system.This parameter provides HVES system level informati...";
CM_ SG_ 2364575998 HvessVoltageLevel "HVESS Voltage Level: The voltage level of the High Voltage Energy Storage System (or Pack 1 in systems with only one pack). This parameter should be synchronized with SPN 5920 (HVESS Current) such that a realized power value can be calculated.  If th...";
CM_ SG_ 2364575998 HvessCurrent "HVESS Current: The current in or out of the High Voltage Energy Storage System (or Pack 1 in systems with only one pack). This parameter should be synchronized with SPN 5919 (HVESS Voltage Level) such that a realized power value can be calculated.  T...";
CM_ BO_ 2364576254 "High Voltage Energy Storage System Data 2";
CM_ SG_ 2364576254 HvessFastUpdateStateOfCharge "HVESS Fast Update State of Charge: Indicates the High Voltage Energy Storage System (or Pack 1 in systems with only one pack) state of charge. 0% means no charge remaining, 100% means the system is fully charged in terms of physical limits of the ene...";
CM_ SG_ 2364576254 HvessHighestCellVoltage "HVESS Highest Cell Voltage: The highest voltage level reported by any cell in the High Voltage Energy Storage System (or Pack 1 in systems with only one pack). If a single voltage sensor covers more than one cell, the value in this parameter is for t...";
CM_ SG_ 2364576254 HvessLowestCellVoltage "HVESS Lowest Cell Voltage: The lowest voltage level reported by any cell in the High Voltage Energy Storage System (or Pack 1 in systems with only one pack). If a single voltage sensor covers more than one cell, the value in this parameter is for the...";
CM_ SG_ 2364576254 HvssCllVltgDffrntlStts "HVESS Cell Voltage Differential Status: Indicates whether or not the differential between the highest and lowest cell voltages are within acceptable limits, according to the High Voltage Energy Storage System (or Pack 1 in systems with only one pack)...";
CM_ BO_ 2364576510 "High Voltage Energy Storage System Data 3";
CM_ SG_ 2364576510 HvessHighestCellTemperature "HVESS Highest Cell Temperature: The highest temperature level reported by any cell in the High Voltage Energy Storage System (or Pack 1 in systems with only one pack).  If a single temperature sensor covers more than one cell, the value in this param...";
CM_ SG_ 2364576510 HvessLowestCellTemperature "HVESS Lowest Cell Temperature: The lowest temperature level reported by any cell in the High Voltage Energy Storage System (or Pack 1 in systems with only one pack).  If a single temperature sensor covers more than one cell, the value in this paramet...";
CM_ SG_ 2364576510 HvessAverageCellTemperature "HVESS Average Cell Temperature: The average temperature level of all cells in the High Voltage Energy Storage System (or Pack 1 in systems with only one pack).This parameter provides HVES system level information. If there are multiple packs in the s...";
CM_ SG_ 2364576510 HvssCllTmprtrDffrntlStts "HVESS Cell Temperature Differential Status: Indicates whether or not the differential between the highest and lowest cell temperatures are within acceptable limits per the High Voltage Energy Storage System (or Pack 1 in systems with only one pack). ...";
CM_ BO_ 2364576766 "High Voltage Energy Storage System Data 4";
CM_ SG_ 2364576766 HvessDischargeCapacity "HVESS Discharge Capacity: The amount of stored electrical charge in the High Voltage Energy Storage System (or Pack 1 in systems with only one pack) that is available for use by the hybrid or EV system, i.e. 'how full is the tank'. See SPN 8205 (HVES...";
CM_ SG_ 2364576766 HvessChargeCapacity "HVESS Charge Capacity: The amount of unused electrical charge storage in the High Voltage Energy Storage System (or Pack 1 in systems with only one pack) that is available to be filled by charging, i.e. 'how much empty space is remaining in the tank'...";
CM_ SG_ 2364576766 HvessCellBalancingCount "HVESS Cell Balancing Count: The number of cells that are currently being balanced in the High Voltage Energy Storage System (or Pack 1 in systems with only one pack).This parameter provides HVES system level information. If there are multiple packs i...";
CM_ BO_ 2364577022 "High Voltage Energy Storage System Data 5";
CM_ SG_ 2364577022 HvessMinimumCellStateOfCharge "HVESS Minimum Cell State of Charge: Indicates the state of charge of the lowest-charged cell in the High Voltage Energy Storage System (or Pack 1 in systems with only one pack).  0% means no charge remaining, 100% means the cell is fully charged.   I...";
CM_ SG_ 2364577022 HvessMaximumCellStateOfCharge "HVESS Maximum Cell State of Charge: Indicates the state of charge of the highest-charged cell in the High Voltage Energy Storage System (or Pack 1 in systems with only one pack).  0% means no charge remaining, 100% means the cell is fully charged.  I...";
CM_ SG_ 2364577022 HvssMxmmInstntnsDshrgCrrntLmt "HVESS Maximum Instantaneous Discharge Current Limit: The maximum instantaneous current flow limit out of the High Voltage Energy Storage System (or Pack 1 in systems with only one pack). This parameter is defined from the high voltage energy storage ...";
CM_ SG_ 2364577022 HvssMxmmInstntnsChrgCrrntLmt "HVESS Maximum Instantaneous Charge Current Limit: The maximum instantaneous current flow limit into the High Voltage Energy Storage System (or Pack 1 in systems with only one pack). This parameter is defined from the high voltage energy storage syste...";
CM_ BO_ 2364577278 "High Voltage Energy Storage System Data 6";
CM_ SG_ 2364577278 HvessBusVoltage "HVESS Bus Voltage: The voltage level of the high voltage bus, as measured by the High Voltage Energy Storage System (or Pack 1 in systems with only one pack) on the bus side (not the battery side) of its contactors.This parameter provides HVES system...";
CM_ SG_ 2364577278 HvessIgnitionVoltage "HVESS Ignition Voltage: The voltage level at the ignition input of the High Voltage Energy Storage System (or Pack 1 in systems with only one pack) controller.This parameter provides HVES system level information. If there are multiple packs in the s...";
CM_ SG_ 2364577278 HvessIntakeCoolantTemperature "HVESS Intake Coolant Temperature: The temperature of liquid coolant as it enters the High Voltage Energy Storage System (or Pack 1 in systems with only one pack).This parameter provides HVES system level information. If there are multiple packs in th...";
CM_ SG_ 2364577278 HvessOutletCoolantTemperature "HVESS Outlet Coolant Temperature: The temperature of liquid coolant as it exits the High Voltage Energy Storage System (or Pack 1 in systems with only one pack).This parameter provides HVES system level information. If there are multiple packs in the...";
CM_ SG_ 2364577278 HvessElectronicsTemperature "HVESS Electronics Temperature: The temperature of the electronics or control modules in the High Voltage Energy Storage System (or Pack 1 in systems with only one pack).  If there are multiple temperature sensors then this parameter would be set to t...";
CM_ SG_ 2364577278 HvessTemperature "HVESS Temperature: The temperature of High Voltage Energy Storage System (or Pack 1 in systems with only one pack). The value may be determined from a unique sensor specifically for this purpose, or by aggregating various temperature sensor readings ...";
CM_ BO_ 2364577534 "High Voltage Energy Storage System Status 1";
CM_ SG_ 2364577534 HvessCenterOfPackContactorState "HVESS Center of Pack Contactor State: Position of the center high-voltage contactor.  When this contactor is closed, the positive half of the High Voltage Energy Storage System (or Pack 1 in systems with only one pack) is connected to the negative ha...";
CM_ SG_ 2364577534 HvessHvilStatus "HVESS HVIL Status: Status of the High Voltage Interlock Loop from the viewpoint of the High Voltage Energy Storage System (or Pack 1 in systems with only one pack).This parameter provides HVES system level information. If there are multiple packs in ...";
CM_ SG_ 2364577534 HvessInertiaSwitchStatus "HVESS Inertia Switch Status: Switch indicating that an impact has been sensed by the High Voltage Energy Storage System (or Pack 1 in systems with only one pack). The impact indication may require action by another controller, or by this HVES instanc...";
CM_ SG_ 2364577534 HvessStateOfChargeStatus "HVESS State of Charge Status: Status of the High Voltage Energy Storage System (or Pack 1 in systems with only one pack) State of Charge (SOC).  Note:  A given HVES controller may not support all of the states.This parameter provides HVES system leve...";
CM_ SG_ 2364577534 HvessCellBalanceStatus "HVESS Cell Balance Status: Indicates whether or not the cells in the High Voltage Energy Storage System (or Pack 1 in systems with only one pack) are balanced.This parameter provides HVES system level information. If there are multiple packs in the s...";
CM_ SG_ 2364577534 HvessCellBalancingActive "HVESS Cell Balancing Active: Indicates whether or not the cells in the High Voltage Energy Storage System (or Pack 1 in systems with only one pack) are currently being balanced.This parameter provides HVES system level information. If there are multi...";
CM_ SG_ 2364577534 HvessInternalChargerStatus "HVESS Internal Charger Status: Indicates that the charger in this HVES instance is on.  External chargers may use the External Energy Source Connection Status (SPN 7898) and related SPs.This parameter provides HVES system level information. If there ...";
CM_ SG_ 2364577534 HvessOperationalStatus "HVESS Operational Status: Provides feedback on where the High Voltage Energy Storage System (or Pack 1 in systems with only one pack) is in its operating spectrum, and includes feedback in response to the Operation Consent [i.e. SPN 8412 (HVESS Opera...";
CM_ SG_ 2364577534 HvessNumberOfHvespsReady "HVESS Number of HVESPs Ready: The number of High Voltage Energy Storage Packs that are currently ready to provide high voltage energy or are actively providing high voltage energy in the HVESS system. This parameter will increment after contactors ar...";
CM_ SG_ 2364577534 HvessStatus1Counter "HVESS Status 1 Counter: The message counter is used to detect situations where the transmitting ECU malfunction repeats the same frame all the time. The receiver of the information may use the counter parameter to detect this situation. The transmitt...";
CM_ SG_ 2364577534 HvessStatus1Crc "HVESS Status 1 CRC: The CRC is defined as follows: - Length: 8 bits- Polynomial: x^8+x^5+x^3+x^2+x+1- Initial Value: FFh- Input Data Reflection: Not reflected- Result Data Reflection: Not reflected- XOR value: FFh SAE makes no claim of the functional...";
CM_ SG_ 2364577534 HvssHghVltgBsPstvCnttrStt "HVESS High-Voltage Bus (Positive) Contactor State: Position of the High Voltage Energy Storage System (or Pack 1 in systems with only one pack) positive side bus contactor.  When this contactor is closed, the positive side of this HVES instance is co...";
CM_ SG_ 2364577534 HvssHghVltgBsNgtvCnttrStt "HVESS High-Voltage Bus (Negative) Contactor State: Position of the High Voltage Energy Storage System (or Pack 1 in systems with only one pack) negative side bus contactor.  When this contactor is closed, the negative side of this HVES instance is co...";
CM_ SG_ 2364577534 HvssHghVltgBsDsnntFrwrnng "HVESS High-Voltage Bus Disconnect Forewarning: Indicates that the High Voltage Energy Storage System (or Pack 1 in systems with only one pack) is about to disconnect from the high voltage bus due to unacceptable conditions.This parameter provides HVE...";
CM_ SG_ 2364577534 HvssHghVltgBsPrChrgRlStt "HVESS High-Voltage Bus Pre-Charge Relay State: Position of the high-voltage bus contactor pre-charge relay.  When this relay is closed, the High Voltage Energy Storage System (or Pack 1 in systems with only one pack) is bringing the high-voltage bus ...";
CM_ SG_ 2364577534 HvssHghVltgBsAtvIsltnTstStts "HVESS High-Voltage Bus Active Isolation Test Status: Status of the high-voltage bus electrical active isolation test as performed by the High Voltage Energy Storage System (or Pack 1 in systems with only one pack).This parameter provides HVES system ...";
CM_ SG_ 2364577534 HvssHghVltgBsPssvIsltnTstStts "HVESS High-Voltage Bus Passive Isolation Test Status: Status of the high-voltage bus electrical passive isolation test as performed by the High Voltage Energy Storage System (or Pack 1 in systems with only one pack).This parameter provides HVES syste...";
CM_ SG_ 2364577534 HvssHghVltgBsCnntnStts "HVESS High-Voltage Bus Connection Status: This parameter provides high level feedback on the High Voltage Energy Storage System (or Pack 1 in systems with only one pack) high voltage bus connection.  For specific contactor information, see SPN 8091 (...";
CM_ BO_ 2364580094 "High Voltage Energy Storage System Data 7";
CM_ SG_ 2364580094 HvessDischargeEnergyCapacity "HVESS Discharge Energy Capacity: The amount of stored electrical energy in High Voltage Energy Storage System (or Pack 1 in systems with only one pack) that is available for use by the hybrid or EV system, i.e. 'how full is the tank'. See SPN 8079 (H...";
CM_ SG_ 2364580094 HvessChargeEnergyCapacity "HVESS Charge Energy Capacity: The amount of unused electrical energy storage available to be filled by charging High Voltage Energy Storage System (or Pack 1 in systems with only one pack), i.e. 'how much empty space is remaining in the tank'. See SP...";
CM_ SG_ 2364580094 HvessMaximumChargeVoltageLimit "HVESS Maximum Charge Voltage Limit: The maximum voltage level not to be exceeded while charging the High Voltage Energy Storage System (or Pack 1 in systems with only one pack).  If this parameter is not supported, the maximum charge voltage should b...";
CM_ BO_ 2364590334 "DC/AC Accessory Inverter 1 Status 2";
CM_ SG_ 2364590334 DAAssrInvrtr1DSdPwr "DC/AC Accessory Inverter 1 DC Side Power: Power measured at the DC Side input to the DC/AC Accessory Inverter. ";
CM_ SG_ 2364590334 DAAssrInvrtr1DSdVltg "DC/AC Accessory Inverter 1 DC Side Voltage: DC Side input voltage measured at the point of control inside the DC/AC Accessory Inverter.";
CM_ SG_ 2364590334 DAAssrInvrtr1DSdCrrnt "DC/AC Accessory Inverter 1 DC Side Current: DC Side input current measured at the point of control inside the DC/AC Accessory Inverter.";
CM_ SG_ 2364590334 DAAssIvt1DSdNtvTCsssGdVt "DC/AC Accessory Inverter 1 DC Side Negative to Chassis Ground Voltage: The voltage level of the high voltage DC side, as measured by the DC/AC between the negative side of the High Voltage DC Side input and the chassis of the DC/AC enclosure.  This v...";
CM_ BO_ 2364590590 "DC/AC Accessory Inverter 1 Voltage";
CM_ SG_ 2364590590 DAAssrInvrtr1IgntnVltg "DC/AC Accessory Inverter 1 Ignition Voltage: Ignition voltage supplied to the  DC/AC Accessory Inverter controller.";
CM_ SG_ 2364590590 DAAssrInvrtr1UnswthdSlVltg "DC/AC Accessory Inverter 1 Unswitched SLI Voltage: Continuously supplied SLI power to this instance of the DC/AC Accessory Inverter controller.";
CM_ BO_ 2364591102 "DC/AC Accessory Inverter 2 Status 2";
CM_ SG_ 2364591102 DAAssrInvrtr2DSdPwr "DC/AC Accessory Inverter 2 DC Side Power: Power measured at the DC Side input to the DC/AC Accessory Inverter. ";
CM_ SG_ 2364591102 DAAssrInvrtr2DSdVltg "DC/AC Accessory Inverter 2 DC Side Voltage: DC Side input voltage measured at the point of control inside the DC/AC Accessory Inverter.";
CM_ SG_ 2364591102 DAAssrInvrtr2DSdCrrnt "DC/AC Accessory Inverter 2 DC Side Current: DC Side input current measured at the point of control inside the DC/AC Accessory Inverter.";
CM_ SG_ 2364591102 DAAssIvt2DSdNtvTCsssGdVt "DC/AC Accessory Inverter 2 DC Side Negative to Chassis Ground Voltage: The voltage level of the high voltage DC side, as measured by the DC/AC between the negative side of the High Voltage DC Side input and the chassis of the DC/AC enclosure.  This v...";
CM_ BO_ 2364591358 "DC/AC Accessory Inverter 2 Voltage";
CM_ SG_ 2364591358 DAAssrInvrtr2IgntnVltg "DC/AC Accessory Inverter 2 Ignition Voltage: Ignition voltage supplied to the  DC/AC Accessory Inverter controller.";
CM_ SG_ 2364591358 DAAssrInvrtr2UnswthdSlVltg "DC/AC Accessory Inverter 2 Unswitched SLI Voltage: Continuously supplied SLI power to this instance of the DC/AC Accessory Inverter controller.";
CM_ BO_ 2364592382 "Engine Cylinder Combustion Request";
CM_ SG_ 2364592382 EngnClndr10ExldFrmCmstnRqst "Engine Cylinder 10 Exclude from Combustion Request: Request to the engine ECU to exclude (skip or cut-out) cylinder 10 from combustion.00b = Exclude from Combustion01b = Include for Combustion10b = Reserved11b = Not available/Do not care";
CM_ SG_ 2364592382 EngnClndr11ExldFrmCmstnRqst "Engine Cylinder 11 Exclude from Combustion Request: Request to the engine ECU to exclude (skip or cut-out) cylinder 11 from combustion.00b = Exclude from Combustion01b = Include for Combustion10b = Reserved11b = Not available/Do not care";
CM_ SG_ 2364592382 EngnClndr12ExldFrmCmstnRqst "Engine Cylinder 12 Exclude from Combustion Request: Request to the engine ECU to exclude (skip or cut-out) cylinder 12 from combustion.00b = Exclude from Combustion01b = Include for Combustion10b = Reserved11b = Not available/Do not care";
CM_ SG_ 2364592382 EngnClndr13ExldFrmCmstnRqst "Engine Cylinder 13 Exclude from Combustion Request: Request to the engine ECU to exclude (skip or cut-out) cylinder 13 from combustion.00b = Exclude from Combustion01b = Include for Combustion10b = Reserved11b = Not available/Do not care";
CM_ SG_ 2364592382 EngnClndr14ExldFrmCmstnRqst "Engine Cylinder 14 Exclude from Combustion Request: Request to the engine ECU to exclude (skip or cut-out) cylinder 14 from combustion.00b = Exclude from Combustion01b = Include for Combustion10b = Reserved11b = Not available/Do not care";
CM_ SG_ 2364592382 EngnClndr15ExldFrmCmstnRqst "Engine Cylinder 15 Exclude from Combustion Request: Request to the engine ECU to exclude (skip or cut-out) cylinder 15 from combustion.00b = Exclude from Combustion01b = Include for Combustion10b = Reserved11b = Not available/Do not care";
CM_ SG_ 2364592382 EngnClndr16ExldFrmCmstnRqst "Engine Cylinder 16 Exclude from Combustion Request: Request to the engine ECU to exclude (skip or cut-out) cylinder 16 from combustion.00b = Exclude from Combustion01b = Include for Combustion10b = Reserved11b = Not available/Do not care";
CM_ SG_ 2364592382 EngnClndr17ExldFrmCmstnRqst "Engine Cylinder 17 Exclude from Combustion Request: Request to the engine ECU to exclude (skip or cut-out) cylinder 17 from combustion.00b = Exclude from Combustion01b = Include for Combustion10b = Reserved11b = Not available/Do not care";
CM_ SG_ 2364592382 EngnClndr18ExldFrmCmstnRqst "Engine Cylinder 18 Exclude from Combustion Request: Request to the engine ECU to exclude (skip or cut-out) cylinder 18 from combustion.00b = Exclude from Combustion01b = Include for Combustion10b = Reserved11b = Not available/Do not care";
CM_ SG_ 2364592382 EngnClndr19ExldFrmCmstnRqst "Engine Cylinder 19 Exclude from Combustion Request: Request to the engine ECU to exclude (skip or cut-out) cylinder 19 from combustion.00b = Exclude from Combustion01b = Include for Combustion10b = Reserved11b = Not available/Do not care";
CM_ SG_ 2364592382 EngnClndr1ExldFrmCmstnRqst "Engine Cylinder 1 Exclude from Combustion Request: Request to the engine ECU to exclude (skip or cut-out) cylinder 1 from combustion.00b = Exclude from Combustion01b = Include for Combustion10b = Reserved11b = Not available/Do not care";
CM_ SG_ 2364592382 EngnClndr20ExldFrmCmstnRqst "Engine Cylinder 20 Exclude from Combustion Request: Request to the engine ECU to exclude (skip or cut-out) cylinder 20 from combustion.00b = Exclude from Combustion01b = Include for Combustion10b = Reserved11b = Not available/Do not care";
CM_ SG_ 2364592382 EngnClndr21ExldFrmCmstnRqst "Engine Cylinder 21 Exclude from Combustion Request: Request to the engine ECU to exclude (skip or cut-out) cylinder 21 from combustion.00b = Exclude from Combustion01b = Include for Combustion10b = Reserved11b = Not available/Do not care";
CM_ SG_ 2364592382 EngnClndr22ExldFrmCmstnRqst "Engine Cylinder 22 Exclude from Combustion Request: Request to the engine ECU to exclude (skip or cut-out) cylinder 22 from combustion.00b = Exclude from Combustion01b = Include for Combustion10b = Reserved11b = Not available/Do not care";
CM_ SG_ 2364592382 EngnClndr23ExldFrmCmstnRqst "Engine Cylinder 23 Exclude from Combustion Request: Request to the engine ECU to exclude (skip or cut-out) cylinder 23 from combustion.00b = Exclude from Combustion01b = Include for Combustion10b = Reserved11b = Not available/Do not care";
CM_ SG_ 2364592382 EngnClndr24ExldFrmCmstnRqst "Engine Cylinder 24 Exclude from Combustion Request: Request to the engine ECU to exclude (skip or cut-out) cylinder 24 from combustion.00b = Exclude from Combustion01b = Include for Combustion10b = Reserved11b = Not available/Do not care";
CM_ SG_ 2364592382 EngnClndr2ExldFrmCmstnRqst "Engine Cylinder 2 Exclude from Combustion Request: Request to the engine ECU to exclude (skip or cut-out) cylinder 2 from combustion.00b = Exclude from Combustion01b = Include for Combustion10b = Reserved11b = Not available/Do not care";
CM_ SG_ 2364592382 EngnClndr3ExldFrmCmstnRqst "Engine Cylinder 3 Exclude from Combustion Request: Request to the engine ECU to exclude (skip or cut-out) cylinder 3 from combustion.00b = Exclude from Combustion01b = Include for Combustion10b = Reserved11b = Not available/Do not care";
CM_ SG_ 2364592382 EngnClndr4ExldFrmCmstnRqst "Engine Cylinder 4 Exclude from Combustion Request: Request to the engine ECU to exclude (skip or cut-out) cylinder 4 from combustion.00b = Exclude from Combustion01b = Include for Combustion10b = Reserved11b = Not available/Do not care";
CM_ SG_ 2364592382 EngnClndr5ExldFrmCmstnRqst "Engine Cylinder 5 Exclude from Combustion Request: Request to the engine ECU to exclude (skip or cut-out) cylinder 5 from combustion.00b = Exclude from Combustion01b = Include for Combustion10b = Reserved11b = Not available/Do not care";
CM_ SG_ 2364592382 EngnClndr6ExldFrmCmstnRqst "Engine Cylinder 6 Exclude from Combustion Request: Request to the engine ECU to exclude (skip or cut-out) cylinder 6 from combustion.00b = Exclude from Combustion01b = Include for Combustion10b = Reserved11b = Not available/Do not care";
CM_ SG_ 2364592382 EngnClndr7ExldFrmCmstnRqst "Engine Cylinder 7 Exclude from Combustion Request: Request to the engine ECU to exclude (skip or cut-out) cylinder 7 from combustion.00b = Exclude from Combustion01b = Include for Combustion10b = Reserved11b = Not available/Do not care";
CM_ SG_ 2364592382 EngnClndr8ExldFrmCmstnRqst "Engine Cylinder 8 Exclude from Combustion Request: Request to the engine ECU to exclude (skip or cut-out) cylinder 8 from combustion.00b = Exclude from Combustion01b = Include for Combustion10b = Reserved11b = Not available/Do not care";
CM_ SG_ 2364592382 EngnClndr9ExldFrmCmstnRqst "Engine Cylinder 9 Exclude from Combustion Request: Request to the engine ECU to exclude (skip or cut-out) cylinder 9 from combustion.00b = Exclude from Combustion01b = Include for Combustion10b = Reserved11b = Not available/Do not care";
CM_ SG_ 2364592382 NmrOfEngnClndrsTExldFrmCmstn "Number of Engine Cylinders to Exclude from Combustion: Request to the engine ECU for the number of cylinders to exclude from combustion (cut-out or skip) for a given instance in time.  The engine ECU can decide on the cylinders to exclude from combus...";
CM_ BO_ 2364592638 "Engine Cylinder Head Bypass Actuator 1";
CM_ SG_ 2364592638 EngnClndrHdBpssAttr1DsrdPstn "Engine Cylinder Head Bypass Actuator 1 Desired Position: Requested position of Engine Cylinder Head Bypass actuator by engine ECM, where 0% represents bypass fully closed and 100% represents fully open. This is the position that the device is attempt...";
CM_ SG_ 2364592638 EngnClndrHdBpssAttr1OprtnStts "Engine Cylinder Head Bypass Actuator 1 Operation Status: Identifies the status of Engine Cylinder Head Bypass Actuator 1.Cylinder head bypass valve is used to release the air at the high pressure compressor outlet into turbocharger turbine inlet when...";
CM_ SG_ 2364592638 EngnClndrHdBpssAttr1Pstn "Engine Cylinder Head Bypass Actuator 1 Position: Actual position of Engine Cylinder Head Bypass actuator, where 0% represents fully closed and 100% represents fully open.Cylinder Head bypass valve is used to release the air at the high pressure compr...";
CM_ SG_ 2364592638 EngnClndrHdBpssAttr1Tmprtr "Engine Cylinder Head Bypass Actuator 1 Temperature: Temperature of the Engine Cylinder Head Bypass Actuator 1 drive circuitry. Temperature excursions may affect the torque output.Cylinder Head bypass valve is used to release the air at the high press...";
CM_ SG_ 2364592638 EngnClndrHdBpssAttr1TmprtrStts "Engine Cylinder Head Bypass Actuator 1 Temperature Status: Identifies the status of the Engine Cylinder Head Bypass Blowoff Actuator 1 drive circuitry temperature. Temperature excursions may affect the torque output.Cylinder Head bypass valve is used...";
CM_ SG_ 2364592638 EngnClndrHdBpssAttr1PrlmnrFm "Engine Cylinder Head Bypass Actuator 1 Preliminary FMI: Used to identify the applicable J1939-73 FMI detected in Engine Cylinder Head Bypass Actuator 1 by the manufacturer's software. When there are multiple failures, the most severe is transmitted.A...";
CM_ BO_ 2364592894 "Engine Electronic Controller 18";
CM_ SG_ 2364592894 EngineIntakeAirSourceValve "Engine Intake Air Source Valve: Status of the actuator/valve in the airbox used to source engine intake air from either the engine compartment or external to the vehicle.00b = Off01b = On10b = Error11b = Not available";
CM_ SG_ 2364592894 EngnClndrHdBpssAttr1Cmmnd "Engine Cylinder Head Bypass Actuator 1 Command: Command to cylinder head bypass actuator 1, normalized to percent, where 0% nominally represents fully closed (No Flow) and 100% represents fully open (Max Flow). The purpose of the cylinder bypass valv...";
CM_ SG_ 2364592894 EngnExhstGsRstrtnVlvPstn "Engine Exhaust Gas Restriction Valve Position: The position of the exhaust gas restriction valve expressed as a percentage of full travel. 0% means the valve is closed and no exhaust gas is flowing into the intake air stream. 100% means the valve is ...";
CM_ BO_ 2364593150 "Predictive Cruise Control 1";
CM_ SG_ 2364593150 PrdtvCrsCntrlDrvlnDsnggInhtRqst "Predictive Cruise Control Driveline Disengage Inhibit Request: Request to temporarily inhibit a fuel saving feature that would normally open the driveline. Under certain conditions and with knowledge of the terrain, inhibiting this feature may improv...";
CM_ SG_ 2364593150 PrdtvCrsCntrlSpdEvntIndtr "Predictive Cruise Control Speed Event Indicator: Indicates to the operator that a predictive cruise control (PCC) speed event is active. Typically, this will correspond to a Predictive Cruise Control Set Speed Offset (SPN 7316) request to increase or...";
CM_ SG_ 2364593150 PrdtvCrsCntrlStSpdOffst "Predictive Cruise Control Set Speed Offset: The amount by which the actual set point used by the cruise control algorithm should be changed as determined by external factors (e.g., anticipated road grade).If SPN 7317 indicates Enabled (0001b) and if ...";
CM_ SG_ 2364593150 PredictiveCruiseControlState "Predictive Cruise Control State: Indicates the state of the PCC controller.If this parameter is 0001b, the cruise control set point may be modified by the Predictive Cruise Control Set Speed Offset (SPN 7316) . For states other than 0001, the value i...";
CM_ SG_ 2364593150 RoadwayNextGrade "Roadway Next Grade: Road grade at an upcoming distance.  If SPN 9199 is supported, then this the road grade at the distance specified by SPN 9199. Positive numbers indicate uphill grade, negative are downhill for vehicle direction of travel.   For gr...";
CM_ SG_ 2364593150 RoadwayNextGradeDistance "Roadway Next Grade Distance: The distance from the current vehicle position to the grade indicated in SPN 7433.";
CM_ SG_ 2364593150 RoadwayPresentGrade "Roadway Present Grade: Road grade at present vehicle position. Positive numbers indicate uphill grade, negative are downhill for present vehicle direction of travel. For grades beyond the limits of the parameter, the limit value shall be reported.Par...";
CM_ SG_ 2364593150 VhlSpdCntrlOvrrdEvntIndtr "Vehicle Speed Control Override Event Indicator: Indicates to the operator that a Speed Control override event is active.  Speed Control refers to retarders or methods of automatically limiting vehicle speed, for instance on downhill grades.  An activ...";
CM_ SG_ 2364593150 VhlSpdCntrlOvrrdRqst "Vehicle Speed Control Override Request: Speed control override requested. Indicates that the minimum restriction of speed is desired, for instance when travelling downhill towards an impending uphill grade. This is not a request to inhibit engine bra...";
CM_ SG_ 2364593150 PrdtvCrsCntrlEvntInRng "Predictive Cruise Control Event in Range: Indicates that an event, such as a grade, is detected within the range of the predictive cruise control (PCC) look-ahead distance.00b = No PCC event in range01b = PCC event in range10b = Error11b = Not availa...";
CM_ BO_ 2364597758 "Engine Ignition Timing Offset 1";
CM_ SG_ 2364597758 EngnClndr1IgntnTmngOffst "Engine Cylinder 1 Ignition Timing Offset: The ignition timing offset for Cylinder 1 from the engine timing advance (SPN 7355) as a command to the ignition control module. Positive values command an increasingly advanced timing.";
CM_ SG_ 2364597758 EngnClndr2IgntnTmngOffst "Engine Cylinder 2 Ignition Timing Offset: The ignition timing offset for Cylinder 2 from the engine timing advance (SPN 7355) as a command to the ignition control module. Positive values command an increasingly advanced timing.";
CM_ SG_ 2364597758 EngnClndr3IgntnTmngOffst "Engine Cylinder 3 Ignition Timing Offset: The ignition timing offset for Cylinder 3 from the engine timing advance (SPN 7355) as a command to the ignition control module. Positive values command an increasingly advanced timing.";
CM_ SG_ 2364597758 EngnClndr4IgntnTmngOffst "Engine Cylinder 4 Ignition Timing Offset: The ignition timing offset for Cylinder 4 from the engine timing advance (SPN 7355) as a command to the ignition control module. Positive values command an increasingly advanced timing.";
CM_ SG_ 2364597758 EngnClndr5IgntnTmngOffst "Engine Cylinder 5 Ignition Timing Offset: The ignition timing offset for Cylinder 5 from the engine timing advance (SPN 7355) as a command to the ignition control module. Positive values command an increasingly advanced timing.";
CM_ SG_ 2364597758 EngnClndr6IgntnTmngOffst "Engine Cylinder 6 Ignition Timing Offset: The ignition timing offset for Cylinder 6 from the engine timing advance (SPN 7355) as a command to the ignition control module. Positive values command an increasingly advanced timing.";
CM_ SG_ 2364597758 EngnClndr7IgntnTmngOffst "Engine Cylinder 7 Ignition Timing Offset: The ignition timing offset for Cylinder 7 from the engine timing advance (SPN 7355) as a command to the ignition control module. Positive values command an increasingly advanced timing.";
CM_ SG_ 2364597758 EngnClndr8IgntnTmngOffst "Engine Cylinder 8 Ignition Timing Offset: The ignition timing offset for Cylinder 8 from the engine timing advance (SPN 7355) as a command to the ignition control module. Positive values command an increasingly advanced timing.";
CM_ BO_ 2364598014 "Engine Ignition Timing Offset 2";
CM_ SG_ 2364598014 EngnClndr10IgntnTmngOffst "Engine Cylinder 10 Ignition Timing Offset: The ignition timing offset for Cylinder 10 from the engine timing advance (SPN 7355) as a command to the ignition control module. Positive values command an increasingly advanced timing.";
CM_ SG_ 2364598014 EngnClndr11IgntnTmngOffst "Engine Cylinder 11 Ignition Timing Offset: The ignition timing offset for Cylinder 11 from the engine timing advance (SPN 7355) as a command to the ignition control module. Positive values command an increasingly advanced timing.";
CM_ SG_ 2364598014 EngnClndr12IgntnTmngOffst "Engine Cylinder 12 Ignition Timing Offset: The ignition timing offset for Cylinder 12 from the engine timing advance (SPN 7355) as a command to the ignition control module. Positive values command an increasingly advanced timing.";
CM_ SG_ 2364598014 EngnClndr13IgntnTmngOffst "Engine Cylinder 13 Ignition Timing Offset: The ignition timing offset for Cylinder 13 from the engine timing advance (SPN 7355) as a command to the ignition control module. Positive values command an increasingly advanced timing.";
CM_ SG_ 2364598014 EngnClndr14IgntnTmngOffst "Engine Cylinder 14 Ignition Timing Offset: The ignition timing offset for Cylinder 14 from the engine timing advance (SPN 7355) as a command to the ignition control module. Positive values command an increasingly advanced timing.";
CM_ SG_ 2364598014 EngnClndr15IgntnTmngOffst "Engine Cylinder 15 Ignition Timing Offset: The ignition timing offset for Cylinder 15 from the engine timing advance (SPN 7355) as a command to the ignition control module. Positive values command an increasingly advanced timing.";
CM_ SG_ 2364598014 EngnClndr16IgntnTmngOffst "Engine Cylinder 16 Ignition Timing Offset: The ignition timing offset for Cylinder 16 from the engine timing advance (SPN 7355) as a command to the ignition control module. Positive values command an increasingly advanced timing.";
CM_ SG_ 2364598014 EngnClndr9IgntnTmngOffst "Engine Cylinder 9 Ignition Timing Offset: The ignition timing offset for Cylinder 9 from the engine timing advance (SPN 7355) as a command to the ignition control module. Positive values command an increasingly advanced timing.";
CM_ BO_ 2364598270 "Engine Ignition Timing Offset 3";
CM_ SG_ 2364598270 EngnClndr17IgntnTmngOffst "Engine Cylinder 17 Ignition Timing Offset: The ignition timing offset for Cylinder 17 from the engine timing advance (SPN 7355) as a command to the ignition control module. Positive values command an increasingly advanced timing.";
CM_ SG_ 2364598270 EngnClndr18IgntnTmngOffst "Engine Cylinder 18 Ignition Timing Offset: The ignition timing offset for Cylinder 18 from the engine timing advance (SPN 7355) as a command to the ignition control module. Positive values command an increasingly advanced timing.";
CM_ SG_ 2364598270 EngnClndr19IgntnTmngOffst "Engine Cylinder 19 Ignition Timing Offset: The ignition timing offset for Cylinder 19 from the engine timing advance (SPN 7355) as a command to the ignition control module. Positive values command an increasingly advanced timing.";
CM_ SG_ 2364598270 EngnClndr20IgntnTmngOffst "Engine Cylinder 20 Ignition Timing Offset: The ignition timing offset for Cylinder 20 from the engine timing advance (SPN 7355) as a command to the ignition control module. Positive values command an increasingly advanced timing.";
CM_ SG_ 2364598270 EngnClndr21IgntnTmngOffst "Engine Cylinder 21 Ignition Timing Offset: The ignition timing offset for Cylinder 21 from the engine timing advance (SPN 7355) as a command to the ignition control module. Positive values command an increasingly advanced timing.";
CM_ SG_ 2364598270 EngnClndr22IgntnTmngOffst "Engine Cylinder 22 Ignition Timing Offset: The ignition timing offset for Cylinder 22 from the engine timing advance (SPN 7355) as a command to the ignition control module. Positive values command an increasingly advanced timing.";
CM_ SG_ 2364598270 EngnClndr23IgntnTmngOffst "Engine Cylinder 23 Ignition Timing Offset: The ignition timing offset for Cylinder 23 from the engine timing advance (SPN 7355) as a command to the ignition control module. Positive values command an increasingly advanced timing.";
CM_ SG_ 2364598270 EngnClndr24IgntnTmngOffst "Engine Cylinder 24 Ignition Timing Offset: The ignition timing offset for Cylinder 24 from the engine timing advance (SPN 7355) as a command to the ignition control module. Positive values command an increasingly advanced timing.";
CM_ BO_ 2364598526 "Engine Throttle / Fuel Actuator Control Command 2";
CM_ SG_ 2364598526 EngnFlAttr3CntrlCmmnd "Engine Fuel Actuator 3 Control Command: The control command to fuel actuator 3, normalized to percent, where 0% represents fully closed and 100% represents fully open.  Typically, this fuel actuator is used to regulate low pressure natural gas flow r...";
CM_ SG_ 2364598526 EngnFlAttr4CntrlCmmnd "Engine Fuel Actuator 4 Control Command: The control command to fuel actuator 4, normalized to percent, where 0% represents fully closed and 100% represents fully open.  Typically, this fuel actuator is used to regulate low pressure natural gas flow r...";
CM_ SG_ 2364598526 EngnFlAttr1MtrCrrntDsl "Engine Fuel Actuator 1 Motor Current Disable: Command to disable power to motor in the actuator to prevent unnecessary load on the component.00b = Do Not Disable01b = Disable10b = Reserved11b = Don't Care/Take No Action";
CM_ SG_ 2364598526 EngnFlAttr2MtrCrrntDsl "Engine Fuel Actuator 2 Motor Current Disable: Command to disable power to motor in the second actuator to prevent unnecessary load on the component.00b = Do Not Disable01b = Disable10b = Reserved11b = Don't Care/Take No Action";
CM_ BO_ 2364602878 "Engine Valve Controller";
CM_ SG_ 2364602878 EngnVlvCntrlMdl1PrlmnrFm "Engine Valve Control Module 1 Preliminary FMI: Used to identify the applicable J1939-73 FMI detected in Engine Valve Control Module 1 by the manufacturer's software.  When there are multiple failures, the most severe is transmitted.A value of 31 is s...";
CM_ SG_ 2364602878 EngnVlvCntrlMdl2PrlmnrFm "Engine Valve Control Module 2 Preliminary FMI: Used to identify the applicable J1939-73 FMI detected in Engine Valve Control Module 2 by the manufacturer's software.  When there are multiple failures, the most severe is transmitted.A value of 31 is s...";
CM_ SG_ 2364602878 EngnVlvCntrlMdl3PrlmnrFm "Engine Valve Control Module 3 Preliminary FMI: Used to identify the applicable J1939-73 FMI detected in Engine Valve Control Module 3 by the manufacturer's software.  When there are multiple failures, the most severe is transmitted.A value of 31 is s...";
CM_ SG_ 2364602878 EngnVlvCntrlMdl4PrlmnrFm "Engine Valve Control Module 4 Preliminary FMI: Used to identify the applicable J1939-73 FMI detected in Engine Valve Control Module 4 by the manufacturer's software.  When there are multiple failures, the most severe is transmitted.A value of 31 is s...";
CM_ SG_ 2364602878 EngnVlvCntrlMdl5PrlmnrFm "Engine Valve Control Module 5 Preliminary FMI: Used to identify the applicable J1939-73 FMI detected in Engine Valve Control Module 5 by the manufacturer's software.  When there are multiple failures, the most severe is transmitted.A value of 31 is s...";
CM_ SG_ 2364602878 EngnVlvCntrlMdl6PrlmnrFm "Engine Valve Control Module 6 Preliminary FMI: Used to identify the applicable J1939-73 FMI detected in Engine Valve Control Module 6 by the manufacturer's software.  When there are multiple failures, the most severe is transmitted.A value of 31 is s...";
CM_ SG_ 2364602878 EngnVlvCntrlMdl7PrlmnrFm "Engine Valve Control Module 7 Preliminary FMI: Used to identify the applicable J1939-73 FMI detected in Engine Valve Control Module 7 by the manufacturer's software. When there are multiple failures, the most severe is transmitted.A value of 31 is se...";
CM_ SG_ 2364602878 EngnVlvCntrlMdl8PrlmnrFm "Engine Valve Control Module 8 Preliminary FMI: Used to identify the applicable J1939-73 FMI detected in Engine Valve Control Module 8 by the manufacturer's software.  When there are multiple failures, the most severe is transmitted.A value of 31 is s...";
CM_ BO_ 2364603134 "Electronic Transmission Controller 13";
CM_ SG_ 2364603134 MxmmFrwrdTrnsmssnOtptShftSpd "Maximum Forward Transmission Output Shaft Speed: Maximum transmission output shaft speed that can be achieved in the forward direction, based on current operating conditions.";
CM_ SG_ 2364603134 MxmmRvrsTrnsmssnOtptShftSpd "Maximum Reverse Transmission Output Shaft Speed: Maximum transmission output shaft speed that can be achieved in the reverse direction, based on current operating conditions.";
CM_ SG_ 2364603134 TransmissionMode11Indicator "Transmission Mode 11 Indicator: This state signal is the transmission's indication that it is operating under transmission mode 11 (SPN 12949) as commanded via the TC2 message (PGN 3328).  The definition of the transmission mode is left to the discre...";
CM_ SG_ 2364603134 TransmissionMode12Indicator "Transmission Mode 12 Indicator: This state signal is the transmission's indication that it is operating under transmission mode 12 (SPN 12950) as commanded via the TC2 message (PGN 3328).  The definition of the transmission mode is left to the discre...";
CM_ SG_ 2364603134 TransmissionMode13Indicator "Transmission Mode 13 Indicator: This state signal is the transmission's indication that it is operating under transmission mode 13 (SPN 12951) as commanded via the TC2 message (PGN 3328).  The definition of the transmission mode is left to the discre...";
CM_ SG_ 2364603134 TransmissionMode14Indicator "Transmission Mode 14 Indicator: This state signal is the transmission's indication that it is operating under transmission mode 14 (SPN 12952) as commanded via the TC2 message (PGN 3328).  The definition of the transmission mode is left to the discre...";
CM_ SG_ 2364603134 TransmissionMode15Indicator "Transmission Mode 15 Indicator: This state signal is the transmission's indication that it is operating under transmission mode 15 (SPN 12953) as commanded via the TC2 message (PGN 3328).  The definition of the transmission mode is left to the discre...";
CM_ SG_ 2364603134 TransmissionMode16Indicator "Transmission Mode 16 Indicator: This state signal is the transmission's indication that it is operating under transmission mode 16 (SPN 12954) as commanded via the TC2 message (PGN 3328).  The definition of the transmission mode is left to the discre...";
CM_ SG_ 2364603134 TransmissionMode17Indicator "Transmission Mode 17 Indicator: This state signal is the transmission's indication that it is operating under transmission mode 17 (SPN 12955) as commanded via the TC2 message (PGN 3328).  The definition of the transmission mode is left to the discre...";
CM_ SG_ 2364603134 TransmissionMode18Indicator "Transmission Mode 18 Indicator: This state signal is the transmission's indication that it is operating under transmission mode 18 (SPN 12956) as commanded via the TC2 message (PGN 3328).  The definition of the transmission mode is left to the discre...";
CM_ SG_ 2364603134 TransmissionMode19Indicator "Transmission Mode 19 Indicator: This state signal is the transmission's indication that it is operating under transmission mode 19 (SPN 12957) as commanded via the TC2 message (PGN 3328).  The definition of the transmission mode is left to the discre...";
CM_ SG_ 2364603134 TransmissionMode20Indicator "Transmission Mode 20 Indicator: This state signal is the transmission's indication that it is operating under transmission mode 20 (SPN 12958) as commanded via the TC2 message (PGN 3328).  The definition of the transmission mode is left to the discre...";
CM_ SG_ 2364603134 SAddssOAtvOPdTsssRqstdG "Source Address of Active or Pending Transmission Requested Gear: This parameter indicates the source address of the device whose SPN 525 [Transmission Requested Gear] request is currently being acted upon by the transmission. If transmission response...";
CM_ BO_ 2364603390 "Aftertreatment 1 SCR Dosing System Requests 3";
CM_ SG_ 2364603390 Atttt1DsExstFdDsVv1Cd "Aftertreatment 1 Diesel Exhaust Fluid Doser Valve 1 Command: Command (in percent) sent to the diesel exhaust fluid (DEF) injector to control the amount of DEF being injected into the aftreatment exhaust stream.0% closes the valve; 100% fully opens th...";
CM_ SG_ 2364603390 Atttt1DsExstFdRqstdQttOIttHRst "Aftertreatment 1 Diesel Exhaust Fluid Requested Quantity of Integrator (High Resolution): Represents the command for the diesel exhaust fluid quantity integrator in the dosing control unit. See SPN 4350 for alternate resolution.";
CM_ SG_ 2364603390 Atttt1DsExstFdDsVv2Cd "Aftertreatment 1 Diesel Exhaust Fluid Doser Valve 2 Command: Command (in percent) sent to the second valve of the diesel exhaust fluid (DEF) injector to control the amount of DEF being injected into the aftreatment exhaust stream.0% closes the valve;...";
CM_ BO_ 2364603646 "Aftertreatment 2 SCR Dosing System Requests 3";
CM_ SG_ 2364603646 Atttt2DsExstFdRqstdQttOIttHRst "Aftertreatment 2 Diesel Exhaust Fluid Requested Quantity of Integrator (High Resolution): Represents the command for the diesel exhaust fluid quantity integrator in the dosing control unit. See SPN 4403 for alternate resolution.";
CM_ SG_ 2364603646 Atttt2DsExstFdDsVv1Cd "Aftertreatment 2 Diesel Exhaust Fluid Doser Valve 1 Command: Command (in percent) sent to the diesel exhaust fluid (DEF) injector to control the amount of DEF being injected into the aftreatment system 2 (bank 2) exhaust stream.0% closes the valve; 1...";
CM_ SG_ 2364603646 Atttt2DsExstFdDsVv2Cd "Aftertreatment 2 Diesel Exhaust Fluid Doser Valve 2 Command: Command (in percent) sent to the second valve of the diesel exhaust fluid (DEF) injector to control the amount of DEF being injected into the aftreatment system 2 (bank 2) exhaust stream.0%...";
CM_ BO_ 2364603902 "Aftertreatment 1 SCR Dosing System Information 4";
CM_ SG_ 2364603902 Atttt1DsExstFdAtQttOIttHRst "Aftertreatment 1 Diesel Exhaust Fluid Actual Quantity of Integrator (High Resolution): The SCR requested diesel exhaust fluid integrator total quantity for aftertreatment system 1 (exhaust bank 1).  See SPN 4333 for alternate resolution.";
CM_ BO_ 2364604158 "Aftertreatment 2 SCR Dosing System Information 4";
CM_ SG_ 2364604158 Atttt2DsExstFdAtQttOIttHRst "Aftertreatment 2 Diesel Exhaust Fluid Actual Quantity of Integrator (High Resolution): The SCR requested diesel exhaust fluid integrator total quantity for aftertreatment system 2 (exhaust bank 2).  See SPN 4386 for alternate resolution.";
CM_ BO_ 2364605438 "Generator Trip Energy";
CM_ SG_ 2364605438 GeneratorTripKvarHoursExport "Generator Trip kVAr Hours Export: The trip AC reactive energy exported by the generator since the last reset of the trip kVArh meter.This value will be reset by the user at will.";
CM_ SG_ 2364605438 GeneratorTripKwHoursExport "Generator Trip kW Hours Export: The total kilowatt-hours that have been exported by the generator since the last reset of the trip kWh meter.This value will be reset by the user at will.";
CM_ BO_ 2364605950 "Hydraulic Pressure Displacement";
CM_ SG_ 2364605950 HydraulicLinePressure "Hydraulic Line Pressure: The pressure of the hydraulic fluid, measured in the hydraulic line.";
CM_ SG_ 2364605950 MechanicalMovementAngle "Mechanical Movement Angle: The angle of rotation of the mechanical component.The increase and decrease of the value (i.e. rotation about the X-axis) is in accordance to the right-hand rule, as specified in SAE J670, with the positive X axis directed ...";
CM_ BO_ 2364606718 "High Voltage Energy Storage System Module Status 1";
CM_ SG_ 2364606718 HvessModule1OperationalStatus "HVESS Module 1 Operational Status: Operational Status of Module 1 in the High Voltage Energy Storage System (or Pack 1 in systems with only one pack).  Not Operational is used when the module is initializing or not able to function (e.g. internal mod...";
CM_ SG_ 2364606718 HvessModule2OperationalStatus "HVESS Module 2 Operational Status: Operational Status of Module 2 in the High Voltage Energy Storage System (or Pack 1 in systems with only one pack).  Not Operational is used when the module is initializing or not able to function (e.g. internal mod...";
CM_ SG_ 2364606718 HvessModule3OperationalStatus "HVESS Module 3 Operational Status: Operational Status of Module 3 in the High Voltage Energy Storage System (or Pack 1 in systems with only one pack).  Not Operational is used when the module is initializing or not able to function (e.g. internal mod...";
CM_ SG_ 2364606718 HvessModule4OperationalStatus "HVESS Module 4 Operational Status: Operational Status of Module 4 in the High Voltage Energy Storage System (or Pack 1 in systems with only one pack).  Not Operational is used when the module is initializing or not able to function (e.g. internal mod...";
CM_ SG_ 2364606718 HvessModule5OperationalStatus "HVESS Module 5 Operational Status: Operational Status of Module 5 in the High Voltage Energy Storage System (or Pack 1 in systems with only one pack).  Not Operational is used when the module is initializing or not able to function (e.g. internal mod...";
CM_ SG_ 2364606718 HvessModule6OperationalStatus "HVESS Module 6 Operational Status: Operational Status of Module 6 in the High Voltage Energy Storage System (or Pack 1 in systems with only one pack).  Not Operational is used when the module is initializing or not able to function (e.g. internal mod...";
CM_ SG_ 2364606718 HvessModule7OperationalStatus "HVESS Module 7 Operational Status: Operational Status of Module 7 in the High Voltage Energy Storage System (or Pack 1 in systems with only one pack).  Not Operational is used when the module is initializing or not able to function (e.g. internal mod...";
CM_ SG_ 2364606718 HvessModule8OperationalStatus "HVESS Module 8 Operational Status: Operational Status of Module 8 in the High Voltage Energy Storage System (or Pack 1 in systems with only one pack).  Not Operational is used when the module is initializing or not able to function (e.g. internal mod...";
CM_ SG_ 2364606718 HvessModule9OperationalStatus "HVESS Module 9 Operational Status: Operational Status of Module 9 in the High Voltage Energy Storage System (or Pack 1 in systems with only one pack).  Not Operational is used when the module is initializing or not able to function (e.g. internal mod...";
CM_ SG_ 2364606718 HvessModule10OperationalStatus "HVESS Module 10 Operational Status: Operational Status of Module 10 in the High Voltage Energy Storage System (or Pack 1 in systems with only one pack).  Not Operational is used when the module is initializing or not able to function (e.g. internal m...";
CM_ SG_ 2364606718 HvessModule11OperationalStatus "HVESS Module 11 Operational Status: Operational Status of Module 11 in the High Voltage Energy Storage System (or Pack 1 in systems with only one pack).  Not Operational is used when the module is initializing or not able to function (e.g. internal m...";
CM_ SG_ 2364606718 HvessModule12OperationalStatus "HVESS Module 12 Operational Status: Operational Status of Module 12 in the High Voltage Energy Storage System (or Pack 1 in systems with only one pack).  Not Operational is used when the module is initializing or not able to function (e.g. internal m...";
CM_ SG_ 2364606718 HvessModule13OperationalStatus "HVESS Module 13 Operational Status: Operational Status of Module 13 in the High Voltage Energy Storage System (or Pack 1 in systems with only one pack).  Not Operational is used when the module is initializing or not able to function (e.g. internal m...";
CM_ SG_ 2364606718 HvessModule14OperationalStatus "HVESS Module 14 Operational Status: Operational Status of Module 14 in the High Voltage Energy Storage System (or Pack 1 in systems with only one pack).  Not Operational is used when the module is initializing or not able to function (e.g. internal m...";
CM_ SG_ 2364606718 HvessModule15OperationalStatus "HVESS Module 15 Operational Status: Operational Status of Module 15 in the High Voltage Energy Storage System (or Pack 1 in systems with only one pack).  Not Operational is used when the module is initializing or not able to function (e.g. internal m...";
CM_ SG_ 2364606718 HvessModule16OperationalStatus "HVESS Module 16 Operational Status: Operational Status of Module 16 in the High Voltage Energy Storage System (or Pack 1 in systems with only one pack).  Not Operational is used when the module is initializing or not able to function (e.g. internal m...";
CM_ SG_ 2364606718 HvessModule17OperationalStatus "HVESS Module 17 Operational Status: Operational Status of Module 17 in the High Voltage Energy Storage System (or Pack 1 in systems with only one pack).  Not Operational is used when the module is initializing or not able to function (e.g. internal m...";
CM_ SG_ 2364606718 HvessModule18OperationalStatus "HVESS Module 18 Operational Status: Operational Status of Module 18 in this High Voltage Energy Storage System (or Pack 1 in systems with only one pack).  Not Operational is used when the module is initializing or not able to function (e.g. internal ...";
CM_ SG_ 2364606718 HvessModule19OperationalStatus "HVESS Module 19 Operational Status: Operational Status of Module 19 in this High Voltage Energy Storage System (or Pack 1 in systems with only one pack).  Not Operational is used when the module is initializing or not able to function (e.g. internal ...";
CM_ SG_ 2364606718 HvessModule20OperationalStatus "HVESS Module 20 Operational Status: Operational Status of Module 20 in this High Voltage Energy Storage System (or Pack 1 in systems with only one pack).  Not Operational is used when the module is initializing or not able to function (e.g. internal ...";
CM_ SG_ 2364606718 HvessModule21OperationalStatus "HVESS Module 21 Operational Status: Operational Status of Module 21 in this High Voltage Energy Storage System (or Pack 1 in systems with only one pack).  Not Operational is used when the module is initializing or not able to function (e.g. internal ...";
CM_ SG_ 2364606718 HvessModule22OperationalStatus "HVESS Module 22 Operational Status: Operational Status of Module 22 in this High Voltage Energy Storage System (or Pack 1 in systems with only one pack).  Not Operational is used when the module is initializing or not able to function (e.g. internal ...";
CM_ SG_ 2364606718 HvessModule23OperationalStatus "HVESS Module 23 Operational Status: Operational Status of Module 23 in this High Voltage Energy Storage System (or Pack 1 in systems with only one pack).  Not Operational is used when the module is initializing or not able to function (e.g. internal ...";
CM_ SG_ 2364606718 HvessModule24OperationalStatus "HVESS Module 24 Operational Status: Operational Status of Module 24 in this High Voltage Energy Storage System (or Pack 1 in systems with only one pack).  Not Operational is used when the module is initializing or not able to function (e.g. internal ...";
CM_ SG_ 2364606718 HvessModule25OperationalStatus "HVESS Module 25 Operational Status: Operational Status of Module 25 in this High Voltage Energy Storage System (or Pack 1 in systems with only one pack).  Not Operational is used when the module is initializing or not able to function (e.g. internal ...";
CM_ SG_ 2364606718 HvessModule26OperationalStatus "HVESS Module 26 Operational Status: Operational Status of Module 26 in this High Voltage Energy Storage System (or Pack 1 in systems with only one pack).  Not Operational is used when the module is initializing or not able to function (e.g. internal ...";
CM_ SG_ 2364606718 HvessModule27OperationalStatus "HVESS Module 27 Operational Status: Operational Status of Module 27 in this High Voltage Energy Storage System (or Pack 1 in systems with only one pack).  Not Operational is used when the module is initializing or not able to function (e.g. internal ...";
CM_ SG_ 2364606718 HvessModule28OperationalStatus "HVESS Module 28 Operational Status: Operational Status of Module 28 in this High Voltage Energy Storage System (or Pack 1 in systems with only one pack).  Not Operational is used when the module is initializing or not able to function (e.g. internal ...";
CM_ SG_ 2364606718 HvessModule29OperationalStatus "HVESS Module 29 Operational Status: Operational Status of Module 29 in this High Voltage Energy Storage System (or Pack 1 in systems with only one pack).  Not Operational is used when the module is initializing or not able to function (e.g. internal ...";
CM_ SG_ 2364606718 HvessModule30OperationalStatus "HVESS Module 30 Operational Status: Operational Status of Module 30 in this High Voltage Energy Storage System (or Pack 1 in systems with only one pack).  Not Operational is used when the module is initializing or not able to function (e.g. internal ...";
CM_ SG_ 2364606718 HvessModule31OperationalStatus "HVESS Module 31 Operational Status: Operational Status of Module 31 in this High Voltage Energy Storage System (or Pack 1 in systems with only one pack).  Not Operational is used when the module is initializing or not able to function (e.g. internal ...";
CM_ SG_ 2364606718 HvessModule32OperationalStatus "HVESS Module 32 Operational Status: Operational Status of Module 32 in this High Voltage Energy Storage System (or Pack 1 in systems with only one pack).  Not Operational is used when the module is initializing or not able to function (e.g. internal ...";
CM_ BO_ 2364606974 "High Voltage Energy Storage System Thermal Management System Status 1";
CM_ SG_ 2364606974 HvssThrmlMngmntSstmSlInptPwr "HVESS Thermal Management System SLI Input Power: This is the low-voltage power consumed by this Thermal Management System (TMS). If there is only one pack, or a single TMS for the entire HVES system, then this represents the total low-voltage power c...";
CM_ SG_ 2364606974 HvssTMtSstHVtIptPw "HVESS Thermal Management System High-Voltage Input Power: This is the high-voltage power consumed by this Thermal Management System (TMS). If there is only one pack, or a single TMS for the entire HVES system, then this represents the total high-volt...";
CM_ SG_ 2364606974 HvssThrmlMngmntSstmCmprssrSpd "HVESS Thermal Management System Compressor Speed: When the High Voltage Energy Storage System (or Pack 1 in systems with only one pack) Thermal Management System is equipped with an active cooling system (e.g. air conditioner), this is the Compressor...";
CM_ SG_ 2364606974 HvssThrmlMngmntSstmRltvHmdt "HVESS Thermal Management System Relative Humidity: When the High Voltage Energy Storage System (or Pack 1 in systems with only one pack) Thermal Management System is equipped with a relative humidity sensor, this is the  measured Relative Humidity.Th...";
CM_ SG_ 2364606974 HvssThrmlMngmntSstmHtrStts "HVESS Thermal Management System Heater Status: The state of the High Voltage Energy Storage System (or Pack 1 in systems with only one pack) heaterThis parameter provides HVES system level information. If there are multiple packs in the system, then ...";
CM_ SG_ 2364606974 HvssThrmlMngmntSstmHvlStts "HVESS Thermal Management System HVIL Status: Status of the High Voltage Interlock Loop from the viewpoint of the High Voltage Energy Storage System Thermal Management System 1.00b = HVIL Closed01b = HVIL Open10b = Error11b = Not Available";
CM_ SG_ 2364606974 HvssThrmlMngmntSstmMd "HVESS Thermal Management System Mode: Indicates the operating mode of the Thermal Management System.  The heat transfer medium may be (e.g. liquid or air).  The cooling system may be fans, liquid coolant, or a combination of mediums.  The system may ...";
CM_ SG_ 2364606974 HvssThrmlMngmntSstmClntLvl "HVESS Thermal Management System Coolant Level: Indicates the coolant level in the High Voltage Energy Storage System (or Pack 1 in systems with only one pack) Thermal Management System.This parameter provides HVES system level information. If there a...";
CM_ SG_ 2364606974 HvssThrmlMngmntSstmClntLvlFll "HVESS Thermal Management System Coolant Level Full: Indicates the coolant tank level is at fulll in the High Voltage Energy Storage System (or Pack 1 in systems with only one pack) Thermal Management System.00b = Coolant Level is not full01b = Coolan...";
CM_ BO_ 2364607230 "High Voltage Energy Storage System Data 8";
CM_ SG_ 2364607230 HvessAverageCellVoltage "HVESS Average Cell Voltage: The average cell voltage in the High Voltage Energy Storage System (or Pack 1 in systems with only one pack).This parameter provides HVES system level information. If there are multiple packs in the system, then both indiv...";
CM_ SG_ 2364607230 HvssHghstCllVltgMdlNmr "HVESS Highest Cell Voltage Module Number: Identifies the location of the module containing SPN 5922 (HVESS Highest Cell Voltage).This parameter provides HVES system level information. If there are multiple packs in the system, then both individual pa...";
CM_ SG_ 2364607230 HvssHghstCllVltgCllNmr "HVESS Highest Cell Voltage Cell Number: Identifies the location of SPN 5922 (HVESS Highest Cell Voltage) within SPN 8236 (HVESS Highest Cell Voltage Module Number).This parameter provides HVES system level information. If there are multiple packs in ...";
CM_ SG_ 2364607230 HvssLwstCllVltgMdlNmr "HVESS Lowest Cell Voltage Module Number: Identifies the location of the module containing SPN 5923 (HVESS Lowest Cell Voltage).This parameter provides HVES system level information. If there are multiple packs in the system, then both individual pack...";
CM_ SG_ 2364607230 HvssLwstCllVltgCllNmr "HVESS Lowest Cell Voltage Cell Number: Identifies the location of SPN 5923 (HVESS Lowest Cell Voltage) within SPN 8238 (HVESS Lowest Cell Voltage Module Number).This parameter provides HVES system level information. If there are multiple packs in the...";
CM_ BO_ 2364607486 "High Voltage Energy Storage System Data 9";
CM_ SG_ 2364607486 HvssHghstCllTmprtrMdlNmr "HVESS Highest Cell Temperature Module Number: Identifies the location of the module containing SPN 8075 (HVESS Highest Cell Temperature).This parameter provides HVES system level information. If there are multiple packs in the system, then both indiv...";
CM_ SG_ 2364607486 HvssHghstCllTmprtrCllNmr "HVESS Highest Cell Temperature Cell Number: Identifies the location of SPN 8075 (HVESS Highest Cell Temperature) within SPN 8241 (HVESS Highest Cell Temperature Module Number).This parameter provides HVES system level information. If there are multip...";
CM_ SG_ 2364607486 HvssLwstCllTmprtrMdlNmr "HVESS Lowest Cell Temperature Module Number: Identifies the location of the module containing SPN 8076 (HVESS Lowest Cell Temperature ).This parameter provides HVES system level information. If there are multiple packs in the system, then both indivi...";
CM_ SG_ 2364607486 HvssLwstCllTmprtrCllNmr "HVESS Lowest Cell Temperature Cell Number: Identifies the location of SPN 8076 (HVESS Lowest Cell Temperature) within SPN 8243 (HVESS Lowest Cell Temperature Module Number).This parameter provides HVES system level information. If there are multiple ...";
CM_ SG_ 2364607486 HvessThermalEventDetected "HVESS Thermal Event Detected: A sensor has detected the presence of a thermal event at or near High Voltage Energy Storage System  (or Pack 1 in systems with only one pack).00b = No Thermal Event Detected01b = Thermal Event Detected10b = Error11b = N...";
CM_ SG_ 2364607486 HvssDt9EmdddIntgrtSpprt "HVESS Data 9 Embedded Integrity Support: Indicates SPN 22973 (HVESS Data 9 CRC) and SPN 22972 (HVESS Data 9 Counter) are supported by the sender.00b = Embedded CRC and Counter are supported by the sender01b = Protection is provided using an external ...";
CM_ SG_ 2364607486 HvessData9Counter "HVESS Data 9 Counter: The message counter is used to detect situations where the transmitting ECU malfunction repeats the same frame all the time. The receiver of the information may use the counter parameter to detect this situation. The transmittin...";
CM_ SG_ 2364607486 HvessData9Crc "HVESS Data 9 CRC: The CRC is defined as follows: - Length: 8 bits- Polynomial: x^8+x^5+x^3+x^2+x+1- Initial Value: FFh- Input Data Reflection: Not reflected- Result Data Reflection: Not reflected- XOR value: FFh SAE makes no claim of the functional s...";
CM_ BO_ 2364607742 "High Voltage Energy Storage System Data 10";
CM_ SG_ 2364607742 HvssHghstCllSttOfChrgMdlNmr "HVESS Highest Cell State of Charge Module Number: Identifies the location of the module containing SPN 8085 (HVESS Highest Cell State of Charge).This parameter provides HVES system level information. If there are multiple packs in the system, then bo...";
CM_ SG_ 2364607742 HvssHghstCllSttOfChrgCllNmr "HVESS Highest Cell State of Charge Cell Number: Identifies the location of SPN 8085 (HVESS Highest Cell State of Charge) within SPN 8245 (HVESS Highest Cell State of Charge Module Number).This parameter provides HVES system level information. If ther...";
CM_ SG_ 2364607742 HvssLwstCllSttOfChrgMdlNmr "HVESS Lowest Cell State of Charge Module Number: Identifies the location of the module containing SPN 8084 (HVESS Lowest Cell State of Charge).This parameter provides HVES system level information. If there are multiple packs in the system, then both...";
CM_ SG_ 2364607742 HvssLwstCllSttOfChrgCllNmr "HVESS Lowest Cell State of Charge Cell Number: Identifies the location of SPN 8084 (HVESS Lowest Cell State of Charge) within SPN 8247 (HVESS Lowest Cell State of Charge Module Number).This parameter provides HVES system level information. If there a...";
CM_ SG_ 2364607742 HvssHghVltgBsAtvIsltnTstRslts "HVESS High-Voltage Bus Active Isolation Test Results: The isolation resistance expressed in Ohms per Volt that resulted from the High-Voltage Bus Active Isolation Test.See SPN 8096 (HVESS High-Voltage Bus Active Isolation Test Status) for test status...";
CM_ SG_ 2364607742 HvssHghVltgBsPssvIsltnTstRslts "HVESS High-Voltage Bus Passive Isolation Test Results: The isolation resistance expressed in Ohms per Volt that resulted from the High-Voltage Bus Passive Isolation Test.See SPN 8097 (HVESS High-Voltage Bus Passive Isolation Test Status) for test sta...";
CM_ BO_ 2364608510 "Engine Operating Information 2";
CM_ SG_ 2364608510 EnginePowerDerateRequest "Engine Power Derate Request: Derate request made from the engine control system to an external system, where the engine is requesting an external device to reduce the load being applied. A zero value indicates no derate, while any other value indicat...";
CM_ SG_ 2364608510 EngineSelfInducedDerateLoad "Engine Self-Induced Derate Load: The self-induced derate load that the Engine Control Module is trying to achieve.  A value of 0% means there is no active derate.";
CM_ SG_ 2364608510 PwrtrnPrttnIsDsldDTChsssNtDttd "Powertrain Protection is Disabled Due to Chassis Not Detected: Engine powertrain protection derate enablement status; based on if the engine is or is not installed in a chassis. This is intended to be used in a factory test cell mode or service dyno ...";
CM_ SG_ 2364608510 EngineCoolantFlow "Engine Coolant Flow: Used to detect the flow of engine coolant through an engine (usually from an engine coolant flow switch).00b = No Engine Coolant Flow01b = Engine Coolant is Flowing10b = Error11b = Not Available";
CM_ SG_ 2364608510 AttttTMtEvtdIdStts "Aftertreatment Thermal Management Elevated Idle Status: Indicates that the engine is elevating the idle speed due to aftertreatment thermal management strategies.00b = No Idle Elevation Active - standard idle speed01b = Idle Elevation Active10b = Res...";
CM_ BO_ 2364609278 "DC/DC Converter 1 Control";
CM_ SG_ 2364609278 DcDc1LowSideVoltageBuckSetpoint "DC/DC 1 Low Side Voltage Buck Setpoint: The set point for regulating the low side voltage during buck mode.";
CM_ SG_ 2364609278 DcDc1OperationalCommand "DC/DC 1 Operational Command: Command to enable or disable operation.0000b = Disable - in this mode all high voltage switching is disabled0001b = Standby - system is ready and waiting for command to enter buck, boost, shared buck or shared boost mode0...";
CM_ SG_ 2364609278 DcDc1ControlCounter "DC/DC 1 Control Counter: The message counter is used to detect situations where the transmitting ECU malfunction repeats the same frame all the time. The receiver of the information may use the counter parameter to detect this situation. The transmit...";
CM_ SG_ 2364609278 DcDc1ControlCrc "DC/DC 1 Control CRC: The CRC is defined as follows: - Length: 8 bits- Polynomial: x^8+x^5+x^3+x^2+x+1- Initial Value: FFh- Input Data Reflection: Not reflected- Result Data Reflection: Not reflected- XOR value: FFh SAE makes no claim of the functiona...";
CM_ SG_ 2364609278 DD1HghSdVltgBstStpnt "DC/DC 1 High Side Voltage Boost Setpoint: The set point for regulating the high side voltage during boost mode.";
CM_ SG_ 2364609278 DD1LwSdVltgBkDfltStpnt "DC/DC 1 Low Side Voltage Buck Default Setpoint: The set point for the converter default low side voltage during buck mode.   This setting may be used for when communication has been lost with the controlling device.  When set to Not Available (FFFFh)...";
CM_ BO_ 2364609534 "DC/DC Converter 1 Operating Status";
CM_ SG_ 2364609534 DcDc1HvilStatus "DC/DC 1 HVIL Status: High Voltage Interlock Loop (HVIL) state of the DC/DC Converter.00b = HVIL Closed01b = HVIL Open10b = Error11b = Not Available";
CM_ SG_ 2364609534 DcDc1LoadshedRequest "DC/DC 1 Loadshed Request: The loadshed request is a request to the controlling device to reduce the DC/DC Converter loads.  The Loadshed Requested state is an indication that this DC/DC Converter has a malfunction or is in a limit condition and if th...";
CM_ SG_ 2364609534 DcDc1OperationalStatus "DC/DC 1 Operational Status: Operating state of the DC/DC Converter0000b = Disabled - In this mode all high voltage switching is disabled0001b = Initialization - The device is powering up.  This process may include both internal checks, as well as sys...";
CM_ SG_ 2364609534 DcDc1OperatingStatusCounter "DC/DC 1 Operating Status Counter: The message counter is used to detect situations where the transmitting ECU malfunction repeats the same frame all the time. The receiver of the information may use the counter parameter to detect this situation. The...";
CM_ SG_ 2364609534 DcDc1OperatingStatusCrc "DC/DC 1 Operating Status CRC: The CRC is defined as follows: - Length: 8 bits- Polynomial: x^8+x^5+x^3+x^2+x+1- Initial Value: FFh- Input Data Reflection: Not reflected- Result Data Reflection: Not reflected- XOR value: FFh SAE makes no claim of the ...";
CM_ SG_ 2364609534 DD1PwrLmtDTHghSdCrrnt "DC/DC 1 Power Limit due to High Side Current: Indicates whether or not output power is being limited due to high side current (see SPN 8588) approaching or exceeding the maximum limit (see SPN 8565).00b = No power limit for this reason01b = Power lim...";
CM_ SG_ 2364609534 DD1PwrLmtDTLwSdCrrnt "DC/DC 1 Power Limit due to Low Side Current: Indicates whether or not output power is being limited due to low side current (see SPN 8586) approaching or exceeding the maximum limit (see SPN 8568).00b = No power limit for this reason01b = Power limit...";
CM_ SG_ 2364609534 DD1PwrLmtDTHghSdVltgMnmm "DC/DC 1 Power Limit due to High Side Voltage Minimum: Indicates whether or not output power is being limited due to high side voltage (see SPN 8587) approaching or falling below the minimum limit (see SPN 8563).00b = No power limit for this reason01b...";
CM_ SG_ 2364609534 DD1PwrLmtDTHghSdVltgMxmm "DC/DC 1 Power Limit due to High Side Voltage Maximum: Indicates whether or not output power is being limited due to high side voltage (see SPN 8587) approaching or exceeding the maximum limit (see SPN 8564).00b = No power limit for this reason01b = P...";
CM_ SG_ 2364609534 DD1PwrLmtDTLwSdVltgMnmm "DC/DC 1 Power Limit due to Low Side Voltage Minimum: Indicates whether or not output power is being limited due to low side voltage (see SPN 8585) approaching or falling below the minimum limit (see SPN 8566).00b = No power limit for this reason01b =...";
CM_ SG_ 2364609534 DD1PwrLmtDTLwSdVltgMxmm "DC/DC 1 Power Limit due to Low Side Voltage Maximum: Indicates whether or not output power is being limited due to low side voltage (see SPN 8585) approaching or exceeding the maximum limit (see SPN 8567).00b = No power limit for this reason01b = Pow...";
CM_ SG_ 2364609534 DD1PwrLmtDTCnvrtrTmprtr "DC/DC 1 Power Limit due to Converter Temperature: Indicates whether or not output power is being limited due to Converter Temperature (see SPN 8592) approaching or exceeding the maximum limit.00b = No power limit for this reason01b = Power limited fo...";
CM_ SG_ 2364609534 DD1PwrLmtDTEltrnFltrTmprtr "DC/DC 1 Power Limit due to Electronic Filter Temperature: Indicates whether or not output power is being limited due to Output Electronic Filter Temperature (see SPN 8693) approaching or exceeding the maximum limit.00b = No power limit for this reaso...";
CM_ SG_ 2364609534 DD1PwrLmtDTPwrEltrnsTmprtr "DC/DC 1 Power Limit due to Power Electronics Temperature: Indicates whether or not output power is being limited due to Power Electronics Temperature (see SPN 8594) approaching or exceeding the maximum limit.00b = No power limit for this reason01b = ...";
CM_ SG_ 2364609534 DD1PwrLmtDTSlBttrTrmnlVltg "DC/DC 1 Power Limit due to SLI Battery Terminal Voltage: Indicates whether or not output power is being limited due to the SLI battery terminal voltage (see SPN 8589) approaching or exceeding limits (see SPN 8817).00b = No power limit for this reason...";
CM_ SG_ 2364609534 DD1PwrLmtDTSlBttrTrmnlCrrnt "DC/DC 1 Power Limit due to SLI Battery Terminal Current: Indicates whether or not output power is being limited due to the SLI battery terminal current (see SPN 8590) approaching or exceeding limits (see SPN 8818).00b = No power limit for this reason...";
CM_ SG_ 2364609534 DD1PwrLmtDTSlBttrTrmnlTmprtr "DC/DC 1 Power Limit due to SLI Battery Terminal Temperature: Indicates whether or not output power is being limited due to the SLI battery terminal temperature (see SPN 8591) approaching or exceeding limits (see SPN 8819).00b = No power limit for thi...";
CM_ SG_ 2364609534 DD1PwrLmtDTUndfndRsn "DC/DC 1 Power Limit due to Undefined Reason: Indicates whether or not output power is being limited due to an undefined reason.00b = No power limit for this reason01b = Power limited for this reason10b = Error11b = Not Available";
CM_ BO_ 2364609790 "DC/DC Converter 1 Voltage and Current";
CM_ SG_ 2364609790 DcDc1HighSideCurrent "DC/DC 1 High Side Current: Indicates the measured HVES or high side current measured at the point of control inside the DC/DC Converter.  The current is negative if the converter is charging the SLI battery from the hybrid or EV battery.";
CM_ SG_ 2364609790 DcDc1HighSideVoltage "DC/DC 1 High Side Voltage: Indicates the measured HVES or high side voltage measured at the point of control inside the DC/DC Converter.";
CM_ SG_ 2364609790 DcDc1LowSideCurrent "DC/DC 1 Low Side Current: Indicates the measured SLI battery or low side current measured at the point of control inside the DC/DC Converter.  The current is positive if the converter is charging the SLI battery from the hybrid or EV battery.";
CM_ SG_ 2364609790 DcDc1LowSideVoltage "DC/DC 1 Low Side Voltage: Indicates the measured SLI battery or low side voltage measured at the point of control inside the DC/DC Converter.";
CM_ BO_ 2364610046 "DC/DC Converter 1 SLI Battery Status";
CM_ SG_ 2364610046 DcDc1SliBatteryTerminalCurrent "DC/DC 1 SLI Battery Terminal Current: Parameter indicating the SLI battery terminal current for control use by the DC/DC converter.  The current is positive if the SLI battery or low side voltage source is being charged from the HVES.";
CM_ SG_ 2364610046 DcDc1SliBatteryTerminalVoltage "DC/DC 1 SLI Battery Terminal Voltage: Parameter indicating the SLI battery terminal voltage for control use by the DC/DC converter.";
CM_ SG_ 2364610046 DD1SlBttrTrmnlTmprtr "DC/DC 1 SLI Battery Terminal Temperature: Parameter indicating the SLI battery terminal temperature for control use by the DC/DC converter.";
CM_ BO_ 2364610558 "DC/DC Converter 1 Status 2";
CM_ SG_ 2364610558 DcDc1HighSidePower "DC/DC 1 High Side Power: Indicates the measured HVES or high side power measured at the DC/DC Converter.  The high side power is positive if the converter is charging the hybrid battery from the SLI battery (i.e. Boost Mode).  The high side power is ...";
CM_ SG_ 2364610558 DcDc1LowSidePower "DC/DC 1 Low Side Power: Indicates the measured SLI battery or low side power measured at the DC/DC Converter.  The low side power is positive if the converter is charging the SLI battery from the hybrid battery (i.e. Buck Mode).  The low side power i...";
CM_ SG_ 2364610558 DD1HghSdNgtvTChsssGrndVltg "DC/DC 1 High Side Negative to Chassis Ground Voltage: The voltage level of the high voltage DC side, as measured by the DC/DC between the negative side of the High Voltage DC Side input and the chassis of the DC/DC enclosure.  This voltage can be use...";
CM_ BO_ 2364610814 "DC/DC Converter 2 Control";
CM_ SG_ 2364610814 DcDc2LowSideVoltageBuckSetpoint "DC/DC 2 Low Side Voltage Buck Setpoint: The set point for regulating the low side voltage during buck mode.";
CM_ SG_ 2364610814 DcDc2OperationalCommand "DC/DC 2 Operational Command: Command to enable or disable operation.0000b = Disable - in this mode all high voltage switching is disabled0001b = Standby - system is ready and waiting for command to enter buck, boost, shared buck or shared boost mode0...";
CM_ SG_ 2364610814 DcDc2ControlCounter "DC/DC 2 Control Counter: The message counter is used to detect situations where the transmitting ECU malfunction repeats the same frame all the time. The receiver of the information may use the counter parameter to detect this situation. The transmit...";
CM_ SG_ 2364610814 DcDc2ControlCrc "DC/DC 2 Control CRC: The CRC is defined as follows: - Length: 8 bits- Polynomial: x^8+x^5+x^3+x^2+x+1- Initial Value: FFh- Input Data Reflection: Not reflected- Result Data Reflection: Not reflected- XOR value: FFh SAE makes no claim of the functiona...";
CM_ SG_ 2364610814 DD2HghSdVltgBstStpnt "DC/DC 2 High Side Voltage Boost Setpoint: The set point for regulating the high side voltage during boost mode.";
CM_ SG_ 2364610814 DD2LwSdVltgBkDfltStpnt "DC/DC 2 Low Side Voltage Buck Default Setpoint: The set point for the converter default low side voltage during buck mode.   This setting may be used for when communication has been lost with the controlling device.  When set to Not Available (FFFFh)...";
CM_ BO_ 2364611070 "DC/DC Converter 2 Operating Status";
CM_ SG_ 2364611070 DcDc2HvilStatus "DC/DC 2 HVIL Status: High Voltage Interlock Loop (HVIL) state of the DC/DC Converter.00b = HVIL Closed01b = HVIL Open10b = Error11b = Not Available";
CM_ SG_ 2364611070 DcDc2LoadshedRequest "DC/DC 2 Loadshed Request: The loadshed request is a request to the controlling device to reduce the DC/DC Converter loads.  The Loadshed Requested state is an indication that this DC/DC Converter has a malfunction or is in a limit condition and if th...";
CM_ SG_ 2364611070 DcDc2OperationalStatus "DC/DC 2 Operational Status: Operating state of the DC/DC Converter0000b = Disabled - In this mode all high voltage switching is disabled0001b = Initialization - The device is powering up.  This process may include both internal checks, as well as sys...";
CM_ SG_ 2364611070 DcDc2OperatingStatusCounter "DC/DC 2 Operating Status Counter: The message counter is used to detect situations where the transmitting ECU malfunction repeats the same frame all the time. The receiver of the information may use the counter parameter to detect this situation. The...";
CM_ SG_ 2364611070 DcDc2OperatingStatusCrc "DC/DC 2 Operating Status CRC: The CRC is defined as follows: - Length: 8 bits- Polynomial: x^8+x^5+x^3+x^2+x+1- Initial Value: FFh- Input Data Reflection: Not reflected- Result Data Reflection: Not reflected- XOR value: FFh SAE makes no claim of the ...";
CM_ SG_ 2364611070 DD2PwrLmtDTHghSdCrrnt "DC/DC 2 Power Limit due to High Side Current: Indicates whether or not output power is being limited due to high side current (see SPN 8914) approaching or exceeding the maximum limit (see SPN 8946).00b = No power limit for this reason01b = Power lim...";
CM_ SG_ 2364611070 DD2PwrLmtDTLwSdCrrnt "DC/DC 2 Power Limit due to Low Side Current: Indicates whether or not output power is being limited due to low side current (see SPN 8912) approaching or exceeding the maximum limit (see SPN 8943).00b = No power limit for this reason01b = Power limit...";
CM_ SG_ 2364611070 DD2PwrLmtDTHghSdVltgMnmm "DC/DC 2 Power Limit due to High Side Voltage Minimum: Indicates whether or not output power is being limited due to high side voltage (see SPN 8913) approaching or falling below the minimum limit (see SPN 8944).00b = No power limit for this reason01b...";
CM_ SG_ 2364611070 DD2PwrLmtDTHghSdVltgMxmm "DC/DC 2 Power Limit due to High Side Voltage Maximum: Indicates whether or not output power is being limited due to high side voltage (see SPN 8913) approaching or exceeding the maximum limit (see SPN 8945).00b = No power limit for this reason01b = P...";
CM_ SG_ 2364611070 DD2PwrLmtDTLwSdVltgMnmm "DC/DC 2 Power Limit due to Low Side Voltage Minimum: Indicates whether or not output power is being limited due to low side voltage (see SPN 8911) approaching or falling below the minimum limit (see SPN 8941).00b = No power limit for this reason01b =...";
CM_ SG_ 2364611070 DD2PwrLmtDTLwSdVltgMxmm "DC/DC 2 Power Limit due to Low Side Voltage Maximum: Indicates whether or not output power is being limited due to low side voltage (see SPN 8911) approaching or exceeding the maximum limit (see SPN 8942).00b = No power limit for this reason01b = Pow...";
CM_ SG_ 2364611070 DD2PwrLmtDTCnvrtrTmprtr "DC/DC 2 Power Limit due to Converter Temperature: Indicates whether or not output power is being limited due to Converter Temperature (see SPN 8936) approaching or exceeding the maximum limit.00b = No power limit for this reason01b = Power limited fo...";
CM_ SG_ 2364611070 DD2PwrLmtDTEltrnFltrTmprtr "DC/DC 2 Power Limit due to Electronic Filter Temperature: Indicates whether or not output power is being limited due to Output Electronic Filter Temperature (see SPN 8937) approaching or exceeding the maximum limit.00b = No power limit for this reaso...";
CM_ SG_ 2364611070 DD2PwrLmtDTPwrEltrnsTmprtr "DC/DC 2 Power Limit due to Power Electronics Temperature: Indicates whether or not output power is being limited due to Power Electronics Temperature (see SPN 8938) approaching or exceeding the maximum limit.00b = No power limit for this reason01b = ...";
CM_ SG_ 2364611070 DD2PwrLmtDTSlBttrTrmnlVltg "DC/DC 2 Power Limit due to SLI Battery Terminal Voltage: Indicates whether or not output power is being limited due to the SLI battery terminal voltage (see SPN 8915) approaching or exceeding limits (see SPN 8933).00b = No power limit for this reason...";
CM_ SG_ 2364611070 DD2PwrLmtDTSlBttrTrmnlCrrnt "DC/DC 2 Power Limit due to SLI Battery Terminal Current: Indicates whether or not output power is being limited due to the SLI battery terminal current (see SPN 8916) approaching or exceeding limits (see SPN 8934).00b = No power limit for this reason...";
CM_ SG_ 2364611070 DD2PwrLmtDTSlBttrTrmnlTmprtr "DC/DC 2 Power Limit due to SLI Battery Terminal Temperature: Indicates whether or not output power is being limited due to the SLI battery terminal temperature (see SPN 8917) approaching or exceeding limits (see SPN 8935).00b = No power limit for thi...";
CM_ SG_ 2364611070 DD2PwrLmtDTUndfndRsn "DC/DC 2 Power Limit due to Undefined Reason: Indicates whether or not output power is being limited due to an undefined reason.00b = No power limit for this reason01b = Power limited for this reason10b = Error11b = Not Available";
CM_ BO_ 2364611326 "DC/DC Converter 2 Voltage and Current";
CM_ SG_ 2364611326 DcDc2HighSideCurrent "DC/DC 2 High Side Current: Indicates the measured HVES or high side current measured at the point of control inside the DC/DC Converter.  The current is negative if the converter is charging the SLI battery from the hybrid or EV battery.";
CM_ SG_ 2364611326 DcDc2HighSideVoltage "DC/DC 2 High Side Voltage: Indicates the measured HVES or high side voltage measured at the point of control inside the DC/DC Converter.";
CM_ SG_ 2364611326 DcDc2LowSideCurrent "DC/DC 2 Low Side Current: Indicates the measured SLI battery or low side current measured at the point of control inside the DC/DC Converter.  The current is positive if the converter is charging the SLI battery from the hybrid or EV battery.";
CM_ SG_ 2364611326 DcDc2LowSideVoltage "DC/DC 2 Low Side Voltage: Indicates the measured SLI battery or low side voltage measured at the point of control inside the DC/DC Converter.";
CM_ BO_ 2364611582 "DC/DC Converter 2 SLI Battery Status";
CM_ SG_ 2364611582 DcDc2SliBatteryTerminalCurrent "DC/DC 2 SLI Battery Terminal Current: Parameter indicating the SLI battery terminal current for control use by the DC/DC converter.  The current is positive if the SLI battery or low side voltage source is being charged from the HVES.";
CM_ SG_ 2364611582 DcDc2SliBatteryTerminalVoltage "DC/DC 2 SLI Battery Terminal Voltage: Parameter indicating the SLI battery terminal voltage for control use by the DC/DC converter.";
CM_ SG_ 2364611582 DD2SlBttrTrmnlTmprtr "DC/DC 2 SLI Battery Terminal Temperature: Parameter indicating the SLI battery terminal temperature for control use by the DC/DC converter.";
CM_ BO_ 2364611838 "DC/DC Converter 2 Status 2";
CM_ SG_ 2364611838 DcDc2HighSidePower "DC/DC 2 High Side Power: Indicates the measured HVES or high side power measured at the DC/DC Converter.  The high side power is positive if the converter is charging the hybrid or EV battery from the SLI battery (i.e. Boost Mode).  The high side pow...";
CM_ SG_ 2364611838 DcDc2LowSidePower "DC/DC 2 Low Side Power: Indicates the measured SLI battery or low side power measured at the DC/DC Converter.  The low side power is positive if the converter is charging the SLI battery from the hybrid or EV battery (i.e. Buck Mode).  The low side p...";
CM_ SG_ 2364611838 DD2HghSdNgtvTChsssGrndVltg "DC/DC 2 High Side Negative to Chassis Ground Voltage: The voltage level of the high voltage DC side, as measured by the DC/DC between the negative side of the High Voltage DC Side input and the chassis of the DC/DC enclosure.  This voltage can be use...";
CM_ BO_ 2364612094 "DC/DC Converter 3 Control";
CM_ SG_ 2364612094 DcDc3LowSideVoltageBuckSetpoint "DC/DC 3 Low Side Voltage Buck Setpoint: The set point for regulating the low side voltage during buck mode.";
CM_ SG_ 2364612094 DcDc3OperationalCommand "DC/DC 3 Operational Command: Command to enable or disable operation.0000b = Disable - in this mode all high voltage switching is disabled0001b = Standby - system is ready and waiting for command to enter buck, boost, shared buck or shared boost mode0...";
CM_ SG_ 2364612094 DcDc3ControlCounter "DC/DC 3 Control Counter: The message counter is used to detect situations where the transmitting ECU malfunction repeats the same frame all the time. The receiver of the information may use the counter parameter to detect this situation. The transmit...";
CM_ SG_ 2364612094 DcDc3ControlCrc "DC/DC 3 Control CRC: The CRC is defined as follows: - Length: 8 bits- Polynomial: x^8+x^5+x^3+x^2+x+1- Initial Value: FFh- Input Data Reflection: Not reflected- Result Data Reflection: Not reflected- XOR value: FFh SAE makes no claim of the functiona...";
CM_ SG_ 2364612094 DD3HghSdVltgBstStpnt "DC/DC 3 High Side Voltage Boost Setpoint: The set point for regulating the high side voltage during boost mode.";
CM_ SG_ 2364612094 DD3LwSdVltgBkDfltStpnt "DC/DC 3 Low Side Voltage Buck Default Setpoint: The set point for the converter default low side voltage during buck mode.   This setting may be used for when communication has been lost with the controlling device.  When set to Not Available (FFFFh)...";
CM_ BO_ 2364612350 "DC/DC Converter 3 Operating Status";
CM_ SG_ 2364612350 DcDc3HvilStatus "DC/DC 3 HVIL Status: High Voltage Interlock Loop (HVIL) state of the DC/DC Converter.00b = HVIL Closed01b = HVIL Open10b = Error11b = Not Available";
CM_ SG_ 2364612350 DcDc3LoadshedRequest "DC/DC 3 Loadshed Request: The loadshed request is a request to the controlling device to reduce the DC/DC Converter loads.  The Loadshed Requested state is an indication that this DC/DC Converter has a malfunction or is in a limit condition and if th...";
CM_ SG_ 2364612350 DcDc3OperationalStatus "DC/DC 3 Operational Status: Operating state of the DC/DC Converter0000b = Disabled - In this mode all high voltage switching is disabled0001b = Initialization - The device is powering up.  This process may include both internal checks, as well as sys...";
CM_ SG_ 2364612350 DcDc3OperatingStatusCounter "DC/DC 3 Operating Status Counter: The message counter is used to detect situations where the transmitting ECU malfunction repeats the same frame all the time. The receiver of the information may use the counter parameter to detect this situation. The...";
CM_ SG_ 2364612350 DcDc3OperatingStatusCrc "DC/DC 3 Operating Status CRC: The CRC is defined as follows: - Length: 8 bits- Polynomial: x^8+x^5+x^3+x^2+x+1- Initial Value: FFh- Input Data Reflection: Not reflected- Result Data Reflection: Not reflected- XOR value: FFh SAE makes no claim of the ...";
CM_ SG_ 2364612350 DD3PwrLmtDTHghSdCrrnt "DC/DC 3 Power Limit due to High Side Current: Indicates whether or not output power is being limited due to high side current (see SPN 8969) approaching or exceeding the maximum limit (see SPN 9001).00b = No power limit for this reason01b = Power lim...";
CM_ SG_ 2364612350 DD3PwrLmtDTLwSdCrrnt "DC/DC 3 Power Limit due to Low Side Current: Indicates whether or not output power is being limited due to low side current (see SPN 8967) approaching or exceeding the maximum limit (see SPN 8998).00b = No power limit for this reason01b = Power limit...";
CM_ SG_ 2364612350 DD3PwrLmtDTHghSdVltgMnmm "DC/DC 3 Power Limit due to High Side Voltage Minimum: Indicates whether or not output power is being limited due to high side voltage (see SPN 8968) approaching or falling below the minimum limit (see SPN 8999).00b = No power limit for this reason01b...";
CM_ SG_ 2364612350 DD3PwrLmtDTHghSdVltgMxmm "DC/DC 3 Power Limit due to High Side Voltage Maximum: Indicates whether or not output power is being limited due to high side voltage (see SPN 8968) approaching or exceeding the maximum limit (see SPN 9000).00b = No power limit for this reason01b = P...";
CM_ SG_ 2364612350 DD3PwrLmtDTLwSdVltgMnmm "DC/DC 3 Power Limit due to Low Side Voltage Minimum: Indicates whether or not output power is being limited due to low side voltage (see SPN 8966) approaching or falling below the minimum limit (see SPN 8996).00b = No power limit for this reason01b =...";
CM_ SG_ 2364612350 DD3PwrLmtDTLwSdVltgMxmm "DC/DC 3 Power Limit due to Low Side Voltage Maximum: Indicates whether or not output power is being limited due to low side voltage (see SPN 8966) approaching or exceeding the maximum limit (see SPN 8997).00b = No power limit for this reason01b = Pow...";
CM_ SG_ 2364612350 DD3PwrLmtDTCnvrtrTmprtr "DC/DC 3 Power Limit due to Converter Temperature: Indicates whether or not output power is being limited due to Converter Temperature (see SPN 8991) approaching or exceeding the maximum limit.00b = No power limit for this reason01b = Power limited fo...";
CM_ SG_ 2364612350 DD3PwrLmtDTEltrnFltrTmprtr "DC/DC 3 Power Limit due to Electronic Filter Temperature: Indicates whether or not output power is being limited due to Output Electronic Filter Temperature (see SPN 8992) approaching or exceeding the maximum limit.00b = No power limit for this reaso...";
CM_ SG_ 2364612350 DD3PwrLmtDTPwrEltrnsTmprtr "DC/DC 3 Power Limit due to Power Electronics Temperature: Indicates whether or not output power is being limited due to Power Electronics Temperature (see SPN 8993) approaching or exceeding the maximum limit.00b = No power limit for this reason01b = ...";
CM_ SG_ 2364612350 DD3PwrLmtDTSlBttrTrmnlVltg "DC/DC 3 Power Limit due to SLI Battery Terminal Voltage: Indicates whether or not output power is being limited due to the SLI battery terminal voltage (see SPN 8970) approaching or exceeding limits (see SPN 8988).00b = No power limit for this reason...";
CM_ SG_ 2364612350 DD3PwrLmtDTSlBttrTrmnlCrrnt "DC/DC 3 Power Limit due to SLI Battery Terminal Current: Indicates whether or not output power is being limited due to the SLI battery terminal current (see SPN 8971) approaching or exceeding limits (see SPN 8989).00b = No power limit for this reason...";
CM_ SG_ 2364612350 DD3PwrLmtDTSlBttrTrmnlTmprtr "DC/DC 3 Power Limit due to SLI Battery Terminal Temperature: Indicates whether or not output power is being limited due to the SLI battery terminal temperature (see SPN 8972) approaching or exceeding limits (see SPN 8990).00b = No power limit for thi...";
CM_ SG_ 2364612350 DD3PwrLmtDTUndfndRsn "DC/DC 3 Power Limit due to Undefined Reason: Indicates whether or not output power is being limited due to an undefined reason.00b = No power limit for this reason01b = Power limited for this reason10b = Error11b = Not Available";
CM_ BO_ 2364612606 "DC/DC Converter 3 Voltage and Current";
CM_ SG_ 2364612606 DcDc3HighSideCurrent "DC/DC 3 High Side Current: Indicates the measured HVES or high side current measured at the point of control inside the DC/DC Converter.  The current is negative if the converter is charging the SLI battery from the hybrid or EV battery.";
CM_ SG_ 2364612606 DcDc3HighSideVoltage "DC/DC 3 High Side Voltage: Indicates the measured HVES or high side voltage measured at the point of control inside the DC/DC Converter.";
CM_ SG_ 2364612606 DcDc3LowSideCurrent "DC/DC 3 Low Side Current: Indicates the measured SLI battery or low side current measured at the point of control inside the DC/DC Converter.  The current is positive if the converter is charging the SLI battery from the hybrid or EV battery.";
CM_ SG_ 2364612606 DcDc3LowSideVoltage "DC/DC 3 Low Side Voltage: Indicates the measured SLI battery or low side voltage measured at the point of control inside the DC/DC Converter.";
CM_ BO_ 2364612862 "DC/DC Converter 3 SLI Battery Status";
CM_ SG_ 2364612862 DcDc3SliBatteryTerminalCurrent "DC/DC 3 SLI Battery Terminal Current: Parameter indicating the SLI battery terminal current for control use by the DC/DC converter.  The current is positive if the SLI battery or low side voltage source is being charged from the HVES.";
CM_ SG_ 2364612862 DcDc3SliBatteryTerminalVoltage "DC/DC 3 SLI Battery Terminal Voltage: Parameter indicating the SLI battery terminal voltage for control use by the DC/DC converter.";
CM_ SG_ 2364612862 DD3SlBttrTrmnlTmprtr "DC/DC 3 SLI Battery Terminal Temperature: Parameter indicating the SLI battery terminal temperature for control use by the DC/DC converter.";
CM_ BO_ 2364613118 "DC/DC Converter 3 Status 2";
CM_ SG_ 2364613118 DcDc3HighSidePower "DC/DC 3 High Side Power: Indicates the measured HVES or high side power measured at the DC/DC Converter.  The high side power is positive if the converter is charging the hybrid or EV battery from the SLI battery (i.e. Boost Mode).  The high side pow...";
CM_ SG_ 2364613118 DcDc3LowSidePower "DC/DC 3 Low Side Power: Indicates the measured SLI battery or low side power measured at the DC/DC Converter.  The low side power is positive if the converter is charging the SLI battery from the hybrid or EV battery (i.e. Buck Mode).  The low side p...";
CM_ SG_ 2364613118 DD3HghSdNgtvTChsssGrndVltg "DC/DC 3 High Side Negative to Chassis Ground Voltage: The voltage level of the high voltage DC side, as measured by the DC/DC between the negative side of the High Voltage DC Side input and the chassis of the DC/DC enclosure.  This voltage can be use...";
CM_ BO_ 2364613374 "DC/DC Converter 4 Control";
CM_ SG_ 2364613374 DcDc4LowSideVoltageBuckSetpoint "DC/DC 4 Low Side Voltage Buck Setpoint: The set point for regulating the low side voltage during buck mode.";
CM_ SG_ 2364613374 DcDc4OperationalCommand "DC/DC 4 Operational Command: Command to enable or disable operation.0000b = Disable - in this mode all high voltage switching is disabled0001b = Standby - system is ready and waiting for command to enter buck, boost, shared buck or shared boost mode0...";
CM_ SG_ 2364613374 DcDc4ControlCounter "DC/DC 4 Control Counter: The message counter is used to detect situations where the transmitting ECU malfunction repeats the same frame all the time. The receiver of the information may use the counter parameter to detect this situation. The transmit...";
CM_ SG_ 2364613374 DcDc4ControlCrc "DC/DC 4 Control CRC: The CRC is defined as follows: - Length: 8 bits- Polynomial: x^8+x^5+x^3+x^2+x+1- Initial Value: FFh- Input Data Reflection: Not reflected- Result Data Reflection: Not reflected- XOR value: FFh SAE makes no claim of the functiona...";
CM_ SG_ 2364613374 DD4HghSdVltgBstStpnt "DC/DC 4 High Side Voltage Boost Setpoint: The set point for regulating the high side voltage during boost mode.";
CM_ SG_ 2364613374 DD4LwSdVltgBkDfltStpnt "DC/DC 4 Low Side Voltage Buck Default Setpoint: The set point for the converter default low side voltage during buck mode.   This setting may be used for when communication has been lost with the controlling device.  When set to Not Available (FFFFh)...";
CM_ BO_ 2364613630 "DC/DC Converter 4 Operating Status";
CM_ SG_ 2364613630 DcDc4HvilStatus "DC/DC 4 HVIL Status: High Voltage Interlock Loop (HVIL) state of the DC/DC Converter.00b = HVIL Closed01b = HVIL Open10b = Error11b = Not Available";
CM_ SG_ 2364613630 DcDc4LoadshedRequest "DC/DC 4 Loadshed Request: The loadshed request is a request to the controlling device to reduce the DC/DC Converter loads.  The Loadshed Requested state is an indication that this DC/DC Converter has a malfunction or is in a limit condition and if th...";
CM_ SG_ 2364613630 DcDc4OperationalStatus "DC/DC 4 Operational Status: Operating state of the DC/DC Converter0000b = Disabled - In this mode all high voltage switching is disabled0001b = Initialization - The device is powering up.  This process may include both internal checks, as well as sys...";
CM_ SG_ 2364613630 DcDc4OperatingStatusCounter "DC/DC 4 Operating Status Counter: The message counter is used to detect situations where the transmitting ECU malfunction repeats the same frame all the time. The receiver of the information may use the counter parameter to detect this situation. The...";
CM_ SG_ 2364613630 DcDc4OperatingStatusCrc "DC/DC 4 Operating Status CRC: The CRC is defined as follows: - Length: 8 bits- Polynomial: x^8+x^5+x^3+x^2+x+1- Initial Value: FFh- Input Data Reflection: Not reflected- Result Data Reflection: Not reflected- XOR value: FFh SAE makes no claim of the ...";
CM_ SG_ 2364613630 DD4PwrLmtDTHghSdCrrnt "DC/DC 4 Power Limit due to High Side Current: Indicates whether or not output power is being limited due to high side current (see SPN 9024) approaching or exceeding the maximum limit (see SPN 9056).00b = No power limit for this reason01b = Power lim...";
CM_ SG_ 2364613630 DD4PwrLmtDTLwSdCrrnt "DC/DC 4 Power Limit due to Low Side Current: Indicates whether or not output power is being limited due to low side current (see SPN 9022) approaching or exceeding the maximum limit (see SPN 9053).00b = No power limit for this reason01b = Power limit...";
CM_ SG_ 2364613630 DD4PwrLmtDTHghSdVltgMnmm "DC/DC 4 Power Limit due to High Side Voltage Minimum: Indicates whether or not output power is being limited due to high side voltage (see SPN 9023) approaching or falling below the minimum limit (see SPN 9054).00b = No power limit for this reason01b...";
CM_ SG_ 2364613630 DD4PwrLmtDTHghSdVltgMxmm "DC/DC 4 Power Limit due to High Side Voltage Maximum: Indicates whether or not output power is being limited due to high side voltage (see SPN 9023) approaching or exceeding the maximum limit (see SPN 9055).00b = No power limit for this reason01b = P...";
CM_ SG_ 2364613630 DD4PwrLmtDTLwSdVltgMnmm "DC/DC 4 Power Limit due to Low Side Voltage Minimum: Indicates whether or not output power is being limited due to low side voltage (see SPN 9021) approaching or falling below the minimum limit (see SPN 9051).00b = No power limit for this reason01b =...";
CM_ SG_ 2364613630 DD4PwrLmtDTLwSdVltgMxmm "DC/DC 4 Power Limit due to Low Side Voltage Maximum: Indicates whether or not output power is being limited due to low side voltage (see SPN 9021) approaching or exceeding the maximum limit (see SPN 9052).00b = No power limit for this reason01b = Pow...";
CM_ SG_ 2364613630 DD4PwrLmtDTCnvrtrTmprtr "DC/DC 4 Power Limit due to Converter Temperature: Indicates whether or not output power is being limited due to Converter Temperature (see SPN 9046) approaching or exceeding the maximum limit.00b = No power limit for this reason01b = Power limited fo...";
CM_ SG_ 2364613630 DD4PwrLmtDTEltrnFltrTmprtr "DC/DC 4 Power Limit due to Electronic Filter Temperature: Indicates whether or not output power is being limited due to Output Electronic Filter Temperature (see SPN 9047) approaching or exceeding the maximum limit.00b = No power limit for this reaso...";
CM_ SG_ 2364613630 DD4PwrLmtDTPwrEltrnsTmprtr "DC/DC 4 Power Limit due to Power Electronics Temperature: Indicates whether or not output power is being limited due to Power Electronics Temperature (see SPN 9048) approaching or exceeding the maximum limit.00b = No power limit for this reason01b = ...";
CM_ SG_ 2364613630 DD4PwrLmtDTSlBttrTrmnlVltg "DC/DC 4 Power Limit due to SLI Battery Terminal Voltage: Indicates whether or not output power is being limited due to the SLI battery terminal voltage (see SPN 9025) approaching or exceeding limits (see SPN 9043).00b = No power limit for this reason...";
CM_ SG_ 2364613630 DD4PwrLmtDTSlBttrTrmnlCrrnt "DC/DC 4 Power Limit due to SLI Battery Terminal Current: Indicates whether or not output power is being limited due to the SLI battery terminal current (see SPN 9026) approaching or exceeding limits (see SPN 9044).00b = No power limit for this reason...";
CM_ SG_ 2364613630 DD4PwrLmtDTSlBttrTrmnlTmprtr "DC/DC 4 Power Limit due to SLI Battery Terminal Temperature: Indicates whether or not output power is being limited due to the SLI battery terminal temperature (see SPN 9027) approaching or exceeding limits (see SPN 9045).00b = No power limit for thi...";
CM_ SG_ 2364613630 DD4PwrLmtDTUndfndRsn "DC/DC 4 Power Limit due to Undefined Reason: Indicates whether or not output power is being limited due to an undefined reason.00b = No power limit for this reason01b = Power limited for this reason10b = Error11b = Not Available";
CM_ BO_ 2364613886 "DC/DC Converter 4 Voltage and Current";
CM_ SG_ 2364613886 DcDc4HighSideCurrent "DC/DC 4 High Side Current: Indicates the measured HVES or high side current measured at the point of control inside the DC/DC Converter.  The current is negative if the converter is charging the SLI battery from the hybrid or EV battery.";
CM_ SG_ 2364613886 DcDc4HighSideVoltage "DC/DC 4 High Side Voltage: Indicates the measured HVES or high side voltage measured at the point of control inside the DC/DC Converter.";
CM_ SG_ 2364613886 DcDc4LowSideCurrent "DC/DC 4 Low Side Current: Indicates the measured SLI battery or low side current measured at the point of control inside the DC/DC Converter.  The current is positive if the converter is charging the SLI battery from the hybrid or EV battery.";
CM_ SG_ 2364613886 DcDc4LowSideVoltage "DC/DC 4 Low Side Voltage: Indicates the measured SLI battery or low side voltage measured at the point of control inside the DC/DC Converter.";
CM_ BO_ 2364614142 "DC/DC Converter 4 SLI Battery Status";
CM_ SG_ 2364614142 DcDc4SliBatteryTerminalCurrent "DC/DC 4 SLI Battery Terminal Current: Parameter indicating the SLI battery terminal current for control use by the DC/DC converter.  The current is positive if the SLI battery or low side voltage source is being charged from the HVES.";
CM_ SG_ 2364614142 DcDc4SliBatteryTerminalVoltage "DC/DC 4 SLI Battery Terminal Voltage: Parameter indicating the SLI battery terminal voltage for control use by the DC/DC converter.";
CM_ SG_ 2364614142 DD4SlBttrTrmnlTmprtr "DC/DC 4 SLI Battery Terminal Temperature: Parameter indicating the SLI battery terminal temperature for control use by the DC/DC converter.";
CM_ BO_ 2364614398 "DC/DC Converter 4 Status 2";
CM_ SG_ 2364614398 DcDc4HighSidePower "DC/DC 4 High Side Power: Indicates the measured HVES or high side power measured at the DC/DC Converter.  The high side power is positive if the converter is charging the hybrid or EV battery from the SLI battery (i.e. Boost Mode).  The high side pow...";
CM_ SG_ 2364614398 DcDc4LowSidePower "DC/DC 4 Low Side Power: Indicates the measured SLI battery or low side power measured at the DC/DC Converter.  The low side power is positive if the converter is charging the SLI battery from the hybrid or EV battery (i.e. Buck Mode).  The low side p...";
CM_ SG_ 2364614398 DD4HghSdNgtvTChsssGrndVltg "DC/DC 4 High Side Negative to Chassis Ground Voltage: The voltage level of the high voltage DC side, as measured by the DC/DC between the negative side of the High Voltage DC Side input and the chassis of the DC/DC enclosure.  This voltage can be use...";
CM_ BO_ 2364614654 "Slope Sensor Information 3";
CM_ SG_ 2364614654 GradeThresholdIndicator1 "Grade Threshold Indicator 1: This parameter indicates whether or not the transmitting device has sensed a vehicle grade equal to or exceeding a manufacturer-defined threshold. The manufacturer-defined threshold could be a simple fixed value or a dyna...";
CM_ SG_ 2364614654 GradeThresholdIndicator2 "Grade Threshold Indicator 2: This parameter indicates whether or not the transmitting device has sensed a vehicle grade equal to or exceeding a manufacturer-defined threshold. The manufacturer-defined threshold could be a simple fixed value or a dyna...";
CM_ SG_ 2364614654 GradeThresholdIndicator3 "Grade Threshold Indicator 3: This parameter indicates whether or not the transmitting device has sensed a vehicle grade equal to or exceeding a manufacturer-defined threshold. The manufacturer-defined threshold could be a simple fixed value or a dyna...";
CM_ SG_ 2364614654 GradeThresholdIndicator4 "Grade Threshold Indicator 4: This parameter indicates whether or not the transmitting device has sensed a vehicle grade equal to or exceeding a manufacturer-defined threshold. The manufacturer-defined threshold could be a simple fixed value or a dyna...";
CM_ SG_ 2364614654 GradeThresholdIndicator5 "Grade Threshold Indicator 5: This parameter indicates whether or not the transmitting device has sensed a vehicle grade equal to or exceeding a manufacturer-defined threshold. The manufacturer-defined threshold could be a simple fixed value or a dyna...";
CM_ SG_ 2364614654 GradeThresholdIndicator6 "Grade Threshold Indicator 6: This parameter indicates whether or not the transmitting device has sensed a vehicle grade equal to or exceeding a manufacturer-defined threshold. The manufacturer-defined threshold could be a simple fixed value or a dyna...";
CM_ BO_ 2364614910 "DC/AC Accessory Inverter 3 Status 2";
CM_ SG_ 2364614910 DAAssrInvrtr3DSdPwr "DC/AC Accessory Inverter 3 DC Side Power: Power measured at the DC Side input to the DC/AC Accessory Inverter. ";
CM_ SG_ 2364614910 DAAssrInvrtr3DSdVltg "DC/AC Accessory Inverter 3 DC Side Voltage: DC Side input voltage measured at the point of control inside the DC/AC Accessory Inverter.";
CM_ SG_ 2364614910 DAAssrInvrtr3DSdCrrnt "DC/AC Accessory Inverter 3 DC Side Current: DC Side input current measured at the point of control inside the DC/AC Accessory Inverter.";
CM_ SG_ 2364614910 DAAssIvt3DSdNtvTCsssGdVt "DC/AC Accessory Inverter 3 DC Side Negative to Chassis Ground Voltage: The voltage level of the high voltage DC side, as measured by the DC/AC between the negative side of the High Voltage DC Side input and the chassis of the DC/AC enclosure.  This v...";
CM_ BO_ 2364615166 "DC/AC Accessory Inverter 3 Voltage";
CM_ SG_ 2364615166 DAAssrInvrtr3IgntnVltg "DC/AC Accessory Inverter 3 Ignition Voltage: Ignition voltage supplied to the  DC/AC Accessory Inverter controller.";
CM_ SG_ 2364615166 DAAssrInvrtr3UnswthdSlVltg "DC/AC Accessory Inverter 3 Unswitched SLI Voltage: Continuously supplied SLI power to this instance of the DC/AC Accessory Inverter controller.";
CM_ BO_ 2364615678 "DC/AC Accessory Inverter 4 Status 2";
CM_ SG_ 2364615678 DAAssrInvrtr4DSdPwr "DC/AC Accessory Inverter 4 DC Side Power: Power measured at the DC Side input to the DC/AC Accessory Inverter. ";
CM_ SG_ 2364615678 DAAssrInvrtr4DSdVltg "DC/AC Accessory Inverter 4 DC Side Voltage: DC Side input voltage measured at the point of control inside the DC/AC Accessory Inverter.";
CM_ SG_ 2364615678 DAAssrInvrtr4DSdCrrnt "DC/AC Accessory Inverter 4 DC Side Current: DC Side input current measured at the point of control inside the DC/AC Accessory Inverter.";
CM_ SG_ 2364615678 DAAssIvt4DSdNtvTCsssGdVt "DC/AC Accessory Inverter 4 DC Side Negative to Chassis Ground Voltage: The voltage level of the high voltage DC side, as measured by the DC/AC between the negative side of the High Voltage DC Side input and the chassis of the DC/AC enclosure.  This v...";
CM_ BO_ 2364615934 "DC/AC Accessory Inverter 4 Voltage";
CM_ SG_ 2364615934 DAAssrInvrtr4IgntnVltg "DC/AC Accessory Inverter 4 Ignition Voltage: Ignition voltage supplied to the  DC/AC Accessory Inverter controller.";
CM_ SG_ 2364615934 DAAssrInvrtr4UnswthdSlVltg "DC/AC Accessory Inverter 4 Unswitched SLI Voltage: Continuously supplied SLI power to this instance of the DC/AC Accessory Inverter controller.";
CM_ BO_ 2364616958 "DC/AC Accessory Inverter 5 Status 2";
CM_ SG_ 2364616958 DAAssrInvrtr5DSdPwr "DC/AC Accessory Inverter 5 DC Side Power: Power measured at the DC Side input to the DC/AC Accessory Inverter. ";
CM_ SG_ 2364616958 DAAssrInvrtr5DSdVltg "DC/AC Accessory Inverter 5 DC Side Voltage: DC Side input voltage measured at the point of control inside the DC/AC Accessory Inverter.";
CM_ SG_ 2364616958 DAAssrInvrtr5DSdCrrnt "DC/AC Accessory Inverter 5 DC Side Current: DC Side input current measured at the point of control inside the DC/AC Accessory Inverter.";
CM_ SG_ 2364616958 DAAssIvt5DSdNtvTCsssGdVt "DC/AC Accessory Inverter 5 DC Side Negative to Chassis Ground Voltage: The voltage level of the high voltage DC side, as measured by the DC/AC between the negative side of the High Voltage DC Side input and the chassis of the DC/AC enclosure.  This v...";
CM_ BO_ 2364617214 "DC/AC Accessory Inverter 5 Voltage";
CM_ SG_ 2364617214 DAAssrInvrtr5IgntnVltg "DC/AC Accessory Inverter 5 Ignition Voltage: Ignition voltage supplied to the  DC/AC Accessory Inverter controller.";
CM_ SG_ 2364617214 DAAssrInvrtr5UnswthdSlVltg "DC/AC Accessory Inverter 5 Unswitched SLI Voltage: Continuously supplied SLI power to this instance of the DC/AC Accessory Inverter controller.";
CM_ BO_ 2365296894 "DC/DC Converter 4 Voltage";
CM_ SG_ 2365296894 DD4CntrllrInptIgntnVltg "DC/DC 4 Controller Input Ignition Voltage: Ignition voltage (i.e. switched) supplied to the  DC/DC Converter controller.";
CM_ SG_ 2365296894 DD4CntrllrInptUnswthdSlVltg "DC/DC 4 Controller Input Unswitched SLI Voltage: Continuously supplied SLI power to this instance of the DC/DC Converter controller.";
CM_ BO_ 2365297150 "DC/DC Converter 3 Voltage";
CM_ SG_ 2365297150 DD3CntrllrInptIgntnVltg "DC/DC 3 Controller Input Ignition Voltage: Ignition voltage (i.e. switched) supplied to the  DC/DC Converter controller.";
CM_ SG_ 2365297150 DD3CntrllrInptUnswthdSlVltg "DC/DC 3 Controller Input Unswitched SLI Voltage: Continuously supplied SLI power to this instance of the DC/DC Converter controller.";
CM_ BO_ 2365297406 "DC/DC Converter 2 Voltage";
CM_ SG_ 2365297406 DD2CntrllrInptIgntnVltg "DC/DC 2 Controller Input Ignition Voltage: Ignition voltage (i.e. switched) supplied to the  DC/DC Converter controller.";
CM_ SG_ 2365297406 DD2CntrllrInptUnswthdSlVltg "DC/DC 2 Controller Input Unswitched SLI Voltage: Continuously supplied SLI power to this instance of the DC/DC Converter controller.";
BA_DEF_ SG_  "SPN" INT 0 524287;
BA_DEF_ BO_  "VFrameFormat" ENUM  "StandardCAN","ExtendedCAN","reserved","J1939PG";
BA_DEF_DEF_  "SPN" 0;
BA_DEF_DEF_  "VFrameFormat" "J1939PG";
BA_ "SPN" SG_ 2364557822 EngineCylinder16HeatRelease 6456;
BA_ "SPN" SG_ 2364557822 EngineCylinder16PeakPressure 6457;
BA_ "SPN" SG_ 2364557822 EngnClndr16LwFrqnKnkLvl 7624;
BA_ "SPN" SG_ 2364557822 EngnClndr16MxmmPrssrInrsRt 7644;
BA_ "SPN" SG_ 2364557822 EngnClndr16SnhrnsKnkLvl 6458;
BA_ "SPN" SG_ 2364557822 EngnClndr16PrssrSnsrPrlmnrFm 6459;
BA_ "SPN" SG_ 2364558078 EngineCylinder17HeatRelease 6460;
BA_ "SPN" SG_ 2364558078 EngineCylinder17PeakPressure 6461;
BA_ "SPN" SG_ 2364558078 EngnClndr17LwFrqnKnkLvl 7625;
BA_ "SPN" SG_ 2364558078 EngnClndr17MxmmPrssrInrsRt 7645;
BA_ "SPN" SG_ 2364558078 EngnClndr17SnhrnsKnkLvl 6462;
BA_ "SPN" SG_ 2364558078 EngnClndr17PrssrSnsrPrlmnrFm 6463;
BA_ "SPN" SG_ 2364558334 EngineCylinder18HeatRelease 6464;
BA_ "SPN" SG_ 2364558334 EngineCylinder18PeakPressure 6465;
BA_ "SPN" SG_ 2364558334 EngnClndr18LwFrqnKnkLvl 7626;
BA_ "SPN" SG_ 2364558334 EngnClndr18MxmmPrssrInrsRt 7646;
BA_ "SPN" SG_ 2364558334 EngnClndr18SnhrnsKnkLvl 6466;
BA_ "SPN" SG_ 2364558334 EngnClndr18PrssrSnsrPrlmnrFm 6467;
BA_ "SPN" SG_ 2364558590 EngineCylinder19HeatRelease 6468;
BA_ "SPN" SG_ 2364558590 EngineCylinder19PeakPressure 6469;
BA_ "SPN" SG_ 2364558590 EngnClndr19LwFrqnKnkLvl 7627;
BA_ "SPN" SG_ 2364558590 EngnClndr19MxmmPrssrInrsRt 7647;
BA_ "SPN" SG_ 2364558590 EngnClndr19SnhrnsKnkLvl 6470;
BA_ "SPN" SG_ 2364558590 EngnClndr19PrssrSnsrPrlmnrFm 6471;
BA_ "SPN" SG_ 2364558846 EngineCylinder20HeatRelease 6472;
BA_ "SPN" SG_ 2364558846 EngineCylinder20PeakPressure 6473;
BA_ "SPN" SG_ 2364558846 EngnClndr20LwFrqnKnkLvl 7628;
BA_ "SPN" SG_ 2364558846 EngnClndr20MxmmPrssrInrsRt 7648;
BA_ "SPN" SG_ 2364558846 EngnClndr20SnhrnsKnkLvl 6474;
BA_ "SPN" SG_ 2364558846 EngnClndr20PrssrSnsrPrlmnrFm 6475;
BA_ "SPN" SG_ 2364564478 EngnGssFlVlvNmnlDrtnCmmnd 6656;
BA_ "SPN" SG_ 2364564478 EngnPrChmrFlVlvNmnlDrtnCmmnd 9650;
BA_ "SPN" SG_ 2364564478 EngnGssFlVlvNmnlStrtOfAttnCmmnd 6657;
BA_ "SPN" SG_ 2364564478 EPCFVvNSttOAttCd 9651;
BA_ "SPN" SG_ 2364564734 EngnGssFlVlv1DrtnCmmnd 6658;
BA_ "SPN" SG_ 2364564734 EngnGssFlVlv2DrtnCmmnd 6659;
BA_ "SPN" SG_ 2364564734 EngnGssFlVlv3DrtnCmmnd 6660;
BA_ "SPN" SG_ 2364564734 EngnGssFlVlv4DrtnCmmnd 6661;
BA_ "SPN" SG_ 2364564990 EngnGssFlVlv5DrtnCmmnd 6662;
BA_ "SPN" SG_ 2364564990 EngnGssFlVlv6DrtnCmmnd 6663;
BA_ "SPN" SG_ 2364564990 EngnGssFlVlv7DrtnCmmnd 6664;
BA_ "SPN" SG_ 2364564990 EngnGssFlVlv8DrtnCmmnd 6665;
BA_ "SPN" SG_ 2364565246 EngnGssFlVlv10DrtnCmmnd 6667;
BA_ "SPN" SG_ 2364565246 EngnGssFlVlv11DrtnCmmnd 6668;
BA_ "SPN" SG_ 2364565246 EngnGssFlVlv12DrtnCmmnd 6669;
BA_ "SPN" SG_ 2364565246 EngnGssFlVlv9DrtnCmmnd 6666;
BA_ "SPN" SG_ 2364565502 EngnGssFlVlv13DrtnCmmnd 6670;
BA_ "SPN" SG_ 2364565502 EngnGssFlVlv14DrtnCmmnd 6671;
BA_ "SPN" SG_ 2364565502 EngnGssFlVlv15DrtnCmmnd 6672;
BA_ "SPN" SG_ 2364565502 EngnGssFlVlv16DrtnCmmnd 6673;
BA_ "SPN" SG_ 2364565758 EngnGssFlVlv17DrtnCmmnd 6674;
BA_ "SPN" SG_ 2364565758 EngnGssFlVlv18DrtnCmmnd 6675;
BA_ "SPN" SG_ 2364565758 EngnGssFlVlv19DrtnCmmnd 6676;
BA_ "SPN" SG_ 2364565758 EngnGssFlVlv20DrtnCmmnd 6677;
BA_ "SPN" SG_ 2364566014 EngnGssFlVlv1StrtOfAttnCmmnd 6678;
BA_ "SPN" SG_ 2364566014 EngnGssFlVlv2StrtOfAttnCmmnd 6679;
BA_ "SPN" SG_ 2364566014 EngnGssFlVlv3StrtOfAttnCmmnd 6680;
BA_ "SPN" SG_ 2364566014 EngnGssFlVlv4StrtOfAttnCmmnd 6681;
BA_ "SPN" SG_ 2364566270 EngnGssFlVlv5StrtOfAttnCmmnd 6682;
BA_ "SPN" SG_ 2364566270 EngnGssFlVlv6StrtOfAttnCmmnd 6683;
BA_ "SPN" SG_ 2364566270 EngnGssFlVlv7StrtOfAttnCmmnd 6684;
BA_ "SPN" SG_ 2364566270 EngnGssFlVlv8StrtOfAttnCmmnd 6685;
BA_ "SPN" SG_ 2364566526 EngnGssFlVlv9StrtOfAttnCmmnd 6686;
BA_ "SPN" SG_ 2364566526 EngnGssFlVlv10StrtOfAttnCmmnd 6687;
BA_ "SPN" SG_ 2364566526 EngnGssFlVlv11StrtOfAttnCmmnd 6688;
BA_ "SPN" SG_ 2364566526 EngnGssFlVlv12StrtOfAttnCmmnd 6689;
BA_ "SPN" SG_ 2364566782 EngnGssFlVlv13StrtOfAttnCmmnd 6690;
BA_ "SPN" SG_ 2364566782 EngnGssFlVlv14StrtOfAttnCmmnd 6691;
BA_ "SPN" SG_ 2364566782 EngnGssFlVlv15StrtOfAttnCmmnd 6692;
BA_ "SPN" SG_ 2364566782 EngnGssFlVlv16StrtOfAttnCmmnd 6693;
BA_ "SPN" SG_ 2364567038 EngnGssFlVlv17StrtOfAttnCmmnd 6694;
BA_ "SPN" SG_ 2364567038 EngnGssFlVlv18StrtOfAttnCmmnd 6695;
BA_ "SPN" SG_ 2364567038 EngnGssFlVlv19StrtOfAttnCmmnd 6696;
BA_ "SPN" SG_ 2364567038 EngnGssFlVlv20StrtOfAttnCmmnd 6697;
BA_ "SPN" SG_ 2364567294 EngnFlInjtnPmp1FlCntrlVlvCmmnd 6719;
BA_ "SPN" SG_ 2364567294 EngnFlInjtnPmp2FlCntrlVlvCmmnd 6720;
BA_ "SPN" SG_ 2364575998 HvessAvailableDischargePower 5917;
BA_ "SPN" SG_ 2364575998 HvessAvailableChargePower 5918;
BA_ "SPN" SG_ 2364575998 HvessVoltageLevel 5919;
BA_ "SPN" SG_ 2364575998 HvessCurrent 5920;
BA_ "SPN" SG_ 2364576254 HvessFastUpdateStateOfCharge 5921;
BA_ "SPN" SG_ 2364576254 HvessHighestCellVoltage 5922;
BA_ "SPN" SG_ 2364576254 HvessLowestCellVoltage 5923;
BA_ "SPN" SG_ 2364576254 HvssCllVltgDffrntlStts 5924;
BA_ "SPN" SG_ 2364576510 HvessHighestCellTemperature 8075;
BA_ "SPN" SG_ 2364576510 HvessLowestCellTemperature 8076;
BA_ "SPN" SG_ 2364576510 HvessAverageCellTemperature 8077;
BA_ "SPN" SG_ 2364576510 HvssCllTmprtrDffrntlStts 8078;
BA_ "SPN" SG_ 2364576766 HvessDischargeCapacity 8079;
BA_ "SPN" SG_ 2364576766 HvessChargeCapacity 8080;
BA_ "SPN" SG_ 2364576766 HvessCellBalancingCount 8081;
BA_ "SPN" SG_ 2364577022 HvessMinimumCellStateOfCharge 8084;
BA_ "SPN" SG_ 2364577022 HvessMaximumCellStateOfCharge 8085;
BA_ "SPN" SG_ 2364577022 HvssMxmmInstntnsDshrgCrrntLmt 8082;
BA_ "SPN" SG_ 2364577022 HvssMxmmInstntnsChrgCrrntLmt 8083;
BA_ "SPN" SG_ 2364577278 HvessBusVoltage 8086;
BA_ "SPN" SG_ 2364577278 HvessIgnitionVoltage 8087;
BA_ "SPN" SG_ 2364577278 HvessIntakeCoolantTemperature 8088;
BA_ "SPN" SG_ 2364577278 HvessOutletCoolantTemperature 8089;
BA_ "SPN" SG_ 2364577278 HvessElectronicsTemperature 8204;
BA_ "SPN" SG_ 2364577278 HvessTemperature 9119;
BA_ "SPN" SG_ 2364577534 HvessCenterOfPackContactorState 8095;
BA_ "SPN" SG_ 2364577534 HvessHvilStatus 8098;
BA_ "SPN" SG_ 2364577534 HvessInertiaSwitchStatus 8099;
BA_ "SPN" SG_ 2364577534 HvessStateOfChargeStatus 8100;
BA_ "SPN" SG_ 2364577534 HvessCellBalanceStatus 8101;
BA_ "SPN" SG_ 2364577534 HvessCellBalancingActive 8102;
BA_ "SPN" SG_ 2364577534 HvessInternalChargerStatus 8207;
BA_ "SPN" SG_ 2364577534 HvessOperationalStatus 8414;
BA_ "SPN" SG_ 2364577534 HvessNumberOfHvespsReady 12905;
BA_ "SPN" SG_ 2364577534 HvessStatus1Counter 13013;
BA_ "SPN" SG_ 2364577534 HvessStatus1Crc 13014;
BA_ "SPN" SG_ 2364577534 HvssHghVltgBsPstvCnttrStt 8091;
BA_ "SPN" SG_ 2364577534 HvssHghVltgBsNgtvCnttrStt 8092;
BA_ "SPN" SG_ 2364577534 HvssHghVltgBsDsnntFrwrnng 8093;
BA_ "SPN" SG_ 2364577534 HvssHghVltgBsPrChrgRlStt 8094;
BA_ "SPN" SG_ 2364577534 HvssHghVltgBsAtvIsltnTstStts 8096;
BA_ "SPN" SG_ 2364577534 HvssHghVltgBsPssvIsltnTstStts 8097;
BA_ "SPN" SG_ 2364577534 HvssHghVltgBsCnntnStts 8413;
BA_ "SPN" SG_ 2364580094 HvessDischargeEnergyCapacity 8205;
BA_ "SPN" SG_ 2364580094 HvessChargeEnergyCapacity 8206;
BA_ "SPN" SG_ 2364580094 HvessMaximumChargeVoltageLimit 8090;
BA_ "SPN" SG_ 2364590334 DAAssrInvrtr1DSdPwr 8889;
BA_ "SPN" SG_ 2364590334 DAAssrInvrtr1DSdVltg 8890;
BA_ "SPN" SG_ 2364590334 DAAssrInvrtr1DSdCrrnt 8891;
BA_ "SPN" SG_ 2364590334 DAAssIvt1DSdNtvTCsssGdVt 9582;
BA_ "SPN" SG_ 2364590590 DAAssrInvrtr1IgntnVltg 9209;
BA_ "SPN" SG_ 2364590590 DAAssrInvrtr1UnswthdSlVltg 9210;
BA_ "SPN" SG_ 2364591102 DAAssrInvrtr2DSdPwr 9236;
BA_ "SPN" SG_ 2364591102 DAAssrInvrtr2DSdVltg 9237;
BA_ "SPN" SG_ 2364591102 DAAssrInvrtr2DSdCrrnt 9238;
BA_ "SPN" SG_ 2364591102 DAAssIvt2DSdNtvTCsssGdVt 9583;
BA_ "SPN" SG_ 2364591358 DAAssrInvrtr2IgntnVltg 9239;
BA_ "SPN" SG_ 2364591358 DAAssrInvrtr2UnswthdSlVltg 9240;
BA_ "SPN" SG_ 2364592382 EngnClndr10ExldFrmCmstnRqst 7001;
BA_ "SPN" SG_ 2364592382 EngnClndr11ExldFrmCmstnRqst 7002;
BA_ "SPN" SG_ 2364592382 EngnClndr12ExldFrmCmstnRqst 7003;
BA_ "SPN" SG_ 2364592382 EngnClndr13ExldFrmCmstnRqst 7004;
BA_ "SPN" SG_ 2364592382 EngnClndr14ExldFrmCmstnRqst 7005;
BA_ "SPN" SG_ 2364592382 EngnClndr15ExldFrmCmstnRqst 7006;
BA_ "SPN" SG_ 2364592382 EngnClndr16ExldFrmCmstnRqst 7007;
BA_ "SPN" SG_ 2364592382 EngnClndr17ExldFrmCmstnRqst 7008;
BA_ "SPN" SG_ 2364592382 EngnClndr18ExldFrmCmstnRqst 7009;
BA_ "SPN" SG_ 2364592382 EngnClndr19ExldFrmCmstnRqst 7010;
BA_ "SPN" SG_ 2364592382 EngnClndr1ExldFrmCmstnRqst 6992;
BA_ "SPN" SG_ 2364592382 EngnClndr20ExldFrmCmstnRqst 7011;
BA_ "SPN" SG_ 2364592382 EngnClndr21ExldFrmCmstnRqst 7012;
BA_ "SPN" SG_ 2364592382 EngnClndr22ExldFrmCmstnRqst 7013;
BA_ "SPN" SG_ 2364592382 EngnClndr23ExldFrmCmstnRqst 7014;
BA_ "SPN" SG_ 2364592382 EngnClndr24ExldFrmCmstnRqst 7015;
BA_ "SPN" SG_ 2364592382 EngnClndr2ExldFrmCmstnRqst 6993;
BA_ "SPN" SG_ 2364592382 EngnClndr3ExldFrmCmstnRqst 6994;
BA_ "SPN" SG_ 2364592382 EngnClndr4ExldFrmCmstnRqst 6995;
BA_ "SPN" SG_ 2364592382 EngnClndr5ExldFrmCmstnRqst 6996;
BA_ "SPN" SG_ 2364592382 EngnClndr6ExldFrmCmstnRqst 6997;
BA_ "SPN" SG_ 2364592382 EngnClndr7ExldFrmCmstnRqst 6998;
BA_ "SPN" SG_ 2364592382 EngnClndr8ExldFrmCmstnRqst 6999;
BA_ "SPN" SG_ 2364592382 EngnClndr9ExldFrmCmstnRqst 7000;
BA_ "SPN" SG_ 2364592382 NmrOfEngnClndrsTExldFrmCmstn 6991;
BA_ "SPN" SG_ 2364592638 EngnClndrHdBpssAttr1DsrdPstn 7091;
BA_ "SPN" SG_ 2364592638 EngnClndrHdBpssAttr1OprtnStts 7093;
BA_ "SPN" SG_ 2364592638 EngnClndrHdBpssAttr1Pstn 7092;
BA_ "SPN" SG_ 2364592638 EngnClndrHdBpssAttr1Tmprtr 7090;
BA_ "SPN" SG_ 2364592638 EngnClndrHdBpssAttr1TmprtrStts 7089;
BA_ "SPN" SG_ 2364592638 EngnClndrHdBpssAttr1PrlmnrFm 7088;
BA_ "SPN" SG_ 2364592894 EngineIntakeAirSourceValve 6330;
BA_ "SPN" SG_ 2364592894 EngnClndrHdBpssAttr1Cmmnd 7094;
BA_ "SPN" SG_ 2364592894 EngnExhstGsRstrtnVlvPstn 8151;
BA_ "SPN" SG_ 2364593150 PrdtvCrsCntrlDrvlnDsnggInhtRqst 7430;
BA_ "SPN" SG_ 2364593150 PrdtvCrsCntrlSpdEvntIndtr 7434;
BA_ "SPN" SG_ 2364593150 PrdtvCrsCntrlStSpdOffst 7316;
BA_ "SPN" SG_ 2364593150 PredictiveCruiseControlState 7317;
BA_ "SPN" SG_ 2364593150 RoadwayNextGrade 7433;
BA_ "SPN" SG_ 2364593150 RoadwayNextGradeDistance 9199;
BA_ "SPN" SG_ 2364593150 RoadwayPresentGrade 7432;
BA_ "SPN" SG_ 2364593150 VhlSpdCntrlOvrrdEvntIndtr 7435;
BA_ "SPN" SG_ 2364593150 VhlSpdCntrlOvrrdRqst 7429;
BA_ "SPN" SG_ 2364593150 PrdtvCrsCntrlEvntInRng 7431;
BA_ "SPN" SG_ 2364597758 EngnClndr1IgntnTmngOffst 7356;
BA_ "SPN" SG_ 2364597758 EngnClndr2IgntnTmngOffst 7357;
BA_ "SPN" SG_ 2364597758 EngnClndr3IgntnTmngOffst 7358;
BA_ "SPN" SG_ 2364597758 EngnClndr4IgntnTmngOffst 7359;
BA_ "SPN" SG_ 2364597758 EngnClndr5IgntnTmngOffst 7360;
BA_ "SPN" SG_ 2364597758 EngnClndr6IgntnTmngOffst 7361;
BA_ "SPN" SG_ 2364597758 EngnClndr7IgntnTmngOffst 7362;
BA_ "SPN" SG_ 2364597758 EngnClndr8IgntnTmngOffst 7363;
BA_ "SPN" SG_ 2364598014 EngnClndr10IgntnTmngOffst 7365;
BA_ "SPN" SG_ 2364598014 EngnClndr11IgntnTmngOffst 7366;
BA_ "SPN" SG_ 2364598014 EngnClndr12IgntnTmngOffst 7367;
BA_ "SPN" SG_ 2364598014 EngnClndr13IgntnTmngOffst 7368;
BA_ "SPN" SG_ 2364598014 EngnClndr14IgntnTmngOffst 7369;
BA_ "SPN" SG_ 2364598014 EngnClndr15IgntnTmngOffst 7370;
BA_ "SPN" SG_ 2364598014 EngnClndr16IgntnTmngOffst 7371;
BA_ "SPN" SG_ 2364598014 EngnClndr9IgntnTmngOffst 7364;
BA_ "SPN" SG_ 2364598270 EngnClndr17IgntnTmngOffst 7372;
BA_ "SPN" SG_ 2364598270 EngnClndr18IgntnTmngOffst 7373;
BA_ "SPN" SG_ 2364598270 EngnClndr19IgntnTmngOffst 7374;
BA_ "SPN" SG_ 2364598270 EngnClndr20IgntnTmngOffst 7375;
BA_ "SPN" SG_ 2364598270 EngnClndr21IgntnTmngOffst 7376;
BA_ "SPN" SG_ 2364598270 EngnClndr22IgntnTmngOffst 7377;
BA_ "SPN" SG_ 2364598270 EngnClndr23IgntnTmngOffst 7378;
BA_ "SPN" SG_ 2364598270 EngnClndr24IgntnTmngOffst 7379;
BA_ "SPN" SG_ 2364598526 EngnFlAttr3CntrlCmmnd 7593;
BA_ "SPN" SG_ 2364598526 EngnFlAttr4CntrlCmmnd 7594;
BA_ "SPN" SG_ 2364598526 EngnFlAttr1MtrCrrntDsl 21164;
BA_ "SPN" SG_ 2364598526 EngnFlAttr2MtrCrrntDsl 21165;
BA_ "SPN" SG_ 2364602878 EngnVlvCntrlMdl1PrlmnrFm 7770;
BA_ "SPN" SG_ 2364602878 EngnVlvCntrlMdl2PrlmnrFm 7771;
BA_ "SPN" SG_ 2364602878 EngnVlvCntrlMdl3PrlmnrFm 7772;
BA_ "SPN" SG_ 2364602878 EngnVlvCntrlMdl4PrlmnrFm 7773;
BA_ "SPN" SG_ 2364602878 EngnVlvCntrlMdl5PrlmnrFm 7774;
BA_ "SPN" SG_ 2364602878 EngnVlvCntrlMdl6PrlmnrFm 7775;
BA_ "SPN" SG_ 2364602878 EngnVlvCntrlMdl7PrlmnrFm 7776;
BA_ "SPN" SG_ 2364602878 EngnVlvCntrlMdl8PrlmnrFm 7777;
BA_ "SPN" SG_ 2364603134 MxmmFrwrdTrnsmssnOtptShftSpd 7779;
BA_ "SPN" SG_ 2364603134 MxmmRvrsTrnsmssnOtptShftSpd 7780;
BA_ "SPN" SG_ 2364603134 TransmissionMode11Indicator 12939;
BA_ "SPN" SG_ 2364603134 TransmissionMode12Indicator 12940;
BA_ "SPN" SG_ 2364603134 TransmissionMode13Indicator 12941;
BA_ "SPN" SG_ 2364603134 TransmissionMode14Indicator 12942;
BA_ "SPN" SG_ 2364603134 TransmissionMode15Indicator 12943;
BA_ "SPN" SG_ 2364603134 TransmissionMode16Indicator 12944;
BA_ "SPN" SG_ 2364603134 TransmissionMode17Indicator 12945;
BA_ "SPN" SG_ 2364603134 TransmissionMode18Indicator 12946;
BA_ "SPN" SG_ 2364603134 TransmissionMode19Indicator 12947;
BA_ "SPN" SG_ 2364603134 TransmissionMode20Indicator 12948;
BA_ "SPN" SG_ 2364603134 SAddssOAtvOPdTsssRqstdG 8613;
BA_ "SPN" SG_ 2364603390 Atttt1DsExstFdDsVv1Cd 8442;
BA_ "SPN" SG_ 2364603390 Atttt1DsExstFdRqstdQttOIttHRst 7783;
BA_ "SPN" SG_ 2364603390 Atttt1DsExstFdDsVv2Cd 8307;
BA_ "SPN" SG_ 2364603646 Atttt2DsExstFdRqstdQttOIttHRst 7784;
BA_ "SPN" SG_ 2364603646 Atttt2DsExstFdDsVv1Cd 22720;
BA_ "SPN" SG_ 2364603646 Atttt2DsExstFdDsVv2Cd 22721;
BA_ "SPN" SG_ 2364603902 Atttt1DsExstFdAtQttOIttHRst 7786;
BA_ "SPN" SG_ 2364604158 Atttt2DsExstFdAtQttOIttHRst 7787;
BA_ "SPN" SG_ 2364605438 GeneratorTripKvarHoursExport 7832;
BA_ "SPN" SG_ 2364605438 GeneratorTripKwHoursExport 7831;
BA_ "SPN" SG_ 2364605950 HydraulicLinePressure 7939;
BA_ "SPN" SG_ 2364605950 MechanicalMovementAngle 7940;
BA_ "SPN" SG_ 2364606718 HvessModule1OperationalStatus 8214;
BA_ "SPN" SG_ 2364606718 HvessModule2OperationalStatus 8215;
BA_ "SPN" SG_ 2364606718 HvessModule3OperationalStatus 8216;
BA_ "SPN" SG_ 2364606718 HvessModule4OperationalStatus 8217;
BA_ "SPN" SG_ 2364606718 HvessModule5OperationalStatus 8218;
BA_ "SPN" SG_ 2364606718 HvessModule6OperationalStatus 8219;
BA_ "SPN" SG_ 2364606718 HvessModule7OperationalStatus 8220;
BA_ "SPN" SG_ 2364606718 HvessModule8OperationalStatus 8221;
BA_ "SPN" SG_ 2364606718 HvessModule9OperationalStatus 8222;
BA_ "SPN" SG_ 2364606718 HvessModule10OperationalStatus 8223;
BA_ "SPN" SG_ 2364606718 HvessModule11OperationalStatus 8224;
BA_ "SPN" SG_ 2364606718 HvessModule12OperationalStatus 8225;
BA_ "SPN" SG_ 2364606718 HvessModule13OperationalStatus 8226;
BA_ "SPN" SG_ 2364606718 HvessModule14OperationalStatus 8227;
BA_ "SPN" SG_ 2364606718 HvessModule15OperationalStatus 8228;
BA_ "SPN" SG_ 2364606718 HvessModule16OperationalStatus 8229;
BA_ "SPN" SG_ 2364606718 HvessModule17OperationalStatus 14609;
BA_ "SPN" SG_ 2364606718 HvessModule18OperationalStatus 14610;
BA_ "SPN" SG_ 2364606718 HvessModule19OperationalStatus 14611;
BA_ "SPN" SG_ 2364606718 HvessModule20OperationalStatus 14612;
BA_ "SPN" SG_ 2364606718 HvessModule21OperationalStatus 14613;
BA_ "SPN" SG_ 2364606718 HvessModule22OperationalStatus 14614;
BA_ "SPN" SG_ 2364606718 HvessModule23OperationalStatus 14615;
BA_ "SPN" SG_ 2364606718 HvessModule24OperationalStatus 14616;
BA_ "SPN" SG_ 2364606718 HvessModule25OperationalStatus 14617;
BA_ "SPN" SG_ 2364606718 HvessModule26OperationalStatus 14618;
BA_ "SPN" SG_ 2364606718 HvessModule27OperationalStatus 14619;
BA_ "SPN" SG_ 2364606718 HvessModule28OperationalStatus 14620;
BA_ "SPN" SG_ 2364606718 HvessModule29OperationalStatus 14621;
BA_ "SPN" SG_ 2364606718 HvessModule30OperationalStatus 14622;
BA_ "SPN" SG_ 2364606718 HvessModule31OperationalStatus 14623;
BA_ "SPN" SG_ 2364606718 HvessModule32OperationalStatus 14624;
BA_ "SPN" SG_ 2364606974 HvssThrmlMngmntSstmSlInptPwr 8230;
BA_ "SPN" SG_ 2364606974 HvssTMtSstHVtIptPw 8231;
BA_ "SPN" SG_ 2364606974 HvssThrmlMngmntSstmCmprssrSpd 8232;
BA_ "SPN" SG_ 2364606974 HvssThrmlMngmntSstmRltvHmdt 8233;
BA_ "SPN" SG_ 2364606974 HvssThrmlMngmntSstmHtrStts 8234;
BA_ "SPN" SG_ 2364606974 HvssThrmlMngmntSstmHvlStts 12813;
BA_ "SPN" SG_ 2364606974 HvssThrmlMngmntSstmMd 8235;
BA_ "SPN" SG_ 2364606974 HvssThrmlMngmntSstmClntLvl 12897;
BA_ "SPN" SG_ 2364606974 HvssThrmlMngmntSstmClntLvlFll 23400;
BA_ "SPN" SG_ 2364607230 HvessAverageCellVoltage 8240;
BA_ "SPN" SG_ 2364607230 HvssHghstCllVltgMdlNmr 8236;
BA_ "SPN" SG_ 2364607230 HvssHghstCllVltgCllNmr 8237;
BA_ "SPN" SG_ 2364607230 HvssLwstCllVltgMdlNmr 8238;
BA_ "SPN" SG_ 2364607230 HvssLwstCllVltgCllNmr 8239;
BA_ "SPN" SG_ 2364607486 HvssHghstCllTmprtrMdlNmr 8241;
BA_ "SPN" SG_ 2364607486 HvssHghstCllTmprtrCllNmr 8242;
BA_ "SPN" SG_ 2364607486 HvssLwstCllTmprtrMdlNmr 8243;
BA_ "SPN" SG_ 2364607486 HvssLwstCllTmprtrCllNmr 8244;
BA_ "SPN" SG_ 2364607486 HvessThermalEventDetected 21287;
BA_ "SPN" SG_ 2364607486 HvssDt9EmdddIntgrtSpprt 22971;
BA_ "SPN" SG_ 2364607486 HvessData9Counter 22972;
BA_ "SPN" SG_ 2364607486 HvessData9Crc 22973;
BA_ "SPN" SG_ 2364607742 HvssHghstCllSttOfChrgMdlNmr 8245;
BA_ "SPN" SG_ 2364607742 HvssHghstCllSttOfChrgCllNmr 8246;
BA_ "SPN" SG_ 2364607742 HvssLwstCllSttOfChrgMdlNmr 8247;
BA_ "SPN" SG_ 2364607742 HvssLwstCllSttOfChrgCllNmr 8248;
BA_ "SPN" SG_ 2364607742 HvssHghVltgBsAtvIsltnTstRslts 8431;
BA_ "SPN" SG_ 2364607742 HvssHghVltgBsPssvIsltnTstRslts 8432;
BA_ "SPN" SG_ 2364608510 EnginePowerDerateRequest 8436;
BA_ "SPN" SG_ 2364608510 EngineSelfInducedDerateLoad 8435;
BA_ "SPN" SG_ 2364608510 PwrtrnPrttnIsDsldDTChsssNtDttd 22135;
BA_ "SPN" SG_ 2364608510 EngineCoolantFlow 22136;
BA_ "SPN" SG_ 2364608510 AttttTMtEvtdIdStts 22134;
BA_ "SPN" SG_ 2364609278 DcDc1LowSideVoltageBuckSetpoint 8561;
BA_ "SPN" SG_ 2364609278 DcDc1OperationalCommand 8560;
BA_ "SPN" SG_ 2364609278 DcDc1ControlCounter 7955;
BA_ "SPN" SG_ 2364609278 DcDc1ControlCrc 7956;
BA_ "SPN" SG_ 2364609278 DD1HghSdVltgBstStpnt 8562;
BA_ "SPN" SG_ 2364609278 DD1LwSdVltgBkDfltStpnt 9515;
BA_ "SPN" SG_ 2364609534 DcDc1HvilStatus 8570;
BA_ "SPN" SG_ 2364609534 DcDc1LoadshedRequest 8571;
BA_ "SPN" SG_ 2364609534 DcDc1OperationalStatus 8569;
BA_ "SPN" SG_ 2364609534 DcDc1OperatingStatusCounter 7957;
BA_ "SPN" SG_ 2364609534 DcDc1OperatingStatusCrc 7958;
BA_ "SPN" SG_ 2364609534 DD1PwrLmtDTHghSdCrrnt 8572;
BA_ "SPN" SG_ 2364609534 DD1PwrLmtDTLwSdCrrnt 8573;
BA_ "SPN" SG_ 2364609534 DD1PwrLmtDTHghSdVltgMnmm 8574;
BA_ "SPN" SG_ 2364609534 DD1PwrLmtDTHghSdVltgMxmm 8575;
BA_ "SPN" SG_ 2364609534 DD1PwrLmtDTLwSdVltgMnmm 8576;
BA_ "SPN" SG_ 2364609534 DD1PwrLmtDTLwSdVltgMxmm 8577;
BA_ "SPN" SG_ 2364609534 DD1PwrLmtDTCnvrtrTmprtr 8578;
BA_ "SPN" SG_ 2364609534 DD1PwrLmtDTEltrnFltrTmprtr 8579;
BA_ "SPN" SG_ 2364609534 DD1PwrLmtDTPwrEltrnsTmprtr 8580;
BA_ "SPN" SG_ 2364609534 DD1PwrLmtDTSlBttrTrmnlVltg 8581;
BA_ "SPN" SG_ 2364609534 DD1PwrLmtDTSlBttrTrmnlCrrnt 8583;
BA_ "SPN" SG_ 2364609534 DD1PwrLmtDTSlBttrTrmnlTmprtr 8582;
BA_ "SPN" SG_ 2364609534 DD1PwrLmtDTUndfndRsn 8584;
BA_ "SPN" SG_ 2364609790 DcDc1HighSideCurrent 8588;
BA_ "SPN" SG_ 2364609790 DcDc1HighSideVoltage 8587;
BA_ "SPN" SG_ 2364609790 DcDc1LowSideCurrent 8586;
BA_ "SPN" SG_ 2364609790 DcDc1LowSideVoltage 8585;
BA_ "SPN" SG_ 2364610046 DcDc1SliBatteryTerminalCurrent 8590;
BA_ "SPN" SG_ 2364610046 DcDc1SliBatteryTerminalVoltage 8589;
BA_ "SPN" SG_ 2364610046 DD1SlBttrTrmnlTmprtr 8591;
BA_ "SPN" SG_ 2364610558 DcDc1HighSidePower 8821;
BA_ "SPN" SG_ 2364610558 DcDc1LowSidePower 8820;
BA_ "SPN" SG_ 2364610558 DD1HghSdNgtvTChsssGrndVltg 9587;
BA_ "SPN" SG_ 2364610814 DcDc2LowSideVoltageBuckSetpoint 8893;
BA_ "SPN" SG_ 2364610814 DcDc2OperationalCommand 8892;
BA_ "SPN" SG_ 2364610814 DcDc2ControlCounter 7959;
BA_ "SPN" SG_ 2364610814 DcDc2ControlCrc 7960;
BA_ "SPN" SG_ 2364610814 DD2HghSdVltgBstStpnt 8894;
BA_ "SPN" SG_ 2364610814 DD2LwSdVltgBkDfltStpnt 9516;
BA_ "SPN" SG_ 2364611070 DcDc2HvilStatus 8896;
BA_ "SPN" SG_ 2364611070 DcDc2LoadshedRequest 8897;
BA_ "SPN" SG_ 2364611070 DcDc2OperationalStatus 8895;
BA_ "SPN" SG_ 2364611070 DcDc2OperatingStatusCounter 7961;
BA_ "SPN" SG_ 2364611070 DcDc2OperatingStatusCrc 7962;
BA_ "SPN" SG_ 2364611070 DD2PwrLmtDTHghSdCrrnt 8898;
BA_ "SPN" SG_ 2364611070 DD2PwrLmtDTLwSdCrrnt 8899;
BA_ "SPN" SG_ 2364611070 DD2PwrLmtDTHghSdVltgMnmm 8900;
BA_ "SPN" SG_ 2364611070 DD2PwrLmtDTHghSdVltgMxmm 8901;
BA_ "SPN" SG_ 2364611070 DD2PwrLmtDTLwSdVltgMnmm 8902;
BA_ "SPN" SG_ 2364611070 DD2PwrLmtDTLwSdVltgMxmm 8903;
BA_ "SPN" SG_ 2364611070 DD2PwrLmtDTCnvrtrTmprtr 8904;
BA_ "SPN" SG_ 2364611070 DD2PwrLmtDTEltrnFltrTmprtr 8905;
BA_ "SPN" SG_ 2364611070 DD2PwrLmtDTPwrEltrnsTmprtr 8906;
BA_ "SPN" SG_ 2364611070 DD2PwrLmtDTSlBttrTrmnlVltg 8907;
BA_ "SPN" SG_ 2364611070 DD2PwrLmtDTSlBttrTrmnlCrrnt 8908;
BA_ "SPN" SG_ 2364611070 DD2PwrLmtDTSlBttrTrmnlTmprtr 8909;
BA_ "SPN" SG_ 2364611070 DD2PwrLmtDTUndfndRsn 8910;
BA_ "SPN" SG_ 2364611326 DcDc2HighSideCurrent 8914;
BA_ "SPN" SG_ 2364611326 DcDc2HighSideVoltage 8913;
BA_ "SPN" SG_ 2364611326 DcDc2LowSideCurrent 8912;
BA_ "SPN" SG_ 2364611326 DcDc2LowSideVoltage 8911;
BA_ "SPN" SG_ 2364611582 DcDc2SliBatteryTerminalCurrent 8916;
BA_ "SPN" SG_ 2364611582 DcDc2SliBatteryTerminalVoltage 8915;
BA_ "SPN" SG_ 2364611582 DD2SlBttrTrmnlTmprtr 8917;
BA_ "SPN" SG_ 2364611838 DcDc2HighSidePower 8919;
BA_ "SPN" SG_ 2364611838 DcDc2LowSidePower 8918;
BA_ "SPN" SG_ 2364611838 DD2HghSdNgtvTChsssGrndVltg 9588;
BA_ "SPN" SG_ 2364612094 DcDc3LowSideVoltageBuckSetpoint 8948;
BA_ "SPN" SG_ 2364612094 DcDc3OperationalCommand 8947;
BA_ "SPN" SG_ 2364612094 DcDc3ControlCounter 7963;
BA_ "SPN" SG_ 2364612094 DcDc3ControlCrc 7964;
BA_ "SPN" SG_ 2364612094 DD3HghSdVltgBstStpnt 8949;
BA_ "SPN" SG_ 2364612094 DD3LwSdVltgBkDfltStpnt 9517;
BA_ "SPN" SG_ 2364612350 DcDc3HvilStatus 8951;
BA_ "SPN" SG_ 2364612350 DcDc3LoadshedRequest 8952;
BA_ "SPN" SG_ 2364612350 DcDc3OperationalStatus 8950;
BA_ "SPN" SG_ 2364612350 DcDc3OperatingStatusCounter 7965;
BA_ "SPN" SG_ 2364612350 DcDc3OperatingStatusCrc 7966;
BA_ "SPN" SG_ 2364612350 DD3PwrLmtDTHghSdCrrnt 8953;
BA_ "SPN" SG_ 2364612350 DD3PwrLmtDTLwSdCrrnt 8954;
BA_ "SPN" SG_ 2364612350 DD3PwrLmtDTHghSdVltgMnmm 8955;
BA_ "SPN" SG_ 2364612350 DD3PwrLmtDTHghSdVltgMxmm 8956;
BA_ "SPN" SG_ 2364612350 DD3PwrLmtDTLwSdVltgMnmm 8957;
BA_ "SPN" SG_ 2364612350 DD3PwrLmtDTLwSdVltgMxmm 8958;
BA_ "SPN" SG_ 2364612350 DD3PwrLmtDTCnvrtrTmprtr 8959;
BA_ "SPN" SG_ 2364612350 DD3PwrLmtDTEltrnFltrTmprtr 8960;
BA_ "SPN" SG_ 2364612350 DD3PwrLmtDTPwrEltrnsTmprtr 8961;
BA_ "SPN" SG_ 2364612350 DD3PwrLmtDTSlBttrTrmnlVltg 8962;
BA_ "SPN" SG_ 2364612350 DD3PwrLmtDTSlBttrTrmnlCrrnt 8963;
BA_ "SPN" SG_ 2364612350 DD3PwrLmtDTSlBttrTrmnlTmprtr 8964;
BA_ "SPN" SG_ 2364612350 DD3PwrLmtDTUndfndRsn 8965;
BA_ "SPN" SG_ 2364612606 DcDc3HighSideCurrent 8969;
BA_ "SPN" SG_ 2364612606 DcDc3HighSideVoltage 8968;
BA_ "SPN" SG_ 2364612606 DcDc3LowSideCurrent 8967;
BA_ "SPN" SG_ 2364612606 DcDc3LowSideVoltage 8966;
BA_ "SPN" SG_ 2364612862 DcDc3SliBatteryTerminalCurrent 8971;
BA_ "SPN" SG_ 2364612862 DcDc3SliBatteryTerminalVoltage 8970;
BA_ "SPN" SG_ 2364612862 DD3SlBttrTrmnlTmprtr 8972;
BA_ "SPN" SG_ 2364613118 DcDc3HighSidePower 8974;
BA_ "SPN" SG_ 2364613118 DcDc3LowSidePower 8973;
BA_ "SPN" SG_ 2364613118 DD3HghSdNgtvTChsssGrndVltg 9589;
BA_ "SPN" SG_ 2364613374 DcDc4LowSideVoltageBuckSetpoint 9003;
BA_ "SPN" SG_ 2364613374 DcDc4OperationalCommand 9002;
BA_ "SPN" SG_ 2364613374 DcDc4ControlCounter 8625;
BA_ "SPN" SG_ 2364613374 DcDc4ControlCrc 8626;
BA_ "SPN" SG_ 2364613374 DD4HghSdVltgBstStpnt 9004;
BA_ "SPN" SG_ 2364613374 DD4LwSdVltgBkDfltStpnt 9518;
BA_ "SPN" SG_ 2364613630 DcDc4HvilStatus 9006;
BA_ "SPN" SG_ 2364613630 DcDc4LoadshedRequest 9007;
BA_ "SPN" SG_ 2364613630 DcDc4OperationalStatus 9005;
BA_ "SPN" SG_ 2364613630 DcDc4OperatingStatusCounter 8627;
BA_ "SPN" SG_ 2364613630 DcDc4OperatingStatusCrc 8628;
BA_ "SPN" SG_ 2364613630 DD4PwrLmtDTHghSdCrrnt 9008;
BA_ "SPN" SG_ 2364613630 DD4PwrLmtDTLwSdCrrnt 9009;
BA_ "SPN" SG_ 2364613630 DD4PwrLmtDTHghSdVltgMnmm 9010;
BA_ "SPN" SG_ 2364613630 DD4PwrLmtDTHghSdVltgMxmm 9011;
BA_ "SPN" SG_ 2364613630 DD4PwrLmtDTLwSdVltgMnmm 9012;
BA_ "SPN" SG_ 2364613630 DD4PwrLmtDTLwSdVltgMxmm 9013;
BA_ "SPN" SG_ 2364613630 DD4PwrLmtDTCnvrtrTmprtr 9014;
BA_ "SPN" SG_ 2364613630 DD4PwrLmtDTEltrnFltrTmprtr 9015;
BA_ "SPN" SG_ 2364613630 DD4PwrLmtDTPwrEltrnsTmprtr 9016;
BA_ "SPN" SG_ 2364613630 DD4PwrLmtDTSlBttrTrmnlVltg 9017;
BA_ "SPN" SG_ 2364613630 DD4PwrLmtDTSlBttrTrmnlCrrnt 9018;
BA_ "SPN" SG_ 2364613630 DD4PwrLmtDTSlBttrTrmnlTmprtr 9019;
BA_ "SPN" SG_ 2364613630 DD4PwrLmtDTUndfndRsn 9020;
BA_ "SPN" SG_ 2364613886 DcDc4HighSideCurrent 9024;
BA_ "SPN" SG_ 2364613886 DcDc4HighSideVoltage 9023;
BA_ "SPN" SG_ 2364613886 DcDc4LowSideCurrent 9022;
BA_ "SPN" SG_ 2364613886 DcDc4LowSideVoltage 9021;
BA_ "SPN" SG_ 2364614142 DcDc4SliBatteryTerminalCurrent 9026;
BA_ "SPN" SG_ 2364614142 DcDc4SliBatteryTerminalVoltage 9025;
BA_ "SPN" SG_ 2364614142 DD4SlBttrTrmnlTmprtr 9027;
BA_ "SPN" SG_ 2364614398 DcDc4HighSidePower 9029;
BA_ "SPN" SG_ 2364614398 DcDc4LowSidePower 9028;
BA_ "SPN" SG_ 2364614398 DD4HghSdNgtvTChsssGrndVltg 9590;
BA_ "SPN" SG_ 2364614654 GradeThresholdIndicator1 9181;
BA_ "SPN" SG_ 2364614654 GradeThresholdIndicator2 9182;
BA_ "SPN" SG_ 2364614654 GradeThresholdIndicator3 9183;
BA_ "SPN" SG_ 2364614654 GradeThresholdIndicator4 9184;
BA_ "SPN" SG_ 2364614654 GradeThresholdIndicator5 9185;
BA_ "SPN" SG_ 2364614654 GradeThresholdIndicator6 9186;
BA_ "SPN" SG_ 2364614910 DAAssrInvrtr3DSdPwr 9266;
BA_ "SPN" SG_ 2364614910 DAAssrInvrtr3DSdVltg 9267;
BA_ "SPN" SG_ 2364614910 DAAssrInvrtr3DSdCrrnt 9268;
BA_ "SPN" SG_ 2364614910 DAAssIvt3DSdNtvTCsssGdVt 9584;
BA_ "SPN" SG_ 2364615166 DAAssrInvrtr3IgntnVltg 9269;
BA_ "SPN" SG_ 2364615166 DAAssrInvrtr3UnswthdSlVltg 9270;
BA_ "SPN" SG_ 2364615678 DAAssrInvrtr4DSdPwr 9296;
BA_ "SPN" SG_ 2364615678 DAAssrInvrtr4DSdVltg 9297;
BA_ "SPN" SG_ 2364615678 DAAssrInvrtr4DSdCrrnt 9298;
BA_ "SPN" SG_ 2364615678 DAAssIvt4DSdNtvTCsssGdVt 9585;
BA_ "SPN" SG_ 2364615934 DAAssrInvrtr4IgntnVltg 9299;
BA_ "SPN" SG_ 2364615934 DAAssrInvrtr4UnswthdSlVltg 9300;
BA_ "SPN" SG_ 2364616958 DAAssrInvrtr5DSdPwr 9342;
BA_ "SPN" SG_ 2364616958 DAAssrInvrtr5DSdVltg 9343;
BA_ "SPN" SG_ 2364616958 DAAssrInvrtr5DSdCrrnt 9344;
BA_ "SPN" SG_ 2364616958 DAAssIvt5DSdNtvTCsssGdVt 9586;
BA_ "SPN" SG_ 2364617214 DAAssrInvrtr5IgntnVltg 9345;
BA_ "SPN" SG_ 2364617214 DAAssrInvrtr5UnswthdSlVltg 9346;
BA_ "SPN" SG_ 2365296894 DD4CntrllrInptIgntnVltg 9564;
BA_ "SPN" SG_ 2365296894 DD4CntrllrInptUnswthdSlVltg 9565;
BA_ "SPN" SG_ 2365297150 DD3CntrllrInptIgntnVltg 9562;
BA_ "SPN" SG_ 2365297150 DD3CntrllrInptUnswthdSlVltg 9563;
BA_ "SPN" SG_ 2365297406 DD2CntrllrInptIgntnVltg 9560;
BA_ "SPN" SG_ 2365297406 DD2CntrllrInptUnswthdSlVltg 9561;
